VERSION "$Format:%h$"

NS_ :

BS_:

BU_: APB APP APS BCCEN BDY DAS DBG EAS EPAS EPAS2 EPAS3S EPB EPBM ESP GTW GTWU IBST IC MCU OCS PARK PARK3 RADAR RCM RT3000 SCCM SDM SEC TAS TAS2 TAS2DBG TOOL TPMS VCSEATD VCSEATP

BO_ 861 IBST_dtcMatrix: 8 IBST
 SG_ IBST_dtcIndex M : 0|8@1+ (1,0) [0|255] "" GTW
 SG_ IBST_d000_bmsInitTestFail m0 : 8|2@1+ (1,0) [0|0] "" GTW
 SG_ IBST_d001_bmcSingleTransTest m0 : 10|2@1+ (1,0) [0|0] "" GTW
 SG_ IBST_d002_tle5012SsccrcFail m0 : 12|2@1+ (1,0) [0|0] "" GTW
 SG_ IBST_d003_tle5012Config m0 : 14|2@1+ (1,0) [0|0] "" GTW
 SG_ IBST_d004_deadlMonTaskx1Ovr m0 : 16|2@1+ (1,0) [0|0] "" GTW
 SG_ IBST_d005_ecuWdFltCntTstFls m0 : 18|2@1+ (1,0) [0|0] "" GTW
 SG_ IBST_d006_ecuWdScheduleTout m0 : 20|2@1+ (1,0) [0|0] "" GTW
 SG_ IBST_d007_ecuWdStarttestFls m0 : 22|2@1+ (1,0) [0|0] "" GTW
 SG_ IBST_d008_ecuWdStatusContErr m0 : 24|2@1+ (1,0) [0|0] "" GTW
 SG_ IBST_d009_netOvrvolt m0 : 26|2@1+ (1,0) [0|0] "" GTW
 SG_ IBST_d010_micSpiTout m0 : 28|2@1+ (1,0) [0|0] "" GTW
 SG_ IBST_d011_micSpiTransferErr m0 : 30|2@1+ (1,0) [0|0] "" GTW
 SG_ IBST_d012_netUndvolt m0 : 32|2@1+ (1,0) [0|0] "" GTW
 SG_ IBST_d013_xpassToutErr m0 : 34|2@1+ (1,0) [0|0] "" GTW
 SG_ IBST_d014_rpsOffsEeReadEmpty m0 : 36|2@1+ (1,0) [0|0] "" GTW
 SG_ IBST_d015_rtpEnaHigh m0 : 38|2@1+ (1,0) [0|0] "" GTW
 SG_ IBST_d016_xpassEchoCountErr m0 : 40|2@1+ (1,0) [0|0] "" GTW
 SG_ IBST_d017_preDriveChckFail m0 : 42|2@1+ (1,0) [0|0] "" GTW
 SG_ IBST_d018_ucSafetyFlt m0 : 44|2@1+ (1,0) [0|0] "" GTW
 SG_ IBST_d019_unsupportedHw m0 : 46|2@1+ (1,0) [0|0] "" GTW
 SG_ IBST_d020_voltPreRegModeFld m0 : 48|2@1+ (1,0) [0|0] "" GTW
 SG_ IBST_d021_ubbSupplyLine m0 : 50|2@1+ (1,0) [0|0] "" GTW
 SG_ IBST_d022_stmAswSysTout m0 : 52|2@1+ (1,0) [0|0] "" GTW
 SG_ IBST_d023_stackOvrUndFlow m0 : 54|2@1+ (1,0) [0|0] "" GTW
 SG_ IBST_d024_smmOneReqsInit m0 : 56|2@1+ (1,0) [0|0] "" GTW
 SG_ IBST_d025_ptsSupply m0 : 58|2@1+ (1,0) [0|0] "" GTW
 SG_ IBST_d026_ptsSupplyUndvolt m0 : 60|2@1+ (1,0) [0|0] "" GTW
 SG_ IBST_d027_tempB6Plaus m0 : 62|2@1+ (1,0) [0|0] "" GTW
 SG_ IBST_d028_ecuWdErrCntContErr m1 : 8|2@1+ (1,0) [0|0] "" GTW
 SG_ IBST_d029_bmcShortedGateTest m1 : 10|2@1+ (1,0) [0|0] "" GTW
 SG_ IBST_d030_controllerDevTooBig m1 : 12|2@1+ (1,0) [0|0] "" GTW
 SG_ IBST_d031_ibDtrFail m1 : 14|2@1+ (1,0) [0|0] "" GTW
 SG_ IBST_d032_oc6InitTestFail m1 : 16|2@1+ (1,0) [0|0] "" GTW
 SG_ IBST_d033_oc6Monitor m1 : 18|2@1+ (1,0) [0|0] "" GTW
 SG_ IBST_d034_motorOscillationDet m1 : 20|2@1+ (1,0) [0|0] "" GTW
 SG_ IBST_d035_rpsOffsEeReadFail m1 : 22|2@1+ (1,0) [0|0] "" GTW
 SG_ IBST_d036_sysErrHook m1 : 24|2@1+ (1,0) [0|0] "" GTW
 SG_ IBST_d037_calIdlePosNotPlaus m1 : 26|2@1+ (1,0) [0|0] "" GTW
 SG_ IBST_d038_boostSupUndrvolt m1 : 28|2@1+ (1,0) [0|0] "" GTW
 SG_ IBST_d039_calRoutineAbort m1 : 30|2@1+ (1,0) [0|0] "" GTW
 SG_ IBST_d040_bmcGateUndervoltPro m1 : 32|2@1+ (1,0) [0|0] "" GTW
 SG_ IBST_d041_hswInitPhseUndrvolt m1 : 34|2@1+ (1,0) [0|0] "" GTW
 SG_ IBST_d042_ltmWarnLevelReached m1 : 36|2@1+ (1,0) [0|0] "" GTW
 SG_ IBST_d043_rpsVctrLengthRelErr m1 : 38|2@1+ (1,0) [0|0] "" GTW
 SG_ IBST_d044_b6TempDegradeLevel1 m1 : 40|2@1+ (1,0) [0|0] "" GTW
 SG_ IBST_d045_B6TempDegradeLevel2 m1 : 42|2@1+ (1,0) [0|0] "" GTW
 SG_ IBST_d046_spiAnglOrRawNotUp m1 : 44|2@1+ (1,0) [0|0] "" GTW
 SG_ IBST_d047_dcomIboosterNotInit m1 : 46|2@1+ (1,0) [0|0] "" GTW
 SG_ IBST_d048_unintendMotorReturn m1 : 48|2@1+ (1,0) [0|0] "" GTW
 SG_ IBST_d049_cdmOvrvoltLevel1 m1 : 50|2@1+ (1,0) [0|0] "" GTW
 SG_ IBST_d050_cdmUndrvoltLevel2 m1 : 52|2@1+ (1,0) [0|0] "" GTW
 SG_ IBST_d051_cdmUndrvoltLevel1 m1 : 54|2@1+ (1,0) [0|0] "" GTW
 SG_ IBST_d052_motTrvlRelReadFail m1 : 56|2@1+ (1,0) [0|0] "" GTW
 SG_ IBST_d053_tle5012UnexpReset m1 : 58|2@1+ (1,0) [0|0] "" GTW
 SG_ IBST_d054_bmsGateUndrvolt m1 : 60|2@1+ (1,0) [0|0] "" GTW
 SG_ IBST_d055_kl15HwPlausSw m1 : 62|2@1+ (1,0) [0|0] "" GTW
 SG_ IBST_d056_ibNotShutDownRight m2 : 8|2@1+ (1,0) [0|0] "" GTW
 SG_ IBST_d057_cdmHardUndrvolt m2 : 10|2@1+ (1,0) [0|0] "" GTW
 SG_ IBST_d058_cdmHardOvrvolt m2 : 12|2@1+ (1,0) [0|0] "" GTW
 SG_ IBST_d059_maxTrvlAdjstUpdFail m2 : 14|2@1+ (1,0) [0|0] "" GTW
 SG_ IBST_d060_ltmLimitReached m2 : 16|2@1+ (1,0) [0|0] "" GTW
 SG_ IBST_d061_dcomEcuDefect m2 : 18|2@1+ (1,0) [0|0] "" GTW
 SG_ IBST_d062_inputStroke1RngHigh m2 : 20|2@1+ (1,0) [0|0] "" GTW
 SG_ IBST_d063_inputStroke1RngLow m2 : 22|2@1+ (1,0) [0|0] "" GTW
 SG_ IBST_d064_inputStroke2RngHigh m2 : 24|2@1+ (1,0) [0|0] "" GTW
 SG_ IBST_d065_inputStroke2RngLow m2 : 26|2@1+ (1,0) [0|0] "" GTW
 SG_ IBST_d066_ibSupVoltDivDrift m2 : 28|2@1+ (1,0) [0|0] "" GTW
 SG_ IBST_d067_sOutRodToPressVal m2 : 30|2@1+ (1,0) [0|0] "" GTW
 SG_ IBST_d068_tle5012LifeCnt m2 : 32|2@1+ (1,0) [0|0] "" GTW
 SG_ IBST_d069_cdmExtendedUndrvolt m2 : 34|2@1+ (1,0) [0|0] "" GTW
 SG_ IBST_d070_cdmExtendedOvrvolt m2 : 36|2@1+ (1,0) [0|0] "" GTW
 SG_ IBST_d071_tempB6Ch1LineHigh m2 : 38|2@1+ (1,0) [0|0] "" GTW
 SG_ IBST_d072_tempB6Ch1LineLow m2 : 40|2@1+ (1,0) [0|0] "" GTW
 SG_ IBST_d073_tempB6Ch2LineHigh m2 : 42|2@1+ (1,0) [0|0] "" GTW
 SG_ IBST_d074_tempB6Ch2LineLow m2 : 44|2@1+ (1,0) [0|0] "" GTW
 SG_ IBST_d075_hevSwitchOffDcom m2 : 46|2@1+ (1,0) [0|0] "" GTW
 SG_ IBST_d076_tle5012VoltFail m2 : 48|2@1+ (1,0) [0|0] "" GTW
 SG_ IBST_d077_bcsFltCurrentHigh m2 : 50|2@1+ (1,0) [0|0] "" GTW
 SG_ IBST_d078_bcsFltCurrentLow m2 : 52|2@1+ (1,0) [0|0] "" GTW
 SG_ IBST_d079_ecuSupVoltDivDrift m2 : 54|2@1+ (1,0) [0|0] "" GTW
 SG_ IBST_d080_inputstroke1Grad m2 : 56|2@1+ (1,0) [0|0] "" GTW
 SG_ IBST_d081_pts1Err m2 : 58|2@1+ (1,0) [0|0] "" GTW
 SG_ IBST_d082_pts1LineGnd m2 : 60|2@1+ (1,0) [0|0] "" GTW
 SG_ IBST_d083_pts1LineHigh m2 : 62|2@1+ (1,0) [0|0] "" GTW
 SG_ IBST_d084_inputStroke2Grad m3 : 8|2@1+ (1,0) [0|0] "" GTW
 SG_ IBST_d085_pts2Err m3 : 10|2@1+ (1,0) [0|0] "" GTW
 SG_ IBST_d086_pts2LineGnd m3 : 12|2@1+ (1,0) [0|0] "" GTW
 SG_ IBST_d087_pts2LineHigh m3 : 14|2@1+ (1,0) [0|0] "" GTW
 SG_ IBST_d088_faildevInputStroke m3 : 16|2@1+ (1,0) [0|0] "" GTW
 SG_ IBST_d089_ptsOffsTooHigh m3 : 18|2@1+ (1,0) [0|0] "" GTW
 SG_ IBST_d090_pbistErr m3 : 20|2@1+ (1,0) [0|0] "" GTW
 SG_ IBST_d091_ramInitErr m3 : 22|2@1+ (1,0) [0|0] "" GTW
 SG_ IBST_d092_ramsinlgeFlt m3 : 24|2@1+ (1,0) [0|0] "" GTW
 SG_ IBST_d093_bertFlt m3 : 26|2@1+ (1,0) [0|0] "" GTW
 SG_ IBST_d094_CalDataNotPlaus m3 : 28|2@1+ (1,0) [0|0] "" GTW
 SG_ IBST_d095_canEHwError m3 : 30|2@1+ (1,0) [0|0] "" GTW
 SG_ IBST_d096_canETout m3 : 32|2@1+ (1,0) [0|0] "" GTW
 SG_ IBST_d097_cpuException m3 : 34|2@1+ (1,0) [0|0] "" GTW
 SG_ IBST_d098_ecuBandGap m3 : 36|2@1+ (1,0) [0|0] "" GTW
 SG_ IBST_d099_ecuBmsOnWhileWdTout m3 : 38|2@1+ (1,0) [0|0] "" GTW
 SG_ IBST_d100_ecuErrpinCntTstFls m3 : 40|2@1+ (1,0) [0|0] "" GTW
 SG_ IBST_d101_ecuHetException m3 : 42|2@1+ (1,0) [0|0] "" GTW
 SG_ IBST_d102_ecuHetTuAddErr m3 : 44|2@1+ (1,0) [0|0] "" GTW
 SG_ IBST_d103_ecuHetTuBusErr m3 : 46|2@1+ (1,0) [0|0] "" GTW
 SG_ IBST_d104_ecuHetTuBusyErr m3 : 48|2@1+ (1,0) [0|0] "" GTW
 SG_ IBST_d105_ecuHetTuException m3 : 50|2@1+ (1,0) [0|0] "" GTW
 SG_ IBST_d106_ecuTaskMissing m3 : 52|2@1+ (1,0) [0|0] "" GTW
 SG_ IBST_d107_hetRefError m3 : 54|2@1+ (1,0) [0|0] "" GTW
 SG_ IBST_d108_micInitSpiTstFld m3 : 56|2@1+ (1,0) [0|0] "" GTW
 SG_ IBST_d109_micInitSpiTransfErr m3 : 58|2@1+ (1,0) [0|0] "" GTW
 SG_ IBST_d110_micIntMonGenBitMon m3 : 60|2@1+ (1,0) [0|0] "" GTW
 SG_ IBST_d111_micIntVoltMonFld m3 : 62|2@1+ (1,0) [0|0] "" GTW
 SG_ IBST_d112_motPosTrvlReadEmpty m4 : 8|2@1+ (1,0) [0|0] "" GTW
 SG_ IBST_d113_motAngBoundReadEmpt m4 : 10|2@1+ (1,0) [0|0] "" GTW
 SG_ IBST_d114_motShaftShiftDetect m4 : 12|2@1+ (1,0) [0|0] "" GTW
 SG_ IBST_d115_osErrHook m4 : 14|2@1+ (1,0) [0|0] "" GTW
 SG_ IBST_d116_pdurEInitFail m4 : 16|2@1+ (1,0) [0|0] "" GTW
 SG_ IBST_d117_pdurEPduInstLost m4 : 18|2@1+ (1,0) [0|0] "" GTW
 SG_ IBST_d118_pts1OffsEeReadEmpty m4 : 20|2@1+ (1,0) [0|0] "" GTW
 SG_ IBST_d119_pts2OffsEeReadEmpty m4 : 22|2@1+ (1,0) [0|0] "" GTW
 SG_ IBST_d120_rpsOffsXEeReadFail m4 : 24|2@1+ (1,0) [0|0] "" GTW
 SG_ IBST_d121_rpsOffsYEeReadFail m4 : 26|2@1+ (1,0) [0|0] "" GTW
 SG_ IBST_d122_rpsSynchEeReadFail m4 : 28|2@1+ (1,0) [0|0] "" GTW
 SG_ IBST_d123_rpsAnglRecalcErr m4 : 30|2@1+ (1,0) [0|0] "" GTW
 SG_ IBST_d124_motTrvlRelWriteFail m4 : 32|2@1+ (1,0) [0|0] "" GTW
 SG_ IBST_d125_motTrvlRelReadEmpty m4 : 34|2@1+ (1,0) [0|0] "" GTW
 SG_ IBST_d126_ptsEeReadEmpty m4 : 36|2@1+ (1,0) [0|0] "" GTW
 SG_ IBST_d127_ecuAdcConversionErr m4 : 38|2@1+ (1,0) [0|0] "" GTW
 SG_ IBST_d128_ecuAdcSelftestErr m4 : 40|2@1+ (1,0) [0|0] "" GTW
 SG_ IBST_d129_ccmFlt m4 : 42|2@1+ (1,0) [0|0] "" GTW
 SG_ IBST_d130_ecuRomCheck m4 : 44|2@1+ (1,0) [0|0] "" GTW
 SG_ IBST_d131_esmNmiFlt m4 : 46|2@1+ (1,0) [0|0] "" GTW
 SG_ IBST_d132_esmSafetyFlt m4 : 48|2@1+ (1,0) [0|0] "" GTW
 SG_ IBST_d133_motPosTrvlReadFail m4 : 50|2@1+ (1,0) [0|0] "" GTW
 SG_ IBST_d134_motPosTrvlWriteFail m4 : 52|2@1+ (1,0) [0|0] "" GTW
 SG_ IBST_d135_motAnglBndReadErr m4 : 54|2@1+ (1,0) [0|0] "" GTW
 SG_ IBST_d136_motAnglBndWriteErr m4 : 56|2@1+ (1,0) [0|0] "" GTW
 SG_ IBST_d137_motAnglGradTooLarge m4 : 58|2@1+ (1,0) [0|0] "" GTW
 SG_ IBST_d138_pdmCustomerIdMis m4 : 60|2@1+ (1,0) [0|0] "" GTW
 SG_ IBST_d139_pdmDtFormatMis m4 : 62|2@1+ (1,0) [0|0] "" GTW
 SG_ IBST_d140_pdmOutOfMemory m5 : 8|2@1+ (1,0) [0|0] "" GTW
 SG_ IBST_d141_pdmFieldSizeMis m5 : 10|2@1+ (1,0) [0|0] "" GTW
 SG_ IBST_d142_pdmHwAcsErr m5 : 12|2@1+ (1,0) [0|0] "" GTW
 SG_ IBST_d143_pdmInternalHWErr m5 : 14|2@1+ (1,0) [0|0] "" GTW
 SG_ IBST_d144_ptsCalHysWritFail m5 : 16|2@1+ (1,0) [0|0] "" GTW
 SG_ IBST_d145_ptsCalValuesChkFail m5 : 18|2@1+ (1,0) [0|0] "" GTW
 SG_ IBST_d146_pts1CalEeReadFail m5 : 20|2@1+ (1,0) [0|0] "" GTW
 SG_ IBST_d147_pts1CalEeWriteFail m5 : 22|2@1+ (1,0) [0|0] "" GTW
 SG_ IBST_d148_rpsFailCompErr m5 : 24|2@1+ (1,0) [0|0] "" GTW
 SG_ IBST_d149_pts1OffsEeWriteFail m5 : 26|2@1+ (1,0) [0|0] "" GTW
 SG_ IBST_d150_pts2CalEeReadFail m5 : 28|2@1+ (1,0) [0|0] "" GTW
 SG_ IBST_d151_pts2CalEeWriteFail m5 : 30|2@1+ (1,0) [0|0] "" GTW
 SG_ IBST_d152_pts2OffsEeReadFail m5 : 32|2@1+ (1,0) [0|0] "" GTW
 SG_ IBST_d153_pts2OffsEeWriteFail m5 : 34|2@1+ (1,0) [0|0] "" GTW
 SG_ IBST_d154_rpsOffsXEeReadEmpty m5 : 36|2@1+ (1,0) [0|0] "" GTW
 SG_ IBST_d155_rpsOffsXEeWriteFail m5 : 38|2@1+ (1,0) [0|0] "" GTW
 SG_ IBST_d156_rpsOffsYEeReadEmpty m5 : 40|2@1+ (1,0) [0|0] "" GTW
 SG_ IBST_d157_rpsOffsYEeWriteFail m5 : 42|2@1+ (1,0) [0|0] "" GTW
 SG_ IBST_d158_rpsSynchEeReadEmpty m5 : 44|2@1+ (1,0) [0|0] "" GTW
 SG_ IBST_d159_rpsSynchEeWriteFail m5 : 46|2@1+ (1,0) [0|0] "" GTW
 SG_ IBST_d160_assertionFail m5 : 48|2@1+ (1,0) [0|0] "" GTW
 SG_ IBST_d161_comsclBrkPrsPduLen m5 : 50|2@1+ (1,0) [0|0] "" GTW
 SG_ IBST_d162_comsclBrkPrsPduTout m5 : 52|2@1+ (1,0) [0|0] "" GTW
 SG_ IBST_d163_comsclEspIb1CntErr m5 : 54|2@1+ (1,0) [0|0] "" GTW
 SG_ IBST_d164_comsclEspIb1CsErr m5 : 56|2@1+ (1,0) [0|0] "" GTW
 SG_ IBST_d165_comsclEspIb1DlcErr m5 : 58|2@1+ (1,0) [0|0] "" GTW
 SG_ IBST_d166_comsclEspIb1Tout m5 : 60|2@1+ (1,0) [0|0] "" GTW
 SG_ IBST_d167_comsclEspIb2CntErr m5 : 62|2@1+ (1,0) [0|0] "" GTW
 SG_ IBST_d168_comsclEspIb2CsErr m6 : 8|2@1+ (1,0) [0|0] "" GTW
 SG_ IBST_d169_comsclEspIb2DlcErr m6 : 10|2@1+ (1,0) [0|0] "" GTW
 SG_ IBST_d170_comsclEspIb2Tout m6 : 12|2@1+ (1,0) [0|0] "" GTW
 SG_ IBST_d171_comsclEspIb3CntErr m6 : 14|2@1+ (1,0) [0|0] "" GTW
 SG_ IBST_d172_comsclEspIb3CsErr m6 : 16|2@1+ (1,0) [0|0] "" GTW
 SG_ IBST_d173_comsclEspIb3DlcErr m6 : 18|2@1+ (1,0) [0|0] "" GTW
 SG_ IBST_d174_comsclEspIb3Tout m6 : 20|2@1+ (1,0) [0|0] "" GTW
 SG_ IBST_d175_comsclGtwEsp1CntErr m6 : 22|2@1+ (1,0) [0|0] "" GTW
 SG_ IBST_d176_comsclGtwEsp1CsErr m6 : 24|2@1+ (1,0) [0|0] "" GTW
 SG_ IBST_d177_comsclGtwEsp1Corrpt m6 : 26|2@1+ (1,0) [0|0] "" GTW
 SG_ IBST_d178_comsclGtwEsp1Tout m6 : 28|2@1+ (1,0) [0|0] "" GTW
 SG_ IBST_d179_dcomSmrtActuNotInit m6 : 30|2@1+ (1,0) [0|0] "" GTW
 SG_ IBST_d180_rpsLengthAbsolHigh m6 : 32|2@1+ (1,0) [0|0] "" GTW
 SG_ IBST_d181_rpsLengthAbsolLow m6 : 34|2@1+ (1,0) [0|0] "" GTW
 SG_ IBST_d182_shutDownEeReadFail m6 : 36|2@1+ (1,0) [0|0] "" GTW
 SG_ IBST_d183_shutDownEeWriteFail m6 : 38|2@1+ (1,0) [0|0] "" GTW
 SG_ IBST_d184_maxTrvlAdjstReadErr m6 : 40|2@1+ (1,0) [0|0] "" GTW
 SG_ IBST_d185_psOffsMcEeReadFail m6 : 42|2@1+ (1,0) [0|0] "" GTW
 SG_ IBST_d186_psOffsMcEeWriteFail m6 : 44|2@1+ (1,0) [0|0] "" GTW
 SG_ IBST_d187_ltmSelfProtDeact m6 : 46|2@1+ (1,0) [0|0] "" GTW
 SG_ IBST_d188_pts1OffsEeReadFail m6 : 48|2@1+ (1,0) [0|0] "" GTW
 SG_ IBST_d189_diffStrokeRange m6 : 50|2@1+ (1,0) [0|0] "" GTW
 SG_ IBST_d190_notProgVin m6 : 52|2@1+ (1,0) [0|0] "" GTW
 SG_ IBST_d191_plausVin m6 : 54|2@1+ (1,0) [0|0] "" GTW
 SG_ IBST_d192_dlCorCSumVin m6 : 56|2@1+ (1,0) [0|0] "" GTW
 SG_ IBST_d193_ToutVin m6 : 58|2@1+ (1,0) [0|0] "" GTW
 SG_ IBST_d194_ecuEnableB6Fail m6 : 60|2@1+ (1,0) [0|0] "" GTW
 SG_ IBST_d195_ecuIbEnContErr m6 : 62|2@1+ (1,0) [0|0] "" GTW
 SG_ IBST_d196_sclEspIb1pEstMax m7 : 8|2@1+ (1,0) [0|0] "" GTW
 SG_ IBST_d197_sclEspIb1VehSpd m7 : 10|2@1+ (1,0) [0|0] "" GTW
 SG_ IBST_d198_sclEspIb2pLimExt m7 : 12|2@1+ (1,0) [0|0] "" GTW
 SG_ IBST_d199_sclEspIb2qTarExt m7 : 14|2@1+ (1,0) [0|0] "" GTW
 SG_ IBST_d200_sclEspIb3pFBlend m7 : 16|2@1+ (1,0) [0|0] "" GTW
 SG_ IBST_d201_sclEspIb3pMc1 m7 : 18|2@1+ (1,0) [0|0] "" GTW
 SG_ IBST_d202_sclEspIb3pTarDriver m7 : 20|2@1+ (1,0) [0|0] "" GTW
 SG_ IBST_d203_netBusOffNet0 m7 : 22|2@1+ (1,0) [0|0] "" GTW
 SG_ IBST_d204_netErrPassivNet0 m7 : 24|2@1+ (1,0) [0|0] "" GTW
 SG_ IBST_d205_netBusOffNet1 m7 : 26|2@1+ (1,0) [0|0] "" GTW
 SG_ IBST_d206_netErrPassivNet1 m7 : 28|2@1+ (1,0) [0|0] "" GTW
 SG_ IBST_d207_maxStrokeReached m7 : 30|2@1+ (1,0) [0|0] "" GTW
 SG_ IBST_d208_sysSwClockMismatch m7 : 32|2@1+ (1,0) [0|0] "" GTW
 SG_ IBST_d209_comsclGtwOdoCorrpt m7 : 34|2@1+ (1,0) [0|0] "" GTW
 SG_ IBST_d210_comsclGtwStatCorrpt m7 : 36|2@1+ (1,0) [0|0] "" GTW
 SG_ IBST_d211_comsclEpbStatCorrpt m7 : 38|2@1+ (1,0) [0|0] "" GTW
 SG_ IBST_d212_comsclGtwOdoTout m7 : 40|2@1+ (1,0) [0|0] "" GTW
 SG_ IBST_d213_comsclGtwStatTout m7 : 42|2@1+ (1,0) [0|0] "" GTW
 SG_ IBST_d214_comsclEpbStatTout m7 : 44|2@1+ (1,0) [0|0] "" GTW
 SG_ IBST_d215_comSclEpbStatCsErr m7 : 46|2@1+ (1,0) [0|0] "" GTW
 SG_ IBST_d216_comSclEpbStatCntFlt m7 : 48|2@1+ (1,0) [0|0] "" GTW
 SG_ IBST_d217_comSclDiTrq1Tout m7 : 50|2@1+ (1,0) [0|0] "" GTW
 SG_ IBST_d218_comSclDiTrq1Corrpt m7 : 52|2@1+ (1,0) [0|0] "" GTW
 SG_ IBST_d219_comSclDiTrq1CsErr m7 : 54|2@1+ (1,0) [0|0] "" GTW
 SG_ IBST_d220_comSclDiTrq1CntFlt m7 : 56|2@1+ (1,0) [0|0] "" GTW

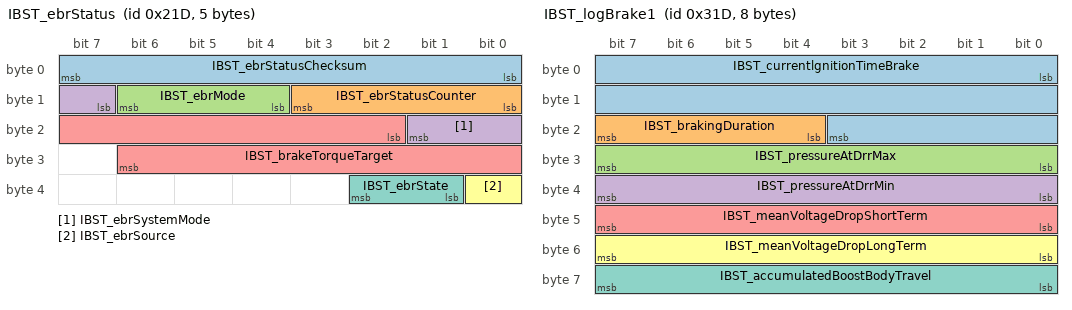
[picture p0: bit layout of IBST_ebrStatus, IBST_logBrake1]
BO_ 541 IBST_ebrStatus: 5 IBST
 SG_ IBST_ebrStatusChecksum : 0|8@1+ (1,0) [0|255] "" GTW
 SG_ IBST_ebrStatusCounter : 8|4@1+ (1,0) [0|15] "" GTW
 SG_ IBST_ebrMode : 12|3@1+ (1,0) [0|7] "" GTW
 SG_ IBST_ebrSystemMode : 15|3@1+ (1,0) [0|7] "" GTW
 SG_ IBST_brakeTorqueTarget : 18|13@1+ (2,0) [0|16382] "Nm" GTW
 SG_ IBST_ebrSource : 32|1@1+ (1,0) [0|2] "" GTW
 SG_ IBST_ebrState : 33|2@1+ (1,0) [0|3] "" GTW

BO_ 813 IBST_info: 8 IBST
 SG_ IBST_infoIndex M : 0|8@1+ (1,0) [0|255] "" GTW,GTWU
 SG_ IBST_buildType m10 : 8|8@1+ (1,0) [0|255] "" GTW
 SG_ IBST_componentId m10 : 48|16@1+ (1,0) [0|65535] "" GTW
 SG_ IBST_pcbaId m11 : 16|8@1+ (1,0) [0|0] "" GTW,GTWU
 SG_ IBST_assemblyId m11 : 24|8@1+ (1,0) [0|0] "" GTW,GTWU
 SG_ IBST_usageId m11 : 32|16@1+ (1,0) [0|0] "" GTW,GTWU
 SG_ IBST_applicationCrc m13 : 32|32@1+ (1,0) [0|0] "" GTW,GTWU
 SG_ IBST_udsProtocolVersion m20 : 8|8@1+ (1,0) [0|0] "" GTW,GTWU
 SG_ IBST_bootloaderCrc m20 : 32|32@1+ (1,0) [0|0] "" GTW
 SG_ IBST_variantCrc m22 : 32|32@1+ (1,0) [0|0] "" GTW,GTWU

BO_ 797 IBST_logBrake1: 8 IBST
 SG_ IBST_currentlgnitionTimeBrake : 0|20@1+ (0.1,0) [0|86400] "sec" Vector__XXX
 SG_ IBST_brakingDuration : 20|4@1+ (1,0) [0|15] "" Vector__XXX
 SG_ IBST_pressureAtDrrMax : 24|8@1+ (1,0) [0|250] "bar" Vector__XXX
 SG_ IBST_pressureAtDrrMin : 32|8@1+ (1,0) [0|250] "bar" Vector__XXX
 SG_ IBST_meanVoltageDropShortTerm : 40|8@1+ (0.01,0) [0|1.5] "V" Vector__XXX
 SG_ IBST_meanVoltageDropLongTerm : 48|8@1+ (0.01,0) [0|1.5] "V" Vector__XXX
 SG_ IBST_accumulatedBoostBodyTravel : 56|8@1+ (10,0) [0|2550] "mm" Vector__XXX

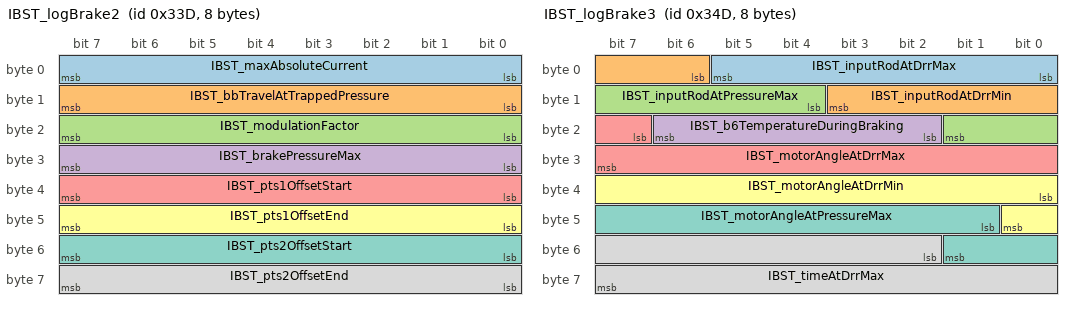
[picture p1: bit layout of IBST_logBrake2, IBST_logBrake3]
BO_ 829 IBST_logBrake2: 8 IBST
 SG_ IBST_maxAbsoluteCurrent : 0|8@1+ (1,0) [0|255] "A" Vector__XXX
 SG_ IBST_bbTravelAtTrappedPressure : 8|8@1+ (0.1,0) [0|20] "mm" Vector__XXX
 SG_ IBST_modulationFactor : 16|8@1+ (0.1,0) [0|25.5] "1" Vector__XXX
 SG_ IBST_brakePressureMax : 24|8@1+ (1,0) [0|250] "bar" Vector__XXX
 SG_ IBST_pts1OffsetStart : 32|8@1+ (0.01,-0.5) [-0.5|1] "mm" Vector__XXX
 SG_ IBST_pts1OffsetEnd : 40|8@1+ (0.01,-0.5) [-0.5|1] "mm" Vector__XXX
 SG_ IBST_pts2OffsetStart : 48|8@1+ (0.01,-0.5) [-0.5|1] "mm" Vector__XXX
 SG_ IBST_pts2OffsetEnd : 56|8@1+ (0.01,-0.5) [-0.5|1] "mm" Vector__XXX

BO_ 845 IBST_logBrake3: 8 IBST
 SG_ IBST_inputRodAtDrrMax : 0|6@1+ (1,0) [0|50] "mm" Vector__XXX
 SG_ IBST_inputRodAtDrrMin : 6|6@1+ (1,0) [0|50] "mm" Vector__XXX
 SG_ IBST_inputRodAtPressureMax : 12|6@1+ (1,0) [0|50] "mm" Vector__XXX
 SG_ IBST_b6TemperatureDuringBraking : 18|5@1+ (10,-40) [-40|150] "C" Vector__XXX
 SG_ IBST_motorAngleAtDrrMax : 23|9@1+ (0.25,0) [0|127] "rad" Vector__XXX
 SG_ IBST_motorAngleAtDrrMin : 32|9@1+ (0.25,0) [0|127] "rad" Vector__XXX
 SG_ IBST_motorAngleAtPressureMax : 41|9@1+ (0.25,0) [0|127] "rad" Vector__XXX
 SG_ IBST_timeAtDrrMax : 50|14@1+ (0.2,0) [0|1800] "sec" Vector__XXX

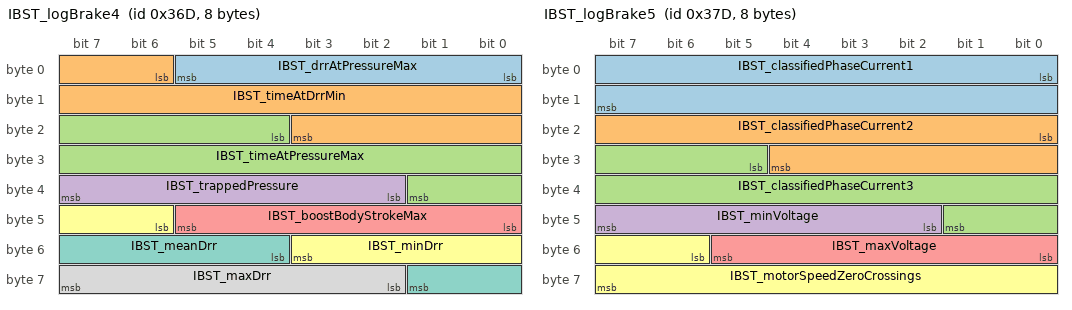
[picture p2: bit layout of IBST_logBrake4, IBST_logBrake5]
BO_ 877 IBST_logBrake4: 8 IBST
 SG_ IBST_drrAtPressureMax : 0|6@1+ (0.1,-3) [-3|3] "mm" Vector__XXX
 SG_ IBST_timeAtDrrMin : 6|14@1+ (0.2,0) [0|1800] "sec" Vector__XXX
 SG_ IBST_timeAtPressureMax : 20|14@1+ (0.2,0) [0|1800] "sec" Vector__XXX
 SG_ IBST_trappedPressure : 34|6@1+ (0.5,0) [0|20] "bar" Vector__XXX
 SG_ IBST_boostBodyStrokeMax : 40|6@1+ (1,0) [0|50] "mm" Vector__XXX
 SG_ IBST_minDrr : 46|6@1+ (0.1,-3) [-3|3] "mm" Vector__XXX
 SG_ IBST_meanDrr : 52|6@1+ (0.1,-3) [-3|3] "mm" Vector__XXX
 SG_ IBST_maxDrr : 58|6@1+ (0.1,-3) [-3|3] "mm" Vector__XXX

BO_ 893 IBST_logBrake5: 8 IBST
 SG_ IBST_classifiedPhaseCurrent1 : 0|16@1+ (1,0) [0|65535] "" Vector__XXX
 SG_ IBST_classifiedPhaseCurrent2 : 16|13@1+ (1,0) [0|8191] "" Vector__XXX
 SG_ IBST_classifiedPhaseCurrent3 : 29|13@1+ (1,0) [0|8191] "" Vector__XXX
 SG_ IBST_minVoltage : 42|6@1+ (0.5,0) [0|20] "V" Vector__XXX
 SG_ IBST_maxVoltage : 48|6@1+ (0.5,0) [0|20] "V" Vector__XXX
 SG_ IBST_motorSpeedZeroCrossings : 54|10@1+ (1,0) [0|1000] "" Vector__XXX

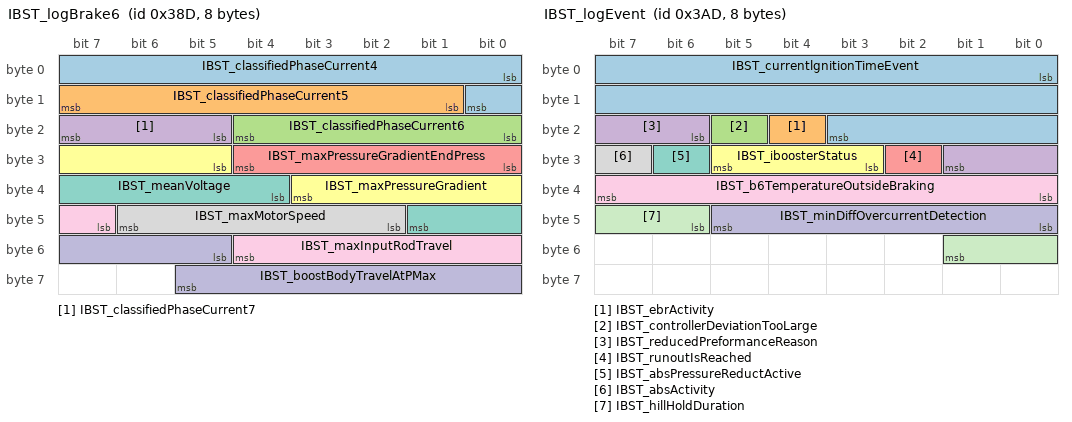
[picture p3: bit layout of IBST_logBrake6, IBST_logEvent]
BO_ 909 IBST_logBrake6: 8 IBST
 SG_ IBST_classifiedPhaseCurrent4 : 0|9@1+ (1,0) [0|511] "" Vector__XXX
 SG_ IBST_classifiedPhaseCurrent5 : 9|7@1+ (1,0) [0|127] "" Vector__XXX
 SG_ IBST_classifiedPhaseCurrent6 : 16|5@1+ (1,0) [0|31] "" Vector__XXX
 SG_ IBST_classifiedPhaseCurrent7 : 21|3@1+ (1,0) [0|7] "" Vector__XXX
 SG_ IBST_maxPressureGradientEndPress : 24|5@1+ (10,0) [0|200] "bar" Vector__XXX
 SG_ IBST_maxPressureGradient : 29|7@1+ (20,0) [0|2000] "bar/s" Vector__XXX
 SG_ IBST_meanVoltage : 36|6@1+ (0.5,0) [0|20] "V" Vector__XXX
 SG_ IBST_maxMotorSpeed : 42|5@1+ (20,0) [0|600] "rad/s" Vector__XXX
 SG_ IBST_maxInputRodTravel : 47|6@1+ (1,0) [0|50] "mm" Vector__XXX
 SG_ IBST_boostBodyTravelAtPMax : 53|9@1+ (0.1,0) [0|50] "mm" Vector__XXX

BO_ 941 IBST_logEvent: 8 IBST
 SG_ IBST_currentlgnitionTimeEvent : 0|20@1+ (0.1,0) [0|86400] "sec" Vector__XXX
 SG_ IBST_ebrActivity : 20|1@1+ (1,0) [0|1] "" Vector__XXX
 SG_ IBST_controllerDeviationTooLarge : 21|1@1+ (1,0) [0|1] "" Vector__XXX
 SG_ IBST_reducedPreformanceReason : 22|4@1+ (1,0) [0|15] "" Vector__XXX
 SG_ IBST_runoutIsReached : 26|1@1+ (1,0) [0|1] "" Vector__XXX
 SG_ IBST_iboosterStatus : 27|3@1+ (1,0) [0|7] "" Vector__XXX
 SG_ IBST_absPressureReductActive : 30|1@1+ (1,0) [0|1] "" Vector__XXX
 SG_ IBST_absActivity : 31|1@1+ (1,0) [0|1] "" Vector__XXX
 SG_ IBST_b6TemperatureOutsideBraking : 32|8@1+ (10,-40) [-40|150] "C" Vector__XXX
 SG_ IBST_minDiffOvercurrentDetection : 40|6@1+ (0.00390625,0) [0|0.203125] "V" Vector__XXX
 SG_ IBST_hillHoldDuration : 46|4@1+ (0.2,0) [0|2] "sec" Vector__XXX

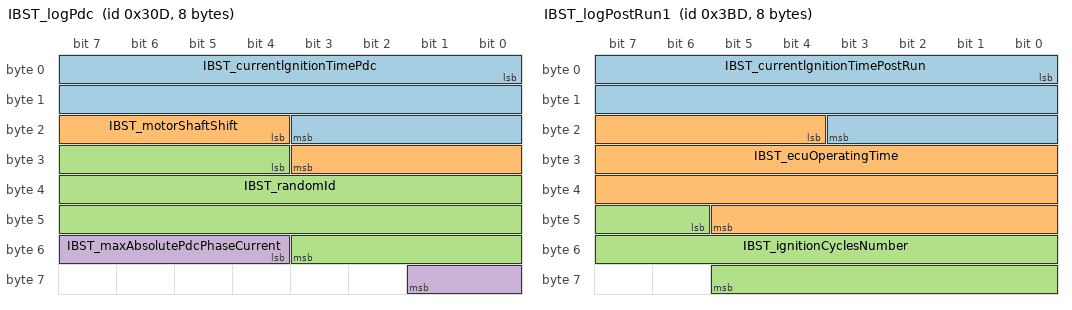
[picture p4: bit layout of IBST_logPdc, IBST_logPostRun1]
BO_ 781 IBST_logPdc: 8 IBST
 SG_ IBST_currentlgnitionTimePdc : 0|20@1+ (0.1,0) [0|86400] "sec" Vector__XXX
 SG_ IBST_motorShaftShift : 20|8@1+ (10,-60) [-60|2490] "deg" Vector__XXX
 SG_ IBST_randomId : 28|24@1+ (1,0) [0|16777215] "" Vector__XXX
 SG_ IBST_maxAbsolutePdcPhaseCurrent : 52|6@1+ (1,0) [0|50] "A" Vector__XXX

BO_ 957 IBST_logPostRun1: 8 IBST
 SG_ IBST_currentlgnitionTimePostRun : 0|20@1+ (0.1,0) [0|86400] "sec" Vector__XXX
 SG_ IBST_ecuOperatingTime : 20|26@1+ (1,0) [0|67108863] "sec" Vector__XXX
 SG_ IBST_ignitionCyclesNumber : 46|16@1+ (1,0) [0|65535] "" Vector__XXX

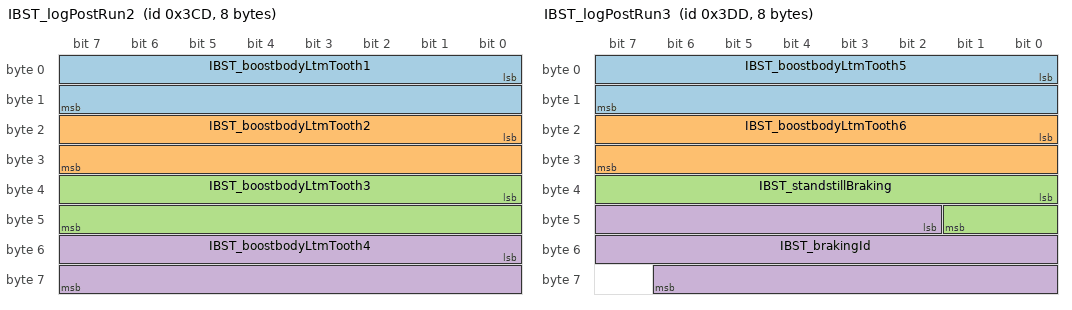
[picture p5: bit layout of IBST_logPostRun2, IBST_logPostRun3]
BO_ 973 IBST_logPostRun2: 8 IBST
 SG_ IBST_boostbodyLtmTooth1 : 0|16@1+ (0.0039,0) [0|255] "1" Vector__XXX
 SG_ IBST_boostbodyLtmTooth2 : 16|16@1+ (0.0039,0) [0|255] "1" Vector__XXX
 SG_ IBST_boostbodyLtmTooth3 : 32|16@1+ (0.0039,0) [0|255] "1" Vector__XXX
 SG_ IBST_boostbodyLtmTooth4 : 48|16@1+ (0.0039,0) [0|255] "1" Vector__XXX

BO_ 989 IBST_logPostRun3: 8 IBST
 SG_ IBST_boostbodyLtmTooth5 : 0|16@1+ (0.0039,0) [0|255] "1" Vector__XXX
 SG_ IBST_boostbodyLtmTooth6 : 16|16@1+ (0.0039,0) [0|255] "1" Vector__XXX
 SG_ IBST_standstillBraking : 32|10@1+ (1,0) [0|1000] "" Vector__XXX
 SG_ IBST_brakingId : 42|21@1+ (1,0) [0|2000000] "" Vector__XXX

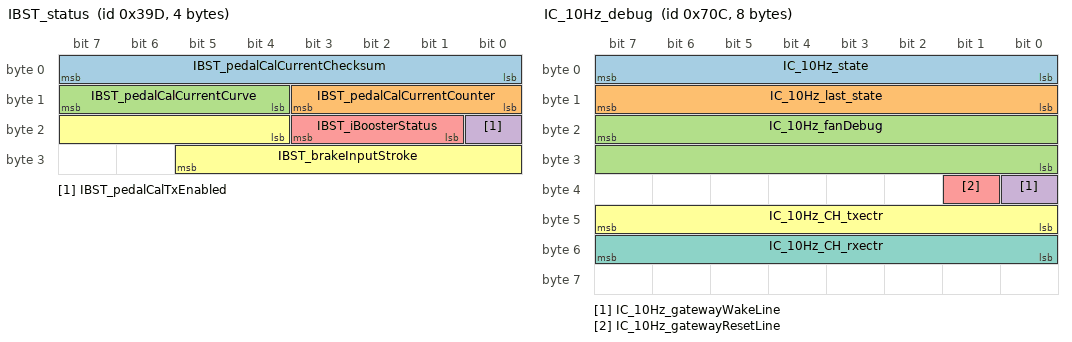
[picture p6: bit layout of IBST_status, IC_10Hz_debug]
BO_ 925 IBST_status: 4 IBST
 SG_ IBST_pedalCalCurrentChecksum : 0|8@1+ (1,0) [0|255] "" GTW
 SG_ IBST_pedalCalCurrentCounter : 8|4@1+ (1,0) [0|15] "" GTW
 SG_ IBST_pedalCalCurrentCurve : 12|4@1+ (1,0) [0|15] "1" GTW
 SG_ IBST_pedalCalTxEnabled : 16|1@1+ (1,0) [0|1] "1" GTW
 SG_ IBST_iBoosterStatus : 17|3@1+ (1,0) [0|0] "" GTW
 SG_ IBST_brakeInputStroke : 20|10@1+ (0.05,-0.5) [-0.5|50.55] "mm" GTW

BO_ 1629 IBST_udsResponse: 8 IBST
 SG_ IBST_udsResponseData : 7|64@0+ (1,0) [0|0] "" GTW,GTWU

BO_ 1804 IC_10Hz_debug: 8 IC
 SG_ IC_10Hz_state : 7|8@0+ (1,0) [0|0] "" DBG
 SG_ IC_10Hz_last_state : 15|8@0+ (1,0) [0|0] "" DBG
 SG_ IC_10Hz_fanDebug : 23|16@0+ (1,0) [0|0] "" DBG
 SG_ IC_10Hz_gatewayWakeLine : 32|1@1+ (1,0) [0|0] "" DBG
 SG_ IC_10Hz_gatewayResetLine : 33|1@1+ (1,0) [0|0] "" DBG
 SG_ IC_10Hz_CH_txectr : 40|8@1+ (1,0) [0|0] "" DBG
 SG_ IC_10Hz_CH_rxectr : 48|8@1+ (1,0) [0|0] "" DBG

BO_ 1420 IC_alertLog: 8 IC
 SG_ IC_alertID M : 0|14@1+ (1,0) [0|0] "" GTW
 SG_ IC_alertType : 14|2@1+ (1,0) [0|0] "" GTW
 SG_ IC_canAddress m3 : 16|12@1+ (1,0) [0|0] "" GTW
 SG_ IC_canErrorType m3 : 28|4@1+ (1,0) [0|0] "" GTW
 SG_ IC_canErrorWord1 m3 : 32|16@1+ (1,0) [0|0] "" GTW
 SG_ IC_canErrorWord2 m3 : 48|16@1+ (1,0) [0|0] "" GTW
 SG_ IC_canRxErrorCount m11 : 16|8@1+ (1,0) [0|0] "" GTW
 SG_ IC_canTxErrorCount m12 : 16|8@1+ (1,0) [0|0] "" GTW

BO_ 1532 IC_bootID: 8 IC
 SG_ IC_bootIdData : 0|64@1+ (1,0) [0|0] "" GTWU

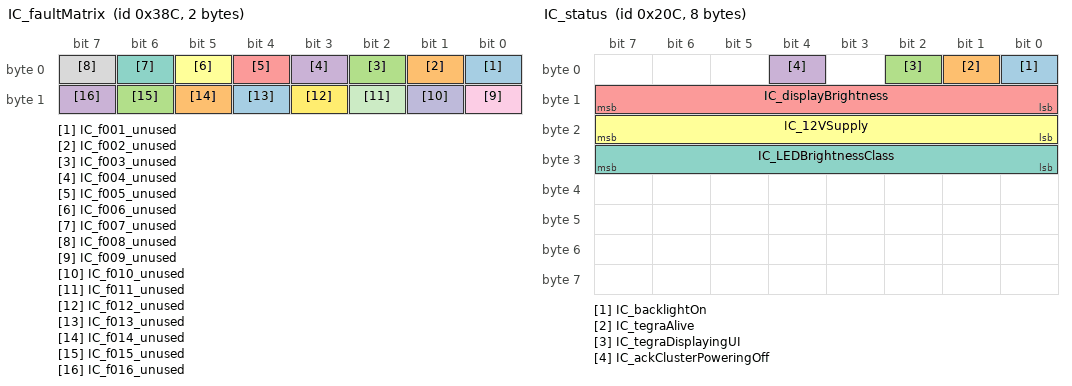
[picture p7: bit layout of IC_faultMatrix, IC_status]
BO_ 908 IC_faultMatrix: 2 IC
 SG_ IC_f001_unused : 0|1@1+ (1,0) [0|0] "" GTW
 SG_ IC_f002_unused : 1|1@1+ (1,0) [0|0] "" GTW
 SG_ IC_f003_unused : 2|1@1+ (1,0) [0|0] "" GTW
 SG_ IC_f004_unused : 3|1@1+ (1,0) [0|0] "" GTW
 SG_ IC_f005_unused : 4|1@1+ (1,0) [0|0] "" GTW
 SG_ IC_f006_unused : 5|1@1+ (1,0) [0|0] "" GTW
 SG_ IC_f007_unused : 6|1@1+ (1,0) [0|0] "" GTW
 SG_ IC_f008_unused : 7|1@1+ (1,0) [0|0] "" GTW
 SG_ IC_f009_unused : 8|1@1+ (1,0) [0|0] "" GTW
 SG_ IC_f010_unused : 9|1@1+ (1,0) [0|0] "" GTW
 SG_ IC_f011_unused : 10|1@1+ (1,0) [0|0] "" GTW
 SG_ IC_f012_unused : 11|1@1+ (1,0) [0|0] "" GTW
 SG_ IC_f013_unused : 12|1@1+ (1,0) [0|0] "" GTW
 SG_ IC_f014_unused : 13|1@1+ (1,0) [0|0] "" GTW
 SG_ IC_f015_unused : 14|1@1+ (1,0) [0|0] "" GTW
 SG_ IC_f016_unused : 15|1@1+ (1,0) [0|0] "" GTW

BO_ 812 IC_info: 8 IC
 SG_ IC_infoIndex M : 0|8@1+ (1,0) [0|255] "" GTW,GTWU
 SG_ IC_buildType m10 : 8|8@1+ (1,0) [0|0] "" GTW
 SG_ IC_buildConfigurationId m10 : 16|16@1+ (1,0) [0|0] "" GTW
 SG_ IC_hardwareId m10 : 32|16@1+ (1,0) [0|0] "" GTW
 SG_ IC_componentId m10 : 48|16@1+ (1,0) [0|0] "" GTW
 SG_ IC_pcbaId m11 : 16|8@1+ (1,0) [0|0] "" GTW,GTWU
 SG_ IC_assemblyId m11 : 24|8@1+ (1,0) [0|0] "" GTW,GTWU
 SG_ IC_usageId m11 : 32|16@1+ (1,0) [0|0] "" GTW,GTWU
 SG_ IC_subUsageId m11 : 48|16@1+ (1,0) [0|0] "" GTW
 SG_ IC_applicationCrc m13 : 32|32@1+ (1,0) [0|0] "" GTW,GTWU
 SG_ IC_FPGA_version m16 : 16|8@1+ (1,0) [0|0] "" GTW,GTWU
 SG_ IC_platformTyp m19 : 8|8@1+ (1,0) [0|0] "" GTW
 SG_ IC_infoBootLdUdsProtocolVersion m20 : 8|8@1+ (1,0) [0|0] "" GTW,GTWU
 SG_ IC_bootloaderCrc m20 : 32|32@1+ (1,0) [0|0] "" GTW

BO_ 524 IC_status: 8 IC
 SG_ IC_backlightOn : 0|1@1+ (1,0) [0|0] "" GTW
 SG_ IC_tegraAlive : 1|1@1+ (1,0) [0|0] "" GTW
 SG_ IC_tegraDisplayingUI : 2|1@1+ (1,0) [0|0] "" GTW
 SG_ IC_ackClusterPoweringOff : 4|1@1+ (1,0) [0|0] "" GTW
 SG_ IC_displayBrightness : 8|8@1+ (0.5,0) [0|127.5] "%" GTW
 SG_ IC_12VSupply : 16|8@1+ (0.1,0) [0|25.5] "V" GTW
 SG_ IC_LEDBrightnessClass : 24|8@1+ (1,0) [0|0] "" GTW

BO_ 1628 IC_udsResponse: 8 IC
 SG_ IC_udsResponse : 7|64@0+ (1,0) [0|0] "" GTW,GTWU

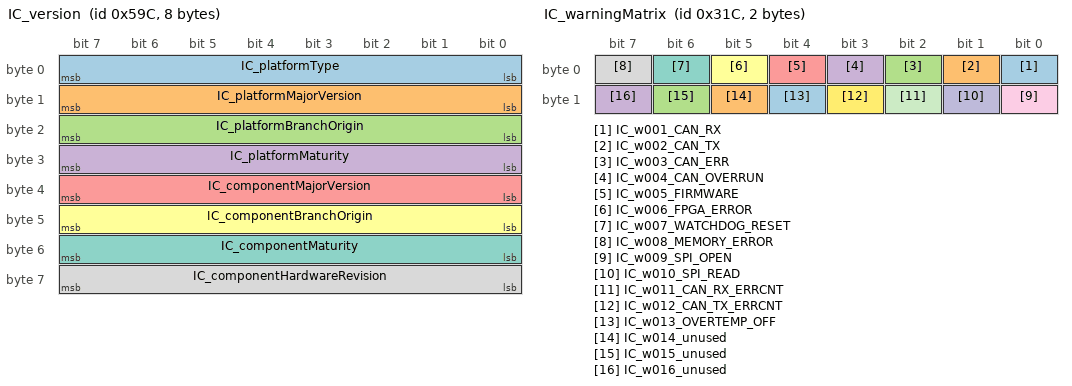
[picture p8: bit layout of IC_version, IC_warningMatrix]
BO_ 1436 IC_version: 8 IC
 SG_ IC_platformType : 0|8@1+ (1,0) [0|0] "" GTW
 SG_ IC_platformMajorVersion : 8|8@1+ (1,0) [0|0] "" GTW
 SG_ IC_platformBranchOrigin : 16|8@1+ (1,0) [0|0] "" GTW
 SG_ IC_platformMaturity : 24|8@1+ (1,0) [0|0] "" GTW
 SG_ IC_componentMajorVersion : 32|8@1+ (1,0) [0|0] "" GTW
 SG_ IC_componentBranchOrigin : 40|8@1+ (1,0) [0|0] "" GTW
 SG_ IC_componentMaturity : 48|8@1+ (1,0) [0|0] "" GTW
 SG_ IC_componentHardwareRevision : 56|8@1+ (1,0) [0|0] "" GTW,GTWU

BO_ 796 IC_warningMatrix: 2 IC
 SG_ IC_w001_CAN_RX : 0|1@1+ (1,0) [0|0] "" GTW
 SG_ IC_w002_CAN_TX : 1|1@1+ (1,0) [0|0] "" GTW
 SG_ IC_w003_CAN_ERR : 2|1@1+ (1,0) [0|0] "" GTW
 SG_ IC_w004_CAN_OVERRUN : 3|1@1+ (1,0) [0|0] "" GTW
 SG_ IC_w005_FIRMWARE : 4|1@1+ (1,0) [0|0] "" GTW
 SG_ IC_w006_FPGA_ERROR : 5|1@1+ (1,0) [0|0] "" GTW
 SG_ IC_w007_WATCHDOG_RESET : 6|1@1+ (1,0) [0|0] "" GTW
 SG_ IC_w008_MEMORY_ERROR : 7|1@1+ (1,0) [0|0] "" GTW
 SG_ IC_w009_SPI_OPEN : 8|1@1+ (1,0) [0|0] "" GTW
 SG_ IC_w010_SPI_READ : 9|1@1+ (1,0) [0|0] "" GTW
 SG_ IC_w011_CAN_RX_ERRCNT : 10|1@1+ (1,0) [0|0] "" GTW
 SG_ IC_w012_CAN_TX_ERRCNT : 11|1@1+ (1,0) [0|0] "" GTW
 SG_ IC_w013_OVERTEMP_OFF : 12|1@1+ (1,0) [0|0] "" GTW
 SG_ IC_w014_unused : 13|1@1+ (1,0) [0|0] "" GTW
 SG_ IC_w015_unused : 14|1@1+ (1,0) [0|0] "" GTW
 SG_ IC_w016_unused : 15|1@1+ (1,0) [0|0] "" GTW

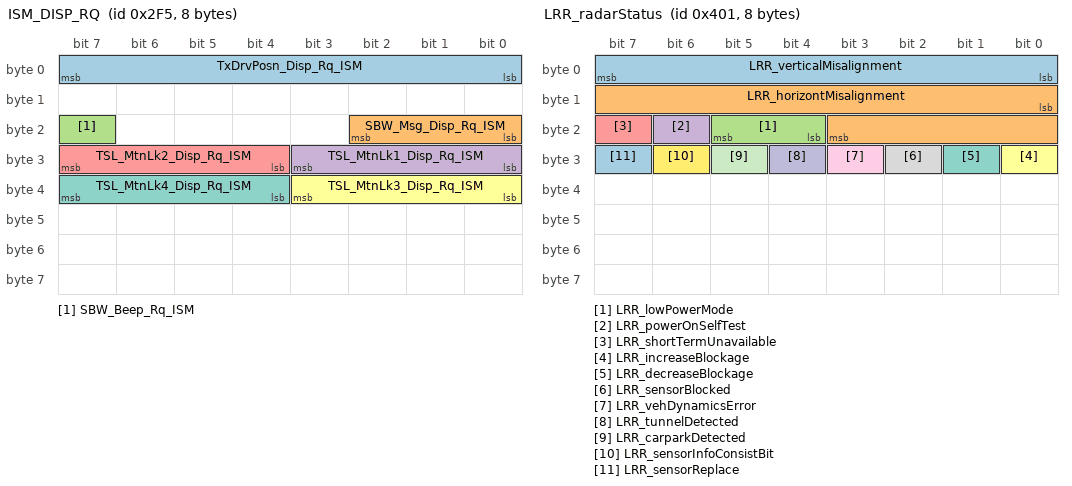
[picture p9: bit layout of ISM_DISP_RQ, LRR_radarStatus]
BO_ 757 ISM_DISP_RQ: 8 GTW
 SG_ TxDrvPosn_Disp_Rq_ISM : 0|8@1+ (1,0) [0|0] "" SCCM
 SG_ SBW_Msg_Disp_Rq_ISM : 16|3@1+ (1,0) [0|0] "" Vector__XXX
 SG_ SBW_Beep_Rq_ISM : 23|1@1+ (1,0) [0|0] "" Vector__XXX
 SG_ TSL_MtnLk1_Disp_Rq_ISM : 24|4@1+ (1,0) [0|0] "" Vector__XXX
 SG_ TSL_MtnLk2_Disp_Rq_ISM : 28|4@1+ (1,0) [0|0] "" Vector__XXX
 SG_ TSL_MtnLk3_Disp_Rq_ISM : 32|4@1+ (1,0) [0|0] "" Vector__XXX
 SG_ TSL_MtnLk4_Disp_Rq_ISM : 36|4@1+ (1,0) [0|0] "" Vector__XXX

BO_ 1025 LRR_radarStatus: 8 APS
 SG_ LRR_verticalMisalignment : 0|8@1+ (0.001953125,-0.25) [-0.25|0.248046875] "rad" GTW
 SG_ LRR_horizontMisalignment : 8|12@1+ (0.0001220703125,-0.25) [-0.25|0.2498779296875] "rad" GTW
 SG_ LRR_lowPowerMode : 20|2@1+ (1,0) [0|3] "" Vector__XXX
 SG_ LRR_powerOnSelfTest : 22|1@1+ (1,0) [0|1] "" Vector__XXX
 SG_ LRR_shortTermUnavailable : 23|1@1+ (1,0) [0|1] "" Vector__XXX
 SG_ LRR_increaseBlockage : 24|1@1+ (1,0) [0|1] "" Vector__XXX
 SG_ LRR_decreaseBlockage : 25|1@1+ (1,0) [0|1] "" Vector__XXX
 SG_ LRR_sensorBlocked : 26|1@1+ (1,0) [0|1] "" Vector__XXX
 SG_ LRR_vehDynamicsError : 27|1@1+ (1,0) [0|1] "" Vector__XXX
 SG_ LRR_tunnelDetected : 28|1@1+ (1,0) [0|1] "" Vector__XXX
 SG_ LRR_carparkDetected : 29|1@1+ (1,0) [0|1] "" Vector__XXX
 SG_ LRR_sensorInfoConsistBit : 30|1@1+ (1,0) [0|1] "" Vector__XXX
 SG_ LRR_sensorReplace : 31|1@1+ (1,0) [0|1] "" Vector__XXX

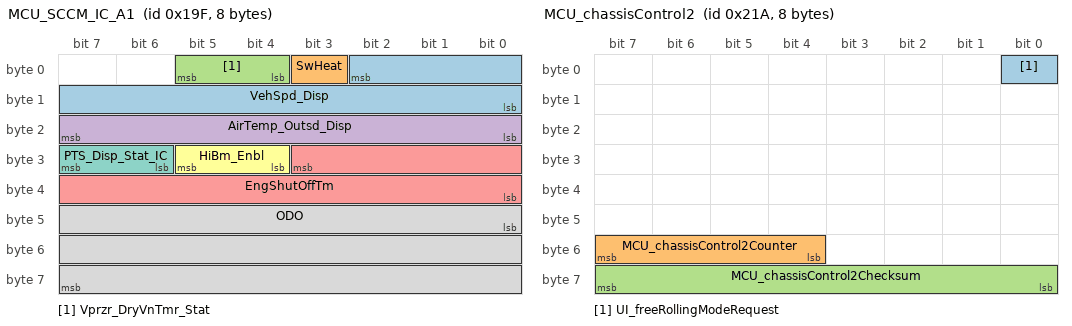
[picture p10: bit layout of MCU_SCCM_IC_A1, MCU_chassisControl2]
BO_ 415 MCU_SCCM_IC_A1: 8 GTW
 SG_ VehSpd_Disp : 2|11@0+ (0.1,0) [0|204.6] "km/h" Vector__XXX
 SG_ SwHeat : 3|1@1+ (1,0) [0|1] "" SCCM
 SG_ Vprzr_DryVnTmr_Stat : 4|2@1+ (1,0) [0|0] "" Vector__XXX
 SG_ AirTemp_Outsd_Disp : 16|8@1+ (0.5,-40) [-40|85] "C" Vector__XXX
 SG_ EngShutOffTm : 27|12@0+ (1,0) [0|4094] "min" Vector__XXX
 SG_ HiBm_Enbl : 28|2@1+ (1,0) [0|0] "" Vector__XXX
 SG_ PTS_Disp_Stat_IC : 30|2@1+ (1,0) [0|0] "" Vector__XXX
 SG_ ODO : 40|24@1+ (0.1,0) [0|167721] "km" SCCM

BO_ 536 MCU_chassisControl: 8 GTW
 SG_ MCU_dasDebugEnable : 0|1@1+ (1,0) [0|0] "" DAS
 SG_ MCU_parkBrakeRequest : 1|1@1+ (1,0) [0|0] "" EPB,EPBM
 SG_ MCU_trailerModeCH : 4|1@1+ (1,0) [0|0] "" ESP,PARK,DAS,TAS
 SG_ MCU_fcwSensitivity : 5|2@1+ (1,0) [0|0] "" DAS
 SG_ MCU_fcwEnable : 7|1@1+ (1,0) [0|0] "" DAS
 SG_ MCU_latControlEnable : 8|2@1+ (1,0) [0|0] "" DAS
 SG_ MCU_accOvertakeEnable : 10|2@1+ (1,0) [0|0] "" DAS
 SG_ MCU_ldwEnable : 12|2@1+ (1,0) [0|0] "" DAS
 SG_ MCU_aebEnable : 14|2@1+ (1,0) [0|0] "" DAS
 SG_ MCU_bsdEnable : 16|2@1+ (1,0) [0|0] "" DAS
 SG_ MCU_ahlbEnable : 18|2@1+ (1,0) [0|0] "" BDY,DAS
 SG_ MCU_parkSetting : 20|2@1+ (1,0) [0|0] "" PARK
 SG_ MCU_pedalSafetyEnable : 22|2@1+ (1,0) [0|0] "" DAS
 SG_ MCU_frontDefrostReq_das : 24|2@1+ (1,0) [0|0] "" DAS
 SG_ MCU_autoParkRequest : 26|4@1+ (1,0) [0|0] "" DAS,PARK
 SG_ MCU_redLightStopSignEnable : 30|2@1+ (1,0) [0|0] "" DAS
 SG_ MCU_enableCreepTorqueCH : 32|1@1+ (1,0) [0|0] "" ESP
 SG_ MCU_narrowGarages : 33|1@1+ (1,0) [0|0] "" DAS
 SG_ MCU_rebootAutopilot : 34|1@1+ (1,0) [0|0] "" APS
 SG_ MCU_enableAutowipers : 35|1@1+ (1,0) [0|0] "" DAS
 SG_ MCU_overPaintedUSS : 38|2@1+ (1,0) [0|0] "" DAS
 SG_ MCU_selfParkTune : 40|4@1+ (1,0) [0|15] "" DAS,PARK
 SG_ MCU_towModeEnable : 44|2@1+ (1,0) [0|0] "" EPB,EPBM
 SG_ MCU_zeroSpeedConfirmed : 46|2@1+ (1,0) [0|0] "" EPB,EPBM
 SG_ MCU_aesEnable : 48|2@1+ (1,0) [0|0] "" DAS
 SG_ MCU_autoLaneChangeEnable : 50|2@1+ (1,0) [0|0] "" DAS
 SG_ MCU_chassisControlCounter : 52|4@1+ (1,0) [0|0] "" PARK,EPB,EPBM
 SG_ MCU_chassisControlChecksum : 56|8@1+ (1,0) [0|0] "" PARK,EPB,EPBM

BO_ 538 MCU_chassisControl2: 8 GTW
 SG_ UI_freeRollingModeRequest : 0|1@1+ (1,0) [0|0] "" EPB,EPBM
 SG_ MCU_chassisControl2Counter : 52|4@1+ (1,0) [0|0] "" EPB,EPBM
 SG_ MCU_chassisControl2Checksum : 56|8@1+ (1,0) [0|0] "" EPB,EPBM

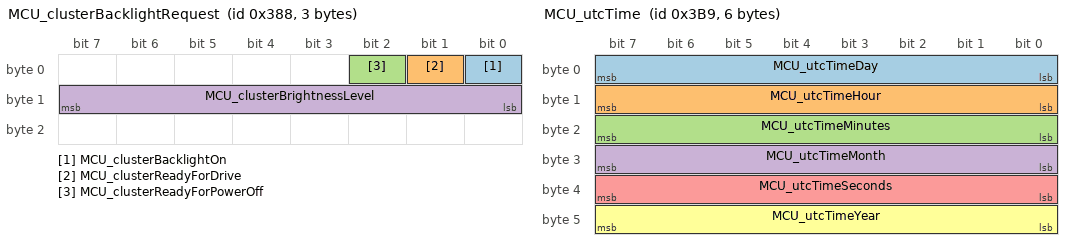
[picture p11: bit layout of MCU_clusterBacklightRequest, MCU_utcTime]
BO_ 904 MCU_clusterBacklightRequest: 3 GTW
 SG_ MCU_clusterBacklightOn : 0|1@1+ (1,0) [0|0] "" IC
 SG_ MCU_clusterReadyForDrive : 1|1@1+ (1,0) [0|0] "" IC
 SG_ MCU_clusterReadyForPowerOff : 2|1@1+ (1,0) [0|0] "" Vector__XXX
 SG_ MCU_clusterBrightnessLevel : 8|8@1+ (0.5,0) [0|127.5] "%" IC

BO_ 2043 MCU_debugTas: 5 GTW
 SG_ MCU_debugTasTarget M : 0|8@1+ (1,0) [0|0] "" TAS2
 SG_ MCU_TAS_damperControlOverride m0 : 8|1@1+ (1,0) [0|0] "" TAS2
 SG_ MCU_TAS_damperModeOverride m0 : 9|1@1+ (1,0) [0|0] "" TAS2
 SG_ MCU_TAS_damperCurrentOverride m0 : 10|1@1+ (1,0) [0|0] "" TAS2
 SG_ MCU_TAS_FLCompCurrentCommand m1 : 8|8@1+ (0.01,0) [0|1.8] "A" TAS2
 SG_ MCU_TAS_FLRebCurrentCommand m1 : 16|8@1+ (0.01,0) [0|1.8] "A" TAS2
 SG_ MCU_TAS_FRCompCurrentCommand m1 : 24|8@1+ (0.01,0) [0|1.8] "A" TAS2
 SG_ MCU_TAS_FRRebCurrentCommand m1 : 32|8@1+ (0.01,0) [0|1.8] "A" TAS2
 SG_ MCU_TAS_RLCompCurrentCommand m2 : 8|8@1+ (0.01,0) [0|1.8] "A" TAS2
 SG_ MCU_TAS_RLRebCurrentCommand m2 : 16|8@1+ (0.01,0) [0|1.8] "A" TAS2
 SG_ MCU_TAS_RRCompCurrentCommand m2 : 24|8@1+ (0.01,0) [0|1.8] "A" TAS2
 SG_ MCU_TAS_RRRebCurrentCommand m2 : 32|8@1+ (0.01,0) [0|1.8] "A" TAS2

BO_ 952 MCU_tpmsC: 8 GTW
 SG_ MCU_setRcpFront : 16|8@1+ (0.025,0) [0|6.375] "bar" TPMS
 SG_ MCU_setRcpRear : 24|8@1+ (0.025,0) [0|6.375] "bar" TPMS

BO_ 953 MCU_utcTime: 6 GTW
 SG_ MCU_utcTimeDay : 0|8@1+ (0.25,0) [0|63.75] "days" TAS,APP
 SG_ MCU_utcTimeHour : 8|8@1+ (1,0) [0|255] "hours" TAS
 SG_ MCU_utcTimeMinutes : 16|8@1+ (1,0) [0|255] "minutes" TAS
 SG_ MCU_utcTimeMonth : 24|8@1+ (1,0) [0|255] "Months" TAS
 SG_ MCU_utcTimeSeconds : 32|8@1+ (0.25,0) [0|63.75] "seconds" TAS
 SG_ MCU_utcTimeYear : 40|8@1+ (1,1985) [1985|2235] "Years" TAS

BO_ 1028 NM_SCCM: 8 SCCM
 SG_ NM_Mode : 0|8@1+ (1,0) [0|0] "" SCCM
 SG_ NM_Successor : 8|8@1+ (1,0) [0|63] "" SCCM
 SG_ NM_Ud_Launch : 16|6@1+ (1,0) [0|0] "" SCCM
 SG_ NM_Sleep_Ack : 22|1@1+ (1,0) [0|0] "" SCCM
 SG_ NM_Sleep_Ind : 23|1@1+ (1,0) [0|0] "" SCCM
 SG_ NM_Ud_Srv M : 24|8@1+ (1,0) [0|0] "" SCCM
 SG_ Nw_Id : 56|8@1+ (1,0) [0|0] "" SCCM
 SG_ WakeupRsn_SCCM m2 : 32|8@1+ (1,0) [0|0] "" SCCM
 SG_ Awake_NwSt m15 : 32|1@1+ (1,0) [0|0] "" SCCM
 SG_ Awake_Diag_Actv m15 : 33|1@1+ (1,0) [0|0] "" SCCM
 SG_ Awake_Ignition_On m15 : 36|1@1+ (1,0) [0|0] "" SCCM
 SG_ Awake_Stw_Lvr_Psd m15 : 37|1@1+ (1,0) [0|0] "" SCCM
 SG_ Awake_TSL_P_Psd m15 : 38|1@1+ (1,0) [0|0] "" SCCM
 SG_ Awake_StwSw_Actv m15 : 39|1@1+ (1,0) [0|0] "" SCCM
 SG_ Awake_EEPROM m15 : 40|1@1+ (1,0) [0|0] "" SCCM

BO_ 1026 NM_SCCM_Predecessor: 8 GTW
 SG_ P_NM_Mode : 0|8@1+ (1,0) [0|0] "" SCCM
 SG_ P_NM_Successor : 8|8@1+ (1,0) [0|63] "" SCCM
 SG_ P_NM_Ud_Launch : 16|6@1+ (1,0) [0|0] "" SCCM
 SG_ P_NM_Sleep_Ack : 22|1@1+ (1,0) [0|0] "" SCCM
 SG_ P_NM_Sleep_Ind : 23|1@1+ (1,0) [0|0] "" SCCM
 SG_ P_NM_Ud_Srv M : 24|8@1+ (1,0) [0|0] "" SCCM
 SG_ P_Nw_Id : 56|8@1+ (1,0) [0|0] "" SCCM
 SG_ P_WakeupRsn_SCCM m2 : 32|8@1+ (1,0) [0|0] "" Vector__XXX
 SG_ P_Awake_NwSt m15 : 32|1@1+ (1,0) [0|0] "" Vector__XXX
 SG_ P_Awake_Diag_Actv m15 : 33|1@1+ (1,0) [0|0] "" Vector__XXX
 SG_ P_Awake_Ignition_On m15 : 36|1@1+ (1,0) [0|0] "" Vector__XXX
 SG_ P_Awake_Stw_Lvr_Psd m15 : 37|1@1+ (1,0) [0|0] "" Vector__XXX
 SG_ P_Awake_TSL_P_Psd m15 : 38|1@1+ (1,0) [0|0] "" Vector__XXX
 SG_ P_Awake_StwSw_Actv m15 : 39|1@1+ (1,0) [0|0] "" Vector__XXX
 SG_ P_Awake_EEPROM m15 : 40|1@1+ (1,0) [0|0] "" Vector__XXX

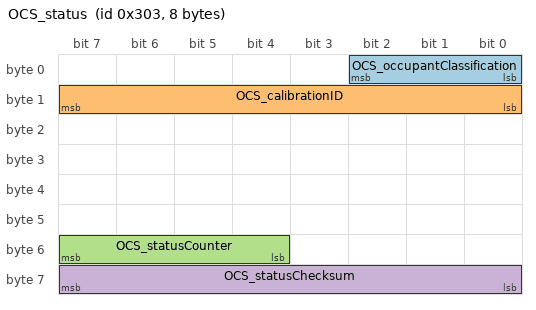
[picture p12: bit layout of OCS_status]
BO_ 771 OCS_status: 8 OCS
 SG_ OCS_occupantClassification : 2|3@0+ (1,0) [0|7] "" GTW,RCM
 SG_ OCS_calibrationID : 15|8@0+ (1,0) [0|255] "" GTW,RCM
 SG_ OCS_statusCounter : 55|4@0+ (1,0) [0|15] "" GTW,RCM
 SG_ OCS_statusChecksum : 63|8@0+ (1,0) [0|255] "" GTW,RCM

BO_ 1619 OCS_udsResponse: 8 OCS
 SG_ OCS_udsResponseData : 7|64@0+ (1,0) [0|0] "" GTW,GTWU

BO_ 1485 PARK3_alertLog: 8 PARK3
 SG_ PARK3_alertID M : 0|15@1+ (1,0) [0|0] "" GTW
 SG_ PARK3_alertType : 15|1@1+ (1,0) [0|0] "" GTW
 SG_ PARK3_sw000_s1Temperature m0 : 16|16@1+ (0.1,-40) [-40|200] "deg" GTW
 SG_ PARK3_sw001_membraneDisconct m1 : 16|1@1+ (1,0) [0|1] "" GTW
 SG_ PARK3_sw001_dampResistorFail m1 : 17|1@1+ (1,0) [0|1] "" GTW
 SG_ PARK3_sw001_resonanceDrift m1 : 18|1@1+ (1,0) [0|1] "" GTW
 SG_ PARK3_sw001_sensorCRC m1 : 19|1@1+ (1,0) [0|1] "" GTW
 SG_ PARK3_sw001_recieveFailure m1 : 20|1@1+ (1,0) [0|1] "" GTW
 SG_ PARK3_sw002_placeHolder m2 : 16|16@1+ (1,0) [0|65535] "" GTW
 SG_ PARK3_sw003_s2Temperature m3 : 16|16@1+ (0.1,-40) [-40|200] "deg" GTW
 SG_ PARK3_sw004_membraneDisconct m4 : 16|1@1+ (1,0) [0|1] "" GTW
 SG_ PARK3_sw004_dampResistorFail m4 : 17|1@1+ (1,0) [0|1] "" GTW
 SG_ PARK3_sw004_resonanceDrift m4 : 18|1@1+ (1,0) [0|1] "" GTW
 SG_ PARK3_sw004_sensorCRC m4 : 19|1@1+ (1,0) [0|1] "" GTW
 SG_ PARK3_sw004_recieveFailure m4 : 20|1@1+ (1,0) [0|1] "" GTW
 SG_ PARK3_sw005_placeHolder m5 : 16|16@1+ (1,0) [0|65535] "" GTW
 SG_ PARK3_sw006_s3Temperature m6 : 16|16@1+ (0.1,-40) [-40|200] "deg" GTW
 SG_ PARK3_sw007_membraneDisconct m7 : 16|1@1+ (1,0) [0|1] "" GTW
 SG_ PARK3_sw007_dampResistorFail m7 : 17|1@1+ (1,0) [0|1] "" GTW
 SG_ PARK3_sw007_resonanceDrift m7 : 18|1@1+ (1,0) [0|1] "" GTW
 SG_ PARK3_sw007_sensorCRC m7 : 19|1@1+ (1,0) [0|1] "" GTW
 SG_ PARK3_sw007_recieveFailure m7 : 20|1@1+ (1,0) [0|1] "" GTW
 SG_ PARK3_sw008_placeHolder m8 : 16|16@1+ (1,0) [0|65535] "" GTW
 SG_ PARK3_sw009_s4Temperature m9 : 16|16@1+ (0.1,-40) [-40|200] "deg" GTW
 SG_ PARK3_sw010_membraneDisconct m10 : 16|1@1+ (1,0) [0|1] "" GTW
 SG_ PARK3_sw010_dampResistorFail m10 : 17|1@1+ (1,0) [0|1] "" GTW
 SG_ PARK3_sw010_resonanceDrift m10 : 18|1@1+ (1,0) [0|1] "" GTW
 SG_ PARK3_sw010_sensorCRC m10 : 19|1@1+ (1,0) [0|1] "" GTW
 SG_ PARK3_sw010_recieveFailure m10 : 20|1@1+ (1,0) [0|1] "" GTW
 SG_ PARK3_sw011_placeHolder m11 : 16|16@1+ (1,0) [0|65535] "" GTW
 SG_ PARK3_sw012_s5Temperature m12 : 16|16@1+ (0.1,-40) [-40|200] "deg" GTW
 SG_ PARK3_sw013_membraneDisconct m13 : 16|1@1+ (1,0) [0|1] "" GTW
 SG_ PARK3_sw013_dampResistorFail m13 : 17|1@1+ (1,0) [0|1] "" GTW
 SG_ PARK3_sw013_resonanceDrift m13 : 18|1@1+ (1,0) [0|1] "" GTW
 SG_ PARK3_sw013_sensorCRC m13 : 19|1@1+ (1,0) [0|1] "" GTW
 SG_ PARK3_sw013_recieveFailure m13 : 20|1@1+ (1,0) [0|1] "" GTW
 SG_ PARK3_sw014_placeHolder m14 : 16|16@1+ (1,0) [0|65535] "" GTW
 SG_ PARK3_sw015_s6Temperature m15 : 16|16@1+ (0.1,-40) [-40|200] "deg" GTW
 SG_ PARK3_sw016_membraneDisconct m16 : 16|1@1+ (1,0) [0|1] "" GTW
 SG_ PARK3_sw016_dampResistorFail m16 : 17|1@1+ (1,0) [0|1] "" GTW
 SG_ PARK3_sw016_resonanceDrift m16 : 18|1@1+ (1,0) [0|1] "" GTW
 SG_ PARK3_sw016_sensorCRC m16 : 19|1@1+ (1,0) [0|1] "" GTW
 SG_ PARK3_sw016_recieveFailure m16 : 20|1@1+ (1,0) [0|1] "" GTW
 SG_ PARK3_sw017_placeHolder m17 : 16|16@1+ (1,0) [0|65535] "" GTW
 SG_ PARK3_sw018_s7Temperature m18 : 16|16@1+ (0.1,-40) [-40|200] "deg" GTW
 SG_ PARK3_sw019_membraneDisconct m19 : 16|1@1+ (1,0) [0|1] "" GTW
 SG_ PARK3_sw019_dampResistorFail m19 : 17|1@1+ (1,0) [0|1] "" GTW
 SG_ PARK3_sw019_resonanceDrift m19 : 18|1@1+ (1,0) [0|1] "" GTW
 SG_ PARK3_sw019_sensorCRC m19 : 19|1@1+ (1,0) [0|1] "" GTW
 SG_ PARK3_sw019_recieveFailure m19 : 20|1@1+ (1,0) [0|1] "" GTW
 SG_ PARK3_sw020_placeHolder m20 : 16|16@1+ (1,0) [0|65535] "" GTW
 SG_ PARK3_sw021_s8Temperature m21 : 16|16@1+ (0.1,-40) [-40|200] "deg" GTW
 SG_ PARK3_sw022_membraneDisconct m22 : 16|1@1+ (1,0) [0|1] "" GTW
 SG_ PARK3_sw022_dampResistorFail m22 : 17|1@1+ (1,0) [0|1] "" GTW
 SG_ PARK3_sw022_resonanceDrift m22 : 18|1@1+ (1,0) [0|1] "" GTW
 SG_ PARK3_sw022_sensorCRC m22 : 19|1@1+ (1,0) [0|1] "" GTW
 SG_ PARK3_sw022_recieveFailure m22 : 20|1@1+ (1,0) [0|1] "" GTW
 SG_ PARK3_sw023_placeHolder m23 : 16|16@1+ (1,0) [0|65535] "" GTW
 SG_ PARK3_sw024_s9Temperature m24 : 16|16@1+ (0.1,-40) [-40|200] "deg" GTW
 SG_ PARK3_sw025_membraneDisconct m25 : 16|1@1+ (1,0) [0|1] "" GTW
 SG_ PARK3_sw025_dampResistorFail m25 : 17|1@1+ (1,0) [0|1] "" GTW
 SG_ PARK3_sw025_resonanceDrift m25 : 18|1@1+ (1,0) [0|1] "" GTW
 SG_ PARK3_sw025_sensorCRC m25 : 19|1@1+ (1,0) [0|1] "" GTW
 SG_ PARK3_sw025_recieveFailure m25 : 20|1@1+ (1,0) [0|1] "" GTW
 SG_ PARK3_sw026_placeHolder m26 : 16|16@1+ (1,0) [0|65535] "" GTW
 SG_ PARK3_sw027_s10Temperature m27 : 16|16@1+ (0.1,-40) [-40|200] "deg" GTW
 SG_ PARK3_sw028_membraneDisconct m28 : 16|1@1+ (1,0) [0|1] "" GTW
 SG_ PARK3_sw028_dampResistorFail m28 : 17|1@1+ (1,0) [0|1] "" GTW
 SG_ PARK3_sw028_resonanceDrift m28 : 18|1@1+ (1,0) [0|1] "" GTW
 SG_ PARK3_sw028_sensorCRC m28 : 19|1@1+ (1,0) [0|1] "" GTW
 SG_ PARK3_sw028_recieveFailure m28 : 20|1@1+ (1,0) [0|1] "" GTW
 SG_ PARK3_sw029_placeHolder m29 : 16|16@1+ (1,0) [0|65535] "" GTW
 SG_ PARK3_sw030_s11Temperature m30 : 16|16@1+ (0.1,-40) [-40|200] "deg" GTW
 SG_ PARK3_sw031_membraneDisconct m31 : 16|1@1+ (1,0) [0|1] "" GTW
 SG_ PARK3_sw031_dampResistorFail m31 : 17|1@1+ (1,0) [0|1] "" GTW
 SG_ PARK3_sw031_resonanceDrift m31 : 18|1@1+ (1,0) [0|1] "" GTW
 SG_ PARK3_sw031_sensorCRC m31 : 19|1@1+ (1,0) [0|1] "" GTW
 SG_ PARK3_sw031_recieveFailure m31 : 20|1@1+ (1,0) [0|1] "" GTW
 SG_ PARK3_sw032_placeHolder m32 : 16|16@1+ (1,0) [0|65535] "" GTW
 SG_ PARK3_sw033_s12Temperature m33 : 16|16@1+ (0.1,-40) [-40|200] "deg" GTW
 SG_ PARK3_sw034_membraneDisconct m34 : 16|1@1+ (1,0) [0|1] "" GTW
 SG_ PARK3_sw034_dampResistorFail m34 : 17|1@1+ (1,0) [0|1] "" GTW
 SG_ PARK3_sw034_resonanceDrift m34 : 18|1@1+ (1,0) [0|1] "" GTW
 SG_ PARK3_sw034_sensorCRC m34 : 19|1@1+ (1,0) [0|1] "" GTW
 SG_ PARK3_sw034_recieveFailure m34 : 20|1@1+ (1,0) [0|1] "" GTW
 SG_ PARK3_sw035_placeHolder m35 : 16|16@1+ (1,0) [0|65535] "" GTW
 SG_ PARK3_sw036_ecuVoltage m36 : 16|8@1+ (0.1,0) [0|25.5] "v" GTW
 SG_ PARK3_sw037_ecuVoltage m37 : 16|8@1+ (0.1,0) [0|25.5] "v" GTW
 SG_ PARK3_sw038_sensorVoltage m38 : 16|8@1+ (0.1,0) [0|25.5] "v" GTW
 SG_ PARK3_sw039_faultCode m39 : 16|8@1+ (1,0) [0|255] "" GTW
 SG_ PARK3_sw040_expectedCRC m40 : 16|16@1+ (1,0) [0|65535] "" GTW
 SG_ PARK3_sw040_calculatedCRC m40 : 32|16@1+ (1,0) [0|65535] "" GTW
 SG_ PARK3_sw041_placeHolder m41 : 33|16@1+ (1,0) [0|65535] "" GTW
 SG_ PARK3_sw042_placeHolder m42 : 33|16@1+ (1,0) [0|65535] "" GTW
 SG_ PARK3_sw043_placeHolder m43 : 33|16@1+ (1,0) [0|65535] "" GTW
 SG_ PARK3_sw044_msgID m44 : 16|12@1+ (1,0) [0|1023] "" GTW
 SG_ PARK3_sw045_msgID m45 : 16|12@1+ (1,0) [0|1023] "" GTW
 SG_ PARK3_sw046_msgID m46 : 16|12@1+ (1,0) [0|1023] "" GTW
 SG_ PARK3_sw047_msgID m47 : 16|12@1+ (1,0) [0|1023] "" GTW
 SG_ PARK3_sw048_msgID m48 : 16|12@1+ (1,0) [0|1023] "" GTW
 SG_ PARK3_sw049_msgID m49 : 16|12@1+ (1,0) [0|1023] "" GTW
 SG_ PARK3_sw050_msgID m50 : 16|12@1+ (1,0) [0|1023] "" GTW
 SG_ PARK3_sw051_msgID m51 : 16|12@1+ (1,0) [0|1023] "" GTW
 SG_ PARK3_sw052_dasErrorExp m52 : 16|16@1+ (1,0) [0|65535] "" GTW
 SG_ PARK3_sw052_dasErrorRx m52 : 32|16@1+ (1,0) [0|65535] "" GTW
 SG_ PARK3_sw052_msgID m52 : 48|12@1+ (1,0) [0|1023] "" GTW
 SG_ PARK3_sw052_dasErrorType m52 : 60|4@1+ (1,0) [0|15] "" GTW
 SG_ PARK3_sw053_diErrorExp m53 : 16|16@1+ (1,0) [0|65535] "" GTW
 SG_ PARK3_sw053_diErrorRx m53 : 32|16@1+ (1,0) [0|65535] "" GTW
 SG_ PARK3_sw053_msgID m53 : 48|12@1+ (1,0) [0|1023] "" GTW
 SG_ PARK3_sw053_diErrorType m53 : 60|4@1+ (1,0) [0|15] "" GTW
 SG_ PARK3_sw054_epasErrorExp m54 : 16|16@1+ (1,0) [0|65535] "" GTW
 SG_ PARK3_sw054_epasErrorRx m54 : 32|16@1+ (1,0) [0|65535] "" GTW
 SG_ PARK3_sw054_msgID m54 : 48|12@1+ (1,0) [0|1023] "" GTW
 SG_ PARK3_sw054_epasErrorType m54 : 60|4@1+ (1,0) [0|15] "" GTW
 SG_ PARK3_sw055_epbErrorExp m55 : 16|16@1+ (1,0) [0|65535] "" GTW
 SG_ PARK3_sw055_epbErrorRx m55 : 32|16@1+ (1,0) [0|65535] "" GTW
 SG_ PARK3_sw055_msgID m55 : 48|12@1+ (1,0) [0|1023] "" GTW
 SG_ PARK3_sw055_epbErrorType m55 : 60|4@1+ (1,0) [0|15] "" GTW
 SG_ PARK3_sw056_espErrorExp m56 : 16|16@1+ (1,0) [0|65535] "" GTW
 SG_ PARK3_sw056_espErrorRx m56 : 32|16@1+ (1,0) [0|65535] "" GTW
 SG_ PARK3_sw056_msgID m56 : 48|12@1+ (1,0) [0|1023] "" GTW
 SG_ PARK3_sw056_espErrorType m56 : 60|4@1+ (1,0) [0|15] "" GTW
 SG_ PARK3_sw057_gtwErrorExp m57 : 16|16@1+ (1,0) [0|65535] "" GTW
 SG_ PARK3_sw057_gtwErrorRx m57 : 32|16@1+ (1,0) [0|65535] "" GTW
 SG_ PARK3_sw057_msgID m57 : 48|12@1+ (1,0) [0|1023] "" GTW
 SG_ PARK3_sw057_gtwErrorType m57 : 60|4@1+ (1,0) [0|15] "" GTW
 SG_ PARK3_sw058_mcuErrorExp m58 : 16|16@1+ (1,0) [0|65535] "" GTW
 SG_ PARK3_sw058_mcuErrorRx m58 : 32|16@1+ (1,0) [0|65535] "" GTW
 SG_ PARK3_sw058_msgID m58 : 48|12@1+ (1,0) [0|1023] "" GTW
 SG_ PARK3_sw058_mcuErrorType m58 : 60|4@1+ (1,0) [0|15] "" GTW
 SG_ PARK3_sw059_sccmErrorExp m59 : 16|16@1+ (1,0) [0|65535] "" GTW
 SG_ PARK3_sw059_sccmErrorRx m59 : 32|16@1+ (1,0) [0|65535] "" GTW
 SG_ PARK3_sw059_msgID m59 : 48|12@1+ (1,0) [0|1023] "" GTW
 SG_ PARK3_sw059_sccmErrorType m59 : 60|4@1+ (1,0) [0|15] "" GTW
 SG_ PARK3_sw060_writeRetryCounter m60 : 16|8@1+ (1,0) [0|255] "" GTW
 SG_ PARK3_sw060_readRetryCounter m60 : 24|8@1+ (1,0) [0|255] "" GTW
 SG_ PARK3_sw060_currentErrorCode m60 : 32|8@1+ (1,0) [0|255] "" GTW
 SG_ PARK3_su000_s1ReverbPeriod m8192 : 16|16@1+ (1,0) [0|0] "" GTW
 SG_ PARK3_su000_s1ReverbTime m8192 : 32|16@1+ (1,0) [0|0] "" GTW
 SG_ PARK3_su000_highAttenTime m8192 : 48|1@1+ (1,0) [0|1] "" GTW
 SG_ PARK3_su000_closeConstEcho m8192 : 49|1@1+ (1,0) [0|1] "" GTW
 SG_ PARK3_su000_lowAttenTime m8192 : 50|1@1+ (1,0) [0|1] "" GTW
 SG_ PARK3_su000_attenTimeJitter m8192 : 51|1@1+ (1,0) [0|1] "" GTW
 SG_ PARK3_su000_reverbFreqJitter m8192 : 52|1@1+ (1,0) [0|1] "" GTW
 SG_ PARK3_su001_s2ReverbPeriod m8193 : 16|16@1+ (1,0) [0|0] "" GTW
 SG_ PARK3_su001_s2ReverbTime m8193 : 32|16@1+ (1,0) [0|0] "" GTW
 SG_ PARK3_su001_highAttenTime m8193 : 48|1@1+ (1,0) [0|1] "" GTW
 SG_ PARK3_su001_closeConstEcho m8193 : 49|1@1+ (1,0) [0|1] "" GTW
 SG_ PARK3_su001_lowAttenTime m8193 : 50|1@1+ (1,0) [0|1] "" GTW
 SG_ PARK3_su001_attenTimeJitter m8193 : 51|1@1+ (1,0) [0|1] "" GTW
 SG_ PARK3_su001_reverbFreqJitter m8193 : 52|1@1+ (1,0) [0|1] "" GTW
 SG_ PARK3_su002_s3ReverbPeriod m8194 : 16|16@1+ (1,0) [0|0] "" GTW
 SG_ PARK3_su002_s3ReverbTime m8194 : 32|16@1+ (1,0) [0|0] "" GTW
 SG_ PARK3_su002_highAttenTime m8194 : 48|1@1+ (1,0) [0|1] "" GTW
 SG_ PARK3_su002_closeConstEcho m8194 : 49|1@1+ (1,0) [0|1] "" GTW
 SG_ PARK3_su002_lowAttenTime m8194 : 50|1@1+ (1,0) [0|1] "" GTW
 SG_ PARK3_su002_attenTimeJitter m8194 : 51|1@1+ (1,0) [0|1] "" GTW
 SG_ PARK3_su002_reverbFreqJitter m8194 : 52|1@1+ (1,0) [0|1] "" GTW
 SG_ PARK3_su003_s4ReverbPeriod m8195 : 16|16@1+ (1,0) [0|0] "" GTW
 SG_ PARK3_su003_s4ReverbTime m8195 : 32|16@1+ (1,0) [0|0] "" GTW
 SG_ PARK3_su003_highAttenTime m8195 : 48|1@1+ (1,0) [0|1] "" GTW
 SG_ PARK3_su003_closeConstEcho m8195 : 49|1@1+ (1,0) [0|1] "" GTW
 SG_ PARK3_su003_lowAttenTime m8195 : 50|1@1+ (1,0) [0|1] "" GTW
 SG_ PARK3_su003_attenTimeJitter m8195 : 51|1@1+ (1,0) [0|1] "" GTW
 SG_ PARK3_su003_reverbFreqJitter m8195 : 52|1@1+ (1,0) [0|1] "" GTW
 SG_ PARK3_su004_s5ReverbPeriod m8196 : 16|16@1+ (1,0) [0|0] "" GTW
 SG_ PARK3_su004_s5ReverbTime m8196 : 32|16@1+ (1,0) [0|0] "" GTW
 SG_ PARK3_su004_highAttenTime m8196 : 48|1@1+ (1,0) [0|1] "" GTW
 SG_ PARK3_su004_closeConstEcho m8196 : 49|1@1+ (1,0) [0|1] "" GTW
 SG_ PARK3_su004_lowAttenTime m8196 : 50|1@1+ (1,0) [0|1] "" GTW
 SG_ PARK3_su004_attenTimeJitter m8196 : 51|1@1+ (1,0) [0|1] "" GTW
 SG_ PARK3_su004_reverbFreqJitter m8196 : 52|1@1+ (1,0) [0|1] "" GTW
 SG_ PARK3_su005_s6ReverbPeriod m8197 : 16|16@1+ (1,0) [0|0] "" GTW
 SG_ PARK3_su005_s6ReverbTime m8197 : 32|16@1+ (1,0) [0|0] "" GTW
 SG_ PARK3_su005_highAttenTime m8197 : 48|1@1+ (1,0) [0|1] "" GTW
 SG_ PARK3_su005_closeConstEcho m8197 : 49|1@1+ (1,0) [0|1] "" GTW
 SG_ PARK3_su005_lowAttenTime m8197 : 50|1@1+ (1,0) [0|1] "" GTW
 SG_ PARK3_su005_attenTimeJitter m8197 : 51|1@1+ (1,0) [0|1] "" GTW
 SG_ PARK3_su005_reverbFreqJitter m8197 : 52|1@1+ (1,0) [0|1] "" GTW
 SG_ PARK3_su006_s7ReverbPeriod m8198 : 16|16@1+ (1,0) [0|0] "" GTW
 SG_ PARK3_su006_s7ReverbTime m8198 : 32|16@1+ (1,0) [0|0] "" GTW
 SG_ PARK3_su006_highAttenTime m8198 : 48|1@1+ (1,0) [0|1] "" GTW
 SG_ PARK3_su006_closeConstEcho m8198 : 49|1@1+ (1,0) [0|1] "" GTW
 SG_ PARK3_su006_lowAttenTime m8198 : 50|1@1+ (1,0) [0|1] "" GTW
 SG_ PARK3_su006_attenTimeJitter m8198 : 51|1@1+ (1,0) [0|1] "" GTW
 SG_ PARK3_su006_reverbFreqJitter m8198 : 52|1@1+ (1,0) [0|1] "" GTW
 SG_ PARK3_su007_s8ReverbPeriod m8199 : 16|16@1+ (1,0) [0|0] "" GTW
 SG_ PARK3_su007_s8ReverbTime m8199 : 32|16@1+ (1,0) [0|0] "" GTW
 SG_ PARK3_su007_highAttenTime m8199 : 48|1@1+ (1,0) [0|1] "" GTW
 SG_ PARK3_su007_closeConstEcho m8199 : 49|1@1+ (1,0) [0|1] "" GTW
 SG_ PARK3_su007_lowAttenTime m8199 : 50|1@1+ (1,0) [0|1] "" GTW
 SG_ PARK3_su007_attenTimeJitter m8199 : 51|1@1+ (1,0) [0|1] "" GTW
 SG_ PARK3_su007_reverbFreqJitter m8199 : 52|1@1+ (1,0) [0|1] "" GTW
 SG_ PARK3_su008_s9ReverbPeriod m8200 : 16|16@1+ (1,0) [0|0] "" GTW
 SG_ PARK3_su008_s9ReverbTime m8200 : 32|16@1+ (1,0) [0|0] "" GTW
 SG_ PARK3_su008_highAttenTime m8200 : 48|1@1+ (1,0) [0|1] "" GTW
 SG_ PARK3_su008_closeConstEcho m8200 : 49|1@1+ (1,0) [0|1] "" GTW
 SG_ PARK3_su008_lowAttenTime m8200 : 50|1@1+ (1,0) [0|1] "" GTW
 SG_ PARK3_su008_attenTimeJitter m8200 : 51|1@1+ (1,0) [0|1] "" GTW
 SG_ PARK3_su008_reverbFreqJitter m8200 : 52|1@1+ (1,0) [0|1] "" GTW
 SG_ PARK3_su009_s10ReverbPeriod m8201 : 16|16@1+ (1,0) [0|0] "" GTW
 SG_ PARK3_su009_s10ReverbTime m8201 : 32|16@1+ (1,0) [0|0] "" GTW
 SG_ PARK3_su009_highAttenTime m8201 : 48|1@1+ (1,0) [0|1] "" GTW
 SG_ PARK3_su009_closeConstEcho m8201 : 49|1@1+ (1,0) [0|1] "" GTW
 SG_ PARK3_su009_lowAttenTime m8201 : 50|1@1+ (1,0) [0|1] "" GTW
 SG_ PARK3_su009_attenTimeJitter m8201 : 51|1@1+ (1,0) [0|1] "" GTW
 SG_ PARK3_su009_reverbFreqJitter m8201 : 52|1@1+ (1,0) [0|1] "" GTW
 SG_ PARK3_su010_s11ReverbPeriod m8202 : 16|16@1+ (1,0) [0|0] "" GTW
 SG_ PARK3_su010_s11ReverbTime m8202 : 32|16@1+ (1,0) [0|0] "" GTW
 SG_ PARK3_su010_highAttenTime m8202 : 48|1@1+ (1,0) [0|1] "" GTW
 SG_ PARK3_su010_closeConstEcho m8202 : 49|1@1+ (1,0) [0|1] "" GTW
 SG_ PARK3_su010_lowAttenTime m8202 : 50|1@1+ (1,0) [0|1] "" GTW
 SG_ PARK3_su010_attenTimeJitter m8202 : 51|1@1+ (1,0) [0|1] "" GTW
 SG_ PARK3_su010_reverbFreqJitter m8202 : 52|1@1+ (1,0) [0|1] "" GTW
 SG_ PARK3_su011_s12ReverbPeriod m8203 : 16|16@1+ (1,0) [0|0] "" GTW
 SG_ PARK3_su011_s12ReverbTime m8203 : 32|16@1+ (1,0) [0|0] "" GTW
 SG_ PARK3_su011_highAttenTime m8203 : 48|1@1+ (1,0) [0|1] "" GTW
 SG_ PARK3_su011_closeConstEcho m8203 : 49|1@1+ (1,0) [0|1] "" GTW
 SG_ PARK3_su011_lowAttenTime m8203 : 50|1@1+ (1,0) [0|1] "" GTW
 SG_ PARK3_su011_attenTimeJitter m8203 : 51|1@1+ (1,0) [0|1] "" GTW
 SG_ PARK3_su011_reverbFreqJitter m8203 : 52|1@1+ (1,0) [0|1] "" GTW
 SG_ PARK3_su012_s1_unused m8204 : 16|8@1+ (1,0) [0|1] "" GTW
 SG_ PARK3_su013_s2_unused m8205 : 16|8@1+ (1,0) [0|1] "" GTW
 SG_ PARK3_su014_s3_unused m8206 : 16|8@1+ (1,0) [0|1] "" GTW
 SG_ PARK3_su015_s4_unused m8207 : 16|8@1+ (1,0) [0|1] "" GTW
 SG_ PARK3_su016_s5_unused m8208 : 16|8@1+ (1,0) [0|1] "" GTW
 SG_ PARK3_su017_s6_unused m8209 : 16|8@1+ (1,0) [0|1] "" GTW
 SG_ PARK3_su018_s7_unused m8210 : 16|8@1+ (1,0) [0|1] "" GTW
 SG_ PARK3_su019_s8_unused m8211 : 16|8@1+ (1,0) [0|1] "" GTW
 SG_ PARK3_su020_s9_unused m8212 : 16|8@1+ (1,0) [0|1] "" GTW
 SG_ PARK3_su021_s10_unused m8213 : 16|8@1+ (1,0) [0|1] "" GTW
 SG_ PARK3_su022_s11_unused m8214 : 16|8@1+ (1,0) [0|1] "" GTW
 SG_ PARK3_su023_s12_unused m8215 : 16|8@1+ (1,0) [0|1] "" GTW

BO_ 910 PARK3_userMatrix: 8 PARK3
 SG_ PARK3_u000_s1_blocked : 0|1@1+ (1,0) [0|1] "" GTW
 SG_ PARK3_u001_s2_blocked : 1|1@1+ (1,0) [0|1] "" GTW
 SG_ PARK3_u002_s3_blocked : 2|1@1+ (1,0) [0|1] "" GTW
 SG_ PARK3_u003_s4_blocked : 3|1@1+ (1,0) [0|1] "" GTW
 SG_ PARK3_u004_s5_blocked : 4|1@1+ (1,0) [0|1] "" GTW
 SG_ PARK3_u005_s6_blocked : 5|1@1+ (1,0) [0|1] "" GTW
 SG_ PARK3_u006_s7_blocked : 6|1@1+ (1,0) [0|1] "" GTW
 SG_ PARK3_u007_s8_blocked : 7|1@1+ (1,0) [0|1] "" GTW
 SG_ PARK3_u008_s9_blocked : 8|1@1+ (1,0) [0|1] "" GTW
 SG_ PARK3_u009_s10_blocked : 9|1@1+ (1,0) [0|1] "" GTW
 SG_ PARK3_u010_s11_blocked : 10|1@1+ (1,0) [0|1] "" GTW
 SG_ PARK3_u011_s12_blocked : 11|1@1+ (1,0) [0|1] "" GTW
 SG_ PARK3_u012_s1_crossTalk : 12|1@1+ (1,0) [0|1] "" GTW
 SG_ PARK3_u013_s2_crossTalk : 13|1@1+ (1,0) [0|1] "" GTW
 SG_ PARK3_u014_s3_crossTalk : 14|1@1+ (1,0) [0|1] "" GTW
 SG_ PARK3_u015_s4_crossTalk : 15|1@1+ (1,0) [0|1] "" GTW
 SG_ PARK3_u016_s5_crossTalk : 16|1@1+ (1,0) [0|1] "" GTW
 SG_ PARK3_u017_s6_crossTalk : 17|1@1+ (1,0) [0|1] "" GTW
 SG_ PARK3_u018_s7_crossTalk : 18|1@1+ (1,0) [0|1] "" GTW
 SG_ PARK3_u019_s8_crossTalk : 19|1@1+ (1,0) [0|1] "" GTW
 SG_ PARK3_u020_s9_crossTalk : 20|1@1+ (1,0) [0|1] "" GTW
 SG_ PARK3_u021_s10_crossTalk : 21|1@1+ (1,0) [0|1] "" GTW
 SG_ PARK3_u022_s11_crossTalk : 22|1@1+ (1,0) [0|1] "" GTW
 SG_ PARK3_u023_s12_crossTalk : 23|1@1+ (1,0) [0|1] "" GTW

BO_ 894 PARK3_warningMatrix: 8 PARK3
 SG_ PARK3_w000_s1_overTemp : 0|1@1+ (1,0) [0|1] "" GTW
 SG_ PARK3_w001_s1_internalFail : 1|1@1+ (1,0) [0|1] "" GTW
 SG_ PARK3_w002_s1_linCommError : 2|1@1+ (1,0) [0|1] "" GTW
 SG_ PARK3_w003_s2_overTemp : 3|1@1+ (1,0) [0|1] "" GTW
 SG_ PARK3_w004_s2_internalFail : 4|1@1+ (1,0) [0|1] "" GTW
 SG_ PARK3_w005_s2_linCommError : 5|1@1+ (1,0) [0|1] "" GTW
 SG_ PARK3_w006_s3_overTemp : 6|1@1+ (1,0) [0|1] "" GTW
 SG_ PARK3_w007_s3_internalFail : 7|1@1+ (1,0) [0|1] "" GTW
 SG_ PARK3_w008_s3_linCommError : 8|1@1+ (1,0) [0|1] "" GTW
 SG_ PARK3_w009_s4_overTemp : 9|1@1+ (1,0) [0|1] "" GTW
 SG_ PARK3_w010_s4_internalFail : 10|1@1+ (1,0) [0|1] "" GTW
 SG_ PARK3_w011_s4_linCommError : 11|1@1+ (1,0) [0|1] "" GTW
 SG_ PARK3_w012_s5_overTemp : 12|1@1+ (1,0) [0|1] "" GTW
 SG_ PARK3_w013_s5_internalFail : 13|1@1+ (1,0) [0|1] "" GTW
 SG_ PARK3_w014_s5_linCommError : 14|1@1+ (1,0) [0|1] "" GTW
 SG_ PARK3_w015_s6_overTemp : 15|1@1+ (1,0) [0|1] "" GTW
 SG_ PARK3_w016_s6_internalFail : 16|1@1+ (1,0) [0|1] "" GTW
 SG_ PARK3_w017_s6_linCommError : 17|1@1+ (1,0) [0|1] "" GTW
 SG_ PARK3_w018_s7_overTemp : 18|1@1+ (1,0) [0|1] "" GTW
 SG_ PARK3_w019_s7_internalFail : 19|1@1+ (1,0) [0|1] "" GTW
 SG_ PARK3_w020_s7_linCommError : 20|1@1+ (1,0) [0|1] "" GTW
 SG_ PARK3_w021_s8_overTemp : 21|1@1+ (1,0) [0|1] "" GTW
 SG_ PARK3_w022_s8_internalFail : 22|1@1+ (1,0) [0|1] "" GTW
 SG_ PARK3_w023_s8_linCommError : 23|1@1+ (1,0) [0|1] "" GTW
 SG_ PARK3_w024_s9_overTemp : 24|1@1+ (1,0) [0|1] "" GTW
 SG_ PARK3_w025_s9_internalFail : 25|1@1+ (1,0) [0|1] "" GTW
 SG_ PARK3_w026_s9_linCommError : 26|1@1+ (1,0) [0|1] "" GTW
 SG_ PARK3_w027_s10_overTemp : 27|1@1+ (1,0) [0|1] "" GTW
 SG_ PARK3_w028_s10_internalFail : 28|1@1+ (1,0) [0|1] "" GTW
 SG_ PARK3_w029_s10_linCommError : 29|1@1+ (1,0) [0|1] "" GTW
 SG_ PARK3_w030_s11_overTemp : 30|1@1+ (1,0) [0|1] "" GTW
 SG_ PARK3_w031_s11_internalFail : 31|1@1+ (1,0) [0|1] "" GTW
 SG_ PARK3_w032_s11_linCommError : 32|1@1+ (1,0) [0|1] "" GTW
 SG_ PARK3_w033_s12_overTemp : 33|1@1+ (1,0) [0|1] "" GTW
 SG_ PARK3_w034_s12_internalFail : 34|1@1+ (1,0) [0|1] "" GTW
 SG_ PARK3_w035_s12_linCommError : 35|1@1+ (1,0) [0|1] "" GTW
 SG_ PARK3_w036_ecuUnderVoltage : 36|1@1+ (1,0) [0|1] "" GTW
 SG_ PARK3_w037_ecuOverVoltage : 37|1@1+ (1,0) [0|1] "" GTW
 SG_ PARK3_w038_sensorVoltage : 38|1@1+ (1,0) [0|1] "" GTW
 SG_ PARK3_w039_ecuFault : 39|1@1+ (1,0) [0|1] "" GTW
 SG_ PARK3_w040_crcFailure : 40|1@1+ (1,0) [0|1] "" GTW
 SG_ PARK3_w041_calibrationMissing : 41|1@1+ (1,0) [0|1] "" GTW
 SG_ PARK3_w042_CAN2busOff : 42|1@1+ (1,0) [0|1] "" GTW
 SG_ PARK3_w043_hwWatchDog : 43|1@1+ (1,0) [0|1] "" GTW
 SG_ PARK3_w044_dasMia : 44|1@1+ (1,0) [0|1] "" GTW
 SG_ PARK3_w045_diMia : 45|1@1+ (1,0) [0|1] "" GTW
 SG_ PARK3_w046_epasMia : 46|1@1+ (1,0) [0|1] "" GTW
 SG_ PARK3_w047_epbMia : 47|1@1+ (1,0) [0|1] "" GTW
 SG_ PARK3_w048_espMia : 48|1@1+ (1,0) [0|1] "" GTW
 SG_ PARK3_w049_gtwMia : 49|1@1+ (1,0) [0|1] "" GTW
 SG_ PARK3_w050_mcuMia : 50|1@1+ (1,0) [0|1] "" GTW
 SG_ PARK3_w051_sccmMia : 51|1@1+ (1,0) [0|1] "" GTW
 SG_ PARK3_w052_dasErr : 52|1@1+ (1,0) [0|1] "" GTW
 SG_ PARK3_w053_diErr : 53|1@1+ (1,0) [0|1] "" GTW
 SG_ PARK3_w054_epasErr : 54|1@1+ (1,0) [0|1] "" GTW
 SG_ PARK3_w055_epbErr : 55|1@1+ (1,0) [0|1] "" GTW
 SG_ PARK3_w056_espErr : 56|1@1+ (1,0) [0|1] "" GTW
 SG_ PARK3_w057_gtwErr : 57|1@1+ (1,0) [0|1] "" GTW
 SG_ PARK3_w058_mcuErr : 58|1@1+ (1,0) [0|1] "" GTW
 SG_ PARK3_w059_sccmErr : 59|1@1+ (1,0) [0|1] "" GTW
 SG_ PARK3_w060_nvmFault : 60|1@1+ (1,0) [0|1] "" GTW

BO_ 1486 PARK_alertLog: 8 PARK
 SG_ PARK_alertID M : 0|15@1+ (1,0) [0|0] "" GTW
 SG_ PARK_alertType : 15|1@1+ (1,0) [0|0] "" GTW
 SG_ PARK_sw000_S1_ussDisturbance m0 : 16|1@1+ (1,0) [0|1] "" GTW
 SG_ PARK_sw000_S2_ussDisturbance m0 : 17|1@1+ (1,0) [0|1] "" GTW
 SG_ PARK_sw000_S3_ussDisturbance m0 : 18|1@1+ (1,0) [0|1] "" GTW
 SG_ PARK_sw000_S4_ussDisturbance m0 : 19|1@1+ (1,0) [0|1] "" GTW
 SG_ PARK_sw000_S5_ussDisturbance m0 : 20|1@1+ (1,0) [0|1] "" GTW
 SG_ PARK_sw000_S6_ussDisturbance m0 : 21|1@1+ (1,0) [0|1] "" GTW
 SG_ PARK_sw000_S7_ussDisturbance m0 : 22|1@1+ (1,0) [0|1] "" GTW
 SG_ PARK_sw000_S8_ussDisturbance m0 : 23|1@1+ (1,0) [0|1] "" GTW
 SG_ PARK_sw000_S9_ussDisturbance m0 : 24|1@1+ (1,0) [0|1] "" GTW
 SG_ PARK_sw000_S10_ussDisturbance m0 : 25|1@1+ (1,0) [0|1] "" GTW
 SG_ PARK_sw000_S11_ussDisturbance m0 : 26|1@1+ (1,0) [0|1] "" GTW
 SG_ PARK_sw000_S12_ussDisturbance m0 : 27|1@1+ (1,0) [0|1] "" GTW
 SG_ PARK_sw000_ussDisturbPasDegMode m0 : 28|3@1+ (1,0) [0|5] "" GTW
 SG_ PARK_sw000_ussDisturbPsxDegMode m0 : 31|3@1+ (1,0) [0|5] "" GTW
 SG_ PARK_sw000_ussDisturbSvaDegMode m0 : 34|2@1+ (1,0) [0|3] "" GTW
 SG_ PARK_sw000_ussDisturbVehSpd m0 : 36|16@1+ (0.1,0) [0|6553.5] "" GTW
 SG_ PARK_sw001_ambTemp m1 : 16|8@1+ (0.5,-40) [-40|87.5] "C" GTW
 SG_ PARK_sw001_voltage m1 : 24|8@1+ (0.1,0) [0|25.4] "V" GTW
 SG_ PARK_sw001_timeHours m1 : 32|5@1+ (1,0) [0|30] "hours" GTW
 SG_ PARK_sw001_timeMinutes m1 : 40|6@1+ (1,0) [0|60] "minutes" GTW
 SG_ PARK_sw001_timeSeconds m1 : 48|7@1+ (0.5,0) [0|60] "seconds" GTW
 SG_ PARK_sw001_subCode m1 : 55|9@1+ (1,0) [0|0] "" GTW
 SG_ PARK_sw002_ambTemp m2 : 16|8@1+ (0.5,-40) [-40|87.5] "C" GTW
 SG_ PARK_sw002_voltage m2 : 24|8@1+ (0.1,0) [0|25.4] "V" GTW
 SG_ PARK_sw002_timeHours m2 : 32|5@1+ (1,0) [0|30] "hours" GTW
 SG_ PARK_sw002_timeMinutes m2 : 40|6@1+ (1,0) [0|60] "minutes" GTW
 SG_ PARK_sw002_timeSeconds m2 : 48|7@1+ (0.5,0) [0|60] "seconds" GTW
 SG_ PARK_sw002_subCode m2 : 55|9@1+ (1,0) [0|0] "" GTW
 SG_ PARK_sw003_ambTemp m3 : 16|8@1+ (0.5,-40) [-40|87.5] "C" GTW
 SG_ PARK_sw003_voltage m3 : 24|8@1+ (0.1,0) [0|25.4] "V" GTW
 SG_ PARK_sw003_timeHours m3 : 32|5@1+ (1,0) [0|30] "hours" GTW
 SG_ PARK_sw003_timeMinutes m3 : 40|6@1+ (1,0) [0|60] "minutes" GTW
 SG_ PARK_sw003_timeSeconds m3 : 48|7@1+ (0.5,0) [0|60] "seconds" GTW

CM_ BO_ 415 "Gateway to SCCM car information message";
CM_ BO_ 536 "traction control signals are not used by ESP, they use GTW_ESP1 message";
CM_ SG_ 861 IBST_d000_bmsInitTestFail "Bosch DTC value: 0x00001C00";
CM_ SG_ 861 IBST_d001_bmcSingleTransTest "Bosch DTC value: 0x00002100";
CM_ SG_ 861 IBST_d002_tle5012SsccrcFail "Bosch DTC value: 0x00002500";
CM_ SG_ 861 IBST_d003_tle5012Config "Bosch DTC value: 0x00003500";
CM_ SG_ 861 IBST_d004_deadlMonTaskx1Ovr "Bosch DTC value: 0x00004F00";
CM_ SG_ 861 IBST_d005_ecuWdFltCntTstFls "Bosch DTC value: 0x00006200";
CM_ SG_ 861 IBST_d006_ecuWdScheduleTout "Bosch DTC value: 0x00006700";
CM_ SG_ 861 IBST_d007_ecuWdStarttestFls "Bosch DTC value: 0x00006800";
CM_ SG_ 861 IBST_d008_ecuWdStatusContErr "Bosch DTC value: 0x00006A00";
CM_ SG_ 861 IBST_d009_netOvrvolt "Bosch DTC value: 0x00006C00";
CM_ SG_ 861 IBST_d010_micSpiTout "Bosch DTC value: 0x00007200";
CM_ SG_ 861 IBST_d011_micSpiTransferErr "Bosch DTC value: 0x00007D00";
CM_ SG_ 861 IBST_d012_netUndvolt "Bosch DTC value: 0x00008500";
CM_ SG_ 861 IBST_d013_xpassToutErr "Bosch DTC value: 0x00009000";
CM_ SG_ 861 IBST_d014_rpsOffsEeReadEmpty "Bosch DTC value: 0x00009400";
CM_ SG_ 861 IBST_d015_rtpEnaHigh "Bosch DTC value: 0x00009500";
CM_ SG_ 861 IBST_d016_xpassEchoCountErr "Bosch DTC value: 0x00009900";
CM_ SG_ 861 IBST_d017_preDriveChckFail "Bosch DTC value: 0x00009E00";
CM_ SG_ 861 IBST_d018_ucSafetyFlt "Bosch DTC value: 0x0000A500";
CM_ SG_ 861 IBST_d019_unsupportedHw "Bosch DTC value: 0x0000A700";
CM_ SG_ 861 IBST_d020_voltPreRegModeFld "Bosch DTC value: 0x0000AA00";
CM_ SG_ 861 IBST_d021_ubbSupplyLine "Bosch DTC value: 0x0000AB00";
CM_ SG_ 861 IBST_d022_stmAswSysTout "Bosch DTC value: 0x0000B900";
CM_ SG_ 861 IBST_d023_stackOvrUndFlow "Bosch DTC value: 0x0000BB00";
CM_ SG_ 861 IBST_d024_smmOneReqsInit "Bosch DTC value: 0x0000C100";
CM_ SG_ 861 IBST_d025_ptsSupply "Bosch DTC value: 0x0000CC00";
CM_ SG_ 861 IBST_d026_ptsSupplyUndvolt "Bosch DTC value: 0x0000CD00";
CM_ SG_ 861 IBST_d027_tempB6Plaus "Bosch DTC value: 0x0000D600";
CM_ SG_ 861 IBST_d028_ecuWdErrCntContErr "Bosch DTC value: 0x0000DD00";
CM_ SG_ 861 IBST_d029_bmcShortedGateTest "Bosch DTC value: 0x0000E100";
CM_ SG_ 861 IBST_d030_controllerDevTooBig "Bosch DTC value: 0x0000E200";
CM_ SG_ 861 IBST_d031_ibDtrFail "Bosch DTC value: 0x0000E300";
CM_ SG_ 861 IBST_d032_oc6InitTestFail "Bosch DTC value: 0x0000E800";
CM_ SG_ 861 IBST_d033_oc6Monitor "Bosch DTC value: 0x0000E900";
CM_ SG_ 861 IBST_d034_motorOscillationDet "Bosch DTC value: 0x0000EA00";
CM_ SG_ 861 IBST_d035_rpsOffsEeReadFail "Bosch DTC value: 0x00010000";
CM_ SG_ 861 IBST_d036_sysErrHook "Bosch DTC value: 0x00025F00";
CM_ SG_ 861 IBST_d037_calIdlePosNotPlaus "Bosch DTC value: 0x00026100";
CM_ SG_ 861 IBST_d038_boostSupUndrvolt "Bosch DTC value: 0x00026300";
CM_ SG_ 861 IBST_d039_calRoutineAbort "Bosch DTC value: 0x00026800";
CM_ SG_ 861 IBST_d040_bmcGateUndervoltPro "Bosch DTC value: 0x00026900";
CM_ SG_ 861 IBST_d041_hswInitPhseUndrvolt "Bosch DTC value: 0x00026C00";
CM_ SG_ 861 IBST_d042_ltmWarnLevelReached "Bosch DTC value: 0x00026D00";
CM_ SG_ 861 IBST_d043_rpsVctrLengthRelErr "Bosch DTC value: 0x00027200";
CM_ SG_ 861 IBST_d044_b6TempDegradeLevel1 "Bosch DTC value: 0x00028100";
CM_ SG_ 861 IBST_d045_B6TempDegradeLevel2 "Bosch DTC value: 0x00028200";
CM_ SG_ 861 IBST_d046_spiAnglOrRawNotUp "Bosch DTC value: 0x00028400";
CM_ SG_ 861 IBST_d047_dcomIboosterNotInit "Bosch DTC value: 0x00029F00";
CM_ SG_ 861 IBST_d048_unintendMotorReturn "Bosch DTC value: 0x0002A000";
CM_ SG_ 861 IBST_d049_cdmOvrvoltLevel1 "Bosch DTC value: 0x0002A400";
CM_ SG_ 861 IBST_d050_cdmUndrvoltLevel2 "Bosch DTC value: 0x0002A500";
CM_ SG_ 861 IBST_d051_cdmUndrvoltLevel1 "Bosch DTC value: 0x0002A600";
CM_ SG_ 861 IBST_d052_motTrvlRelReadFail "Bosch DTC value: 0x0002B200";
CM_ SG_ 861 IBST_d053_tle5012UnexpReset "Bosch DTC value: 0x0002F600";
CM_ SG_ 861 IBST_d054_bmsGateUndrvolt "Bosch DTC value: 0x0002F700";
CM_ SG_ 861 IBST_d055_kl15HwPlausSw "Bosch DTC value: 0x0002FE00";
CM_ SG_ 861 IBST_d056_ibNotShutDownRight "Bosch DTC value: 0x0002FF00";
CM_ SG_ 861 IBST_d057_cdmHardUndrvolt "Bosch DTC value: 0x00030A00";
CM_ SG_ 861 IBST_d058_cdmHardOvrvolt "Bosch DTC value: 0x00030B00";
CM_ SG_ 861 IBST_d059_maxTrvlAdjstUpdFail "Bosch DTC value: 0x00032C00";
CM_ SG_ 861 IBST_d060_ltmLimitReached "Bosch DTC value: 0x00032D00";
CM_ SG_ 861 IBST_d061_dcomEcuDefect "Bosch DTC value: 0x00032F00";
CM_ SG_ 861 IBST_d062_inputStroke1RngHigh "Bosch DTC value: 0x00034800";
CM_ SG_ 861 IBST_d063_inputStroke1RngLow "Bosch DTC value: 0x00034900";
CM_ SG_ 861 IBST_d064_inputStroke2RngHigh "Bosch DTC value: 0x00034A00";
CM_ SG_ 861 IBST_d065_inputStroke2RngLow "Bosch DTC value: 0x00034B00";
CM_ SG_ 861 IBST_d066_ibSupVoltDivDrift "Bosch DTC value: 0x00036600";
CM_ SG_ 861 IBST_d067_sOutRodToPressVal "Bosch DTC value: 0x00036700";
CM_ SG_ 861 IBST_d068_tle5012LifeCnt "Bosch DTC value: 0x00036800";
CM_ SG_ 861 IBST_d069_cdmExtendedUndrvolt "Bosch DTC value: 0x00037200";
CM_ SG_ 861 IBST_d070_cdmExtendedOvrvolt "Bosch DTC value: 0x00037300";
CM_ SG_ 861 IBST_d071_tempB6Ch1LineHigh "Bosch DTC value: 0x00037700";
CM_ SG_ 861 IBST_d072_tempB6Ch1LineLow "Bosch DTC value: 0x00037800";
CM_ SG_ 861 IBST_d073_tempB6Ch2LineHigh "Bosch DTC value: 0x00037900";
CM_ SG_ 861 IBST_d074_tempB6Ch2LineLow "Bosch DTC value: 0x00037A00";
CM_ SG_ 861 IBST_d075_hevSwitchOffDcom "Bosch DTC value: 0x00037B00";
CM_ SG_ 861 IBST_d076_tle5012VoltFail "Bosch DTC value: 0x00039A00";
CM_ SG_ 861 IBST_d077_bcsFltCurrentHigh "Bosch DTC value: 0x00039B00";
CM_ SG_ 861 IBST_d078_bcsFltCurrentLow "Bosch DTC value: 0x00039C00";
CM_ SG_ 861 IBST_d079_ecuSupVoltDivDrift "Bosch DTC value: 0x00056000";
CM_ SG_ 861 IBST_d080_inputstroke1Grad "Bosch DTC value: 0x00057B00";
CM_ SG_ 861 IBST_d081_pts1Err "Bosch DTC value: 0x00057B01";
CM_ SG_ 861 IBST_d082_pts1LineGnd "Bosch DTC value: 0x00057C00";
CM_ SG_ 861 IBST_d083_pts1LineHigh "Bosch DTC value: 0x00057D00";
CM_ SG_ 861 IBST_d084_inputStroke2Grad "Bosch DTC value: 0x0005DC00";
CM_ SG_ 861 IBST_d085_pts2Err "Bosch DTC value: 0x0005DC01";
CM_ SG_ 861 IBST_d086_pts2LineGnd "Bosch DTC value: 0x0005DD00";
CM_ SG_ 861 IBST_d087_pts2LineHigh "Bosch DTC value: 0x0005DE00";
CM_ SG_ 861 IBST_d088_faildevInputStroke "Bosch DTC value: 0x0005E000";
CM_ SG_ 861 IBST_d089_ptsOffsTooHigh "Bosch DTC value: 0x0005E001";
CM_ SG_ 861 IBST_d090_pbistErr "Bosch DTC value: 0x00060400";
CM_ SG_ 861 IBST_d091_ramInitErr "Bosch DTC value: 0x00060401";
CM_ SG_ 861 IBST_d092_ramsinlgeFlt "Bosch DTC value: 0x00060402";
CM_ SG_ 861 IBST_d093_bertFlt "Bosch DTC value: 0x00060700";
CM_ SG_ 861 IBST_d094_CalDataNotPlaus "Bosch DTC value: 0x00060701";
CM_ SG_ 861 IBST_d095_canEHwError "Bosch DTC value: 0x00060702";
CM_ SG_ 861 IBST_d096_canETout "Bosch DTC value: 0x00060703";
CM_ SG_ 861 IBST_d097_cpuException "Bosch DTC value: 0x00060704";
CM_ SG_ 861 IBST_d098_ecuBandGap "Bosch DTC value: 0x00060706";
CM_ SG_ 861 IBST_d099_ecuBmsOnWhileWdTout "Bosch DTC value: 0x00060707";
CM_ SG_ 861 IBST_d100_ecuErrpinCntTstFls "Bosch DTC value: 0x00060708";
CM_ SG_ 861 IBST_d101_ecuHetException "Bosch DTC value: 0x00060709";
CM_ SG_ 861 IBST_d102_ecuHetTuAddErr "Bosch DTC value: 0x0006070A";
CM_ SG_ 861 IBST_d103_ecuHetTuBusErr "Bosch DTC value: 0x0006070B";
CM_ SG_ 861 IBST_d104_ecuHetTuBusyErr "Bosch DTC value: 0x0006070C";
CM_ SG_ 861 IBST_d105_ecuHetTuException "Bosch DTC value: 0x0006070D";
CM_ SG_ 861 IBST_d106_ecuTaskMissing "Bosch DTC value: 0x0006070E";
CM_ SG_ 861 IBST_d107_hetRefError "Bosch DTC value: 0x0006070F";
CM_ SG_ 861 IBST_d108_micInitSpiTstFld "Bosch DTC value: 0x00060710";
CM_ SG_ 861 IBST_d109_micInitSpiTransfErr "Bosch DTC value: 0x00060711";
CM_ SG_ 861 IBST_d110_micIntMonGenBitMon "Bosch DTC value: 0x00060712";
CM_ SG_ 861 IBST_d111_micIntVoltMonFld "Bosch DTC value: 0x00060713";
CM_ SG_ 861 IBST_d112_motPosTrvlReadEmpty "Bosch DTC value: 0x00060714";
CM_ SG_ 861 IBST_d113_motAngBoundReadEmpt "Bosch DTC value: 0x00060715";
CM_ SG_ 861 IBST_d114_motShaftShiftDetect "Bosch DTC value: 0x00060716";
CM_ SG_ 861 IBST_d115_osErrHook "Bosch DTC value: 0x00060717";
CM_ SG_ 861 IBST_d116_pdurEInitFail "Bosch DTC value: 0x00060718";
CM_ SG_ 861 IBST_d117_pdurEPduInstLost "Bosch DTC value: 0x00060719";
CM_ SG_ 861 IBST_d118_pts1OffsEeReadEmpty "Bosch DTC value: 0x0006071A";
CM_ SG_ 861 IBST_d119_pts2OffsEeReadEmpty "Bosch DTC value: 0x0006071B";
CM_ SG_ 861 IBST_d120_rpsOffsXEeReadFail "Bosch DTC value: 0x0006071C";
CM_ SG_ 861 IBST_d121_rpsOffsYEeReadFail "Bosch DTC value: 0x0006071D";
CM_ SG_ 861 IBST_d122_rpsSynchEeReadFail "Bosch DTC value: 0x0006071E";
CM_ SG_ 861 IBST_d123_rpsAnglRecalcErr "Bosch DTC value: 0x0006071F";
CM_ SG_ 861 IBST_d124_motTrvlRelWriteFail "Bosch DTC value: 0x00060720";
CM_ SG_ 861 IBST_d125_motTrvlRelReadEmpty "Bosch DTC value: 0x00060721";
CM_ SG_ 861 IBST_d126_ptsEeReadEmpty "Bosch DTC value: 0x00060723";
CM_ SG_ 861 IBST_d127_ecuAdcConversionErr "Bosch DTC value: 0x00060B00";
CM_ SG_ 861 IBST_d128_ecuAdcSelftestErr "Bosch DTC value: 0x00060B01";
CM_ SG_ 861 IBST_d129_ccmFlt "Bosch DTC value: 0x00060C00";
CM_ SG_ 861 IBST_d130_ecuRomCheck "Bosch DTC value: 0x00060C01";
CM_ SG_ 861 IBST_d131_esmNmiFlt "Bosch DTC value: 0x00060C02";
CM_ SG_ 861 IBST_d132_esmSafetyFlt "Bosch DTC value: 0x00060C03";
CM_ SG_ 861 IBST_d133_motPosTrvlReadFail "Bosch DTC value: 0x00062F00";
CM_ SG_ 861 IBST_d134_motPosTrvlWriteFail "Bosch DTC value: 0x00062F01";
CM_ SG_ 861 IBST_d135_motAnglBndReadErr "Bosch DTC value: 0x00062F02";
CM_ SG_ 861 IBST_d136_motAnglBndWriteErr "Bosch DTC value: 0x00062F03";
CM_ SG_ 861 IBST_d137_motAnglGradTooLarge "Bosch DTC value: 0x00062F04";
CM_ SG_ 861 IBST_d138_pdmCustomerIdMis "Bosch DTC value: 0x00062F05";
CM_ SG_ 861 IBST_d139_pdmDtFormatMis "Bosch DTC value: 0x00062F06";
CM_ SG_ 861 IBST_d140_pdmOutOfMemory "Bosch DTC value: 0x00062F07";
CM_ SG_ 861 IBST_d141_pdmFieldSizeMis "Bosch DTC value: 0x00062F08";
CM_ SG_ 861 IBST_d142_pdmHwAcsErr "Bosch DTC value: 0x00062F09";
CM_ SG_ 861 IBST_d143_pdmInternalHWErr "Bosch DTC value: 0x00062F0A";
CM_ SG_ 861 IBST_d144_ptsCalHysWritFail "Bosch DTC value: 0x00062F0D";
CM_ SG_ 861 IBST_d145_ptsCalValuesChkFail "Bosch DTC value: 0x00062F0E";
CM_ SG_ 861 IBST_d146_pts1CalEeReadFail "Bosch DTC value: 0x00062F0F";
CM_ SG_ 861 IBST_d147_pts1CalEeWriteFail "Bosch DTC value: 0x00062F10";
CM_ SG_ 861 IBST_d148_rpsFailCompErr "Bosch DTC value: 0x00062F11";
CM_ SG_ 861 IBST_d149_pts1OffsEeWriteFail "Bosch DTC value: 0x00062F12";
CM_ SG_ 861 IBST_d150_pts2CalEeReadFail "Bosch DTC value: 0x00062F13";
CM_ SG_ 861 IBST_d151_pts2CalEeWriteFail "Bosch DTC value: 0x00062F14";
CM_ SG_ 861 IBST_d152_pts2OffsEeReadFail "Bosch DTC value: 0x00062F15";
CM_ SG_ 861 IBST_d153_pts2OffsEeWriteFail "Bosch DTC value: 0x00062F16";
CM_ SG_ 861 IBST_d154_rpsOffsXEeReadEmpty "Bosch DTC value: 0x00062F1D";
CM_ SG_ 861 IBST_d155_rpsOffsXEeWriteFail "Bosch DTC value: 0x00062F1E";
CM_ SG_ 861 IBST_d156_rpsOffsYEeReadEmpty "Bosch DTC value: 0x00062F1F";
CM_ SG_ 861 IBST_d157_rpsOffsYEeWriteFail "Bosch DTC value: 0x00062F20";
CM_ SG_ 861 IBST_d158_rpsSynchEeReadEmpty "Bosch DTC value: 0x00062F21";
CM_ SG_ 861 IBST_d159_rpsSynchEeWriteFail "Bosch DTC value: 0x00062F22";
CM_ SG_ 861 IBST_d160_assertionFail "Bosch DTC value: 0x00390000";
CM_ SG_ 861 IBST_d161_comsclBrkPrsPduLen "Bosch DTC value: 0x00390200";
CM_ SG_ 861 IBST_d162_comsclBrkPrsPduTout "Bosch DTC value: 0x00390300";
CM_ SG_ 861 IBST_d163_comsclEspIb1CntErr "Bosch DTC value: 0x00390400";
CM_ SG_ 861 IBST_d164_comsclEspIb1CsErr "Bosch DTC value: 0x00390500";
CM_ SG_ 861 IBST_d165_comsclEspIb1DlcErr "Bosch DTC value: 0x00390600";
CM_ SG_ 861 IBST_d166_comsclEspIb1Tout "Bosch DTC value: 0x00390700";
CM_ SG_ 861 IBST_d167_comsclEspIb2CntErr "Bosch DTC value: 0x00390800";
CM_ SG_ 861 IBST_d168_comsclEspIb2CsErr "Bosch DTC value: 0x00390900";
CM_ SG_ 861 IBST_d169_comsclEspIb2DlcErr "Bosch DTC value: 0x00390A00";
CM_ SG_ 861 IBST_d170_comsclEspIb2Tout "Bosch DTC value: 0x00390B00";
CM_ SG_ 861 IBST_d171_comsclEspIb3CntErr "Bosch DTC value: 0x00390C00";
CM_ SG_ 861 IBST_d172_comsclEspIb3CsErr "Bosch DTC value: 0x00390D00";
CM_ SG_ 861 IBST_d173_comsclEspIb3DlcErr "Bosch DTC value: 0x00390E00";
CM_ SG_ 861 IBST_d174_comsclEspIb3Tout "Bosch DTC value: 0x00390F00";
CM_ SG_ 861 IBST_d175_comsclGtwEsp1CntErr "Bosch DTC value: 0x00391000";
CM_ SG_ 861 IBST_d176_comsclGtwEsp1CsErr "Bosch DTC value: 0x00391100";
CM_ SG_ 861 IBST_d177_comsclGtwEsp1Corrpt "Bosch DTC value: 0x00391200";
CM_ SG_ 861 IBST_d178_comsclGtwEsp1Tout "Bosch DTC value: 0x00391300";
CM_ SG_ 861 IBST_d179_dcomSmrtActuNotInit "Bosch DTC value: 0x00391400";
CM_ SG_ 861 IBST_d180_rpsLengthAbsolHigh "Bosch DTC value: 0x00391500";
CM_ SG_ 861 IBST_d181_rpsLengthAbsolLow "Bosch DTC value: 0x00391600";
CM_ SG_ 861 IBST_d182_shutDownEeReadFail "Bosch DTC value: 0x00392600";
CM_ SG_ 861 IBST_d183_shutDownEeWriteFail "Bosch DTC value: 0x00392700";
CM_ SG_ 861 IBST_d184_maxTrvlAdjstReadErr "Bosch DTC value: 0x00392C00";
CM_ SG_ 861 IBST_d185_psOffsMcEeReadFail "Bosch DTC value: 0x00392F00";
CM_ SG_ 861 IBST_d186_psOffsMcEeWriteFail "Bosch DTC value: 0x00393000";
CM_ SG_ 861 IBST_d187_ltmSelfProtDeact "Bosch DTC value: 0x00399400";
CM_ SG_ 861 IBST_d188_pts1OffsEeReadFail "Bosch DTC value: 0x00399500";
CM_ SG_ 861 IBST_d189_diffStrokeRange "Bosch DTC value: 0x00520000";
CM_ SG_ 861 IBST_d190_notProgVin "Bosch DTC value: 0x00522051";
CM_ SG_ 861 IBST_d191_plausVin "Bosch DTC value: 0x00522062";
CM_ SG_ 861 IBST_d192_dlCorCSumVin "Bosch DTC value: 0x00522081";
CM_ SG_ 861 IBST_d193_ToutVin "Bosch DTC value: 0x00522087";
CM_ SG_ 861 IBST_d194_ecuEnableB6Fail "Bosch DTC value: 0x00A02D00";
CM_ SG_ 861 IBST_d195_ecuIbEnContErr "Bosch DTC value: 0x00A02D01";
CM_ SG_ 861 IBST_d196_sclEspIb1pEstMax "Bosch DTC value: 0x00C41600";
CM_ SG_ 861 IBST_d197_sclEspIb1VehSpd "Bosch DTC value: 0x00C41601";
CM_ SG_ 861 IBST_d198_sclEspIb2pLimExt "Bosch DTC value: 0x00C41602";
CM_ SG_ 861 IBST_d199_sclEspIb2qTarExt "Bosch DTC value: 0x00C41603";
CM_ SG_ 861 IBST_d200_sclEspIb3pFBlend "Bosch DTC value: 0x00C41604";
CM_ SG_ 861 IBST_d201_sclEspIb3pMc1 "Bosch DTC value: 0x00C41605";
CM_ SG_ 861 IBST_d202_sclEspIb3pTarDriver "Bosch DTC value: 0x00C41606";
CM_ SG_ 861 IBST_d203_netBusOffNet0 "Bosch DTC value: 0x00D0B800";
CM_ SG_ 861 IBST_d204_netErrPassivNet0 "Bosch DTC value: 0x00D0B801";
CM_ SG_ 861 IBST_d205_netBusOffNet1 "Bosch DTC value: 0x00D0B802";
CM_ SG_ 861 IBST_d206_netErrPassivNet1 "Bosch DTC value: 0x00D0B803";
CM_ SG_ 861 IBST_d207_maxStrokeReached "Bosch DTC value: 0x00522069";
CM_ SG_ 861 IBST_d208_sysSwClockMismatch "Bosch DTC value: 0x00060C04";
CM_ SG_ 861 IBST_d209_comsclGtwOdoCorrpt "Bosch DTC value: 0x00391201";
CM_ SG_ 861 IBST_d210_comsclGtwStatCorrpt "Bosch DTC value: 0x00391202";
CM_ SG_ 861 IBST_d211_comsclEpbStatCorrpt "Bosch DTC value: 0x00391203";
CM_ SG_ 861 IBST_d212_comsclGtwOdoTout "Bosch DTC value: 0x00391301";
CM_ SG_ 861 IBST_d213_comsclGtwStatTout "Bosch DTC value: 0x00391302";
CM_ SG_ 861 IBST_d214_comsclEpbStatTout "Bosch DTC value: 0x00391303";
CM_ SG_ 861 IBST_d215_comSclEpbStatCsErr "Bosch DTC value: 0x00391103";
CM_ SG_ 861 IBST_d216_comSclEpbStatCntFlt "Bosch DTC value: 0x00391003";
CM_ SG_ 861 IBST_d217_comSclDiTrq1Tout "Bosch DTC value: 0x00391304";
CM_ SG_ 861 IBST_d218_comSclDiTrq1Corrpt "Bosch DTC value: 0x00391204";
CM_ SG_ 861 IBST_d219_comSclDiTrq1CsErr "Bosch DTC value: 0x00391104";
CM_ SG_ 861 IBST_d220_comSclDiTrq1CntFlt "Bosch DTC value: 0x00391004";
CM_ SG_ 541 IBST_ebrStatusChecksum "Message checksum for IBST_extBrkReq message: sum of all bytes in message (Unused fields are set to 0) + originating CAN ID (0x2 + 0x1D = 0x1F).";
CM_ SG_ 541 IBST_ebrStatusCounter "Message counter: increments in each message.";
CM_ SG_ 541 IBST_ebrMode "State of IBST only to perform autonomous braking.";
CM_ SG_ 541 IBST_ebrSystemMode "State of system (ESP and IBST) to perform autonomous braking.";
CM_ SG_ 541 IBST_brakeTorqueTarget "Brake torque that the ESP targets in response to an external request.";
CM_ SG_ 541 IBST_ebrSource "Current source of external brake torque";
CM_ SG_ 541 IBST_ebrState "Current EBR activity";
CM_ SG_ 925 IBST_pedalCalCurrentCurve "Current Curve Number of Pedal Force Adjust (Curve 0 - 5)";
CM_ SG_ 925 IBST_iBoosterStatus "Indication of the iBooster functional status.";
CM_ SG_ 925 IBST_brakeInputStroke "iBooster brake input rod travel.";
CM_ SG_ 1436 IC_platformType "IC platform type";
CM_ SG_ 1436 IC_platformMajorVersion "IC platform major version";
CM_ SG_ 1436 IC_platformBranchOrigin "IC platform branch origin";
CM_ SG_ 1436 IC_platformMaturity "IC platform maturity";
CM_ SG_ 1436 IC_componentMajorVersion "IC component major version";
CM_ SG_ 1436 IC_componentBranchOrigin "IC component branch origin";
CM_ SG_ 1436 IC_componentMaturity "IC component maturity";
CM_ SG_ 1436 IC_componentHardwareRevision "IC component hardware version";
CM_ SG_ 757 TxDrvPosn_Disp_Rq_ISM "Transmission driving position display request";
CM_ SG_ 757 SBW_Msg_Disp_Rq_ISM "Shift by wire message display request";
CM_ SG_ 757 SBW_Beep_Rq_ISM "Shift by wire beep request";
CM_ SG_ 757 TSL_MtnLk1_Disp_Rq_ISM "Transmission selector lever motion lock 1 display request";
CM_ SG_ 757 TSL_MtnLk2_Disp_Rq_ISM "Transmission selector lever motion lock 2 display request";
CM_ SG_ 757 TSL_MtnLk3_Disp_Rq_ISM "Transmission selector lever motion lock 3 display request";
CM_ SG_ 757 TSL_MtnLk4_Disp_Rq_ISM "Transmission selector lever motion lock 4 display request";
CM_ SG_ 415 VehSpd_Disp "Displayed vehicle speed (without attenuation)";
CM_ SG_ 415 Vprzr_DryVnTmr_Stat "Vaporizer dry ventilation timer state";
CM_ SG_ 415 AirTemp_Outsd_Disp "Displayed outside air temperature";
CM_ SG_ 415 EngShutOffTm "Engine shut-off time";
CM_ SG_ 415 HiBm_Enbl "High beam enable";
CM_ SG_ 415 PTS_Disp_Stat_IC "PTS display state from IC";
CM_ SG_ 415 ODO "Odometer";
CM_ SG_ 536 MCU_trailerModeCH "Indicates whether trailer mode is selected. To be used when towing a trailer. Signal on CH bus.";
CM_ SG_ 536 MCU_fcwEnable "Enable Forward Collision Warning";
CM_ SG_ 536 MCU_latControlEnable "Enable Lateral Control (lane centering, lane keeping, lane changing)";
CM_ SG_ 536 MCU_accOvertakeEnable "Enable ACC Overtake assistance (reduce follow distance when the turn signal is on)";
CM_ SG_ 536 MCU_ldwEnable "Enable Lane Departure Warning";
CM_ SG_ 536 MCU_aebEnable "Enable Autonomous Emergency Brakes";
CM_ SG_ 536 MCU_bsdEnable "Enable Blind Spot Detection";
CM_ SG_ 536 MCU_ahlbEnable "Enable Automatic High/Low Beams";
CM_ SG_ 536 MCU_pedalSafetyEnable "Enable Pedal Safety (accel limitation when obstacle in the way)";
CM_ SG_ 536 MCU_redLightStopSignEnable "Enable Red Light and Stop Sign Warnings";
CM_ SG_ 536 MCU_enableCreepTorqueCH "Indicates whether creep mode is enabled.";
CM_ SG_ 536 MCU_aesEnable "Enable Automatic Emergency Steering";
CM_ SG_ 536 MCU_chassisControlChecksum "Checksum method for MCU_chassisControl: sum of all bytes in message + originating CAN ID (0x0 + 0x50 = 0x50).";
CM_ SG_ 538 UI_freeRollingModeRequest "Indicates whether free rolling mode is requested.";
CM_ SG_ 538 MCU_chassisControl2Checksum "Checksum method for MCU_chassisControl2: sum of all bytes in message + originating CAN ID (0x0 + 0x51 = 0x51).";
CM_ SG_ 1028 NM_Mode "Network management mode";
CM_ SG_ 1028 NM_Successor "Network management logical successor";
CM_ SG_ 1028 NM_Ud_Launch "Network management userdata launch type";
CM_ SG_ 1028 NM_Sleep_Ack "Network management sleep acknowledge";
CM_ SG_ 1028 NM_Sleep_Ind "Network management sleep indication";
CM_ SG_ 1028 NM_Ud_Srv "Network management userdata service no.";
CM_ SG_ 1028 Nw_Id "Network identification no.";
CM_ SG_ 1028 WakeupRsn_SCCM "Wakeup reason";
CM_ SG_ 1028 Awake_NwSt "Stay awake for network startup";
CM_ SG_ 1028 Awake_Diag_Actv "Stay awake for diagnostics active";
CM_ SG_ 1028 Awake_Ignition_On "Stay awake for ignition on";
CM_ SG_ 1028 Awake_Stw_Lvr_Psd "Stay awake for steering wheel lever actuated";
CM_ SG_ 1028 Awake_TSL_P_Psd "Stay awake for transmission selector lever 'P' actuated";
CM_ SG_ 1028 Awake_StwSw_Actv "Stay awake for steering wheel switches active";
CM_ SG_ 1028 Awake_EEPROM "Stay awake for EEPROM write access";
CM_ SG_ 1026 P_NM_Mode "Network management mode";
CM_ SG_ 1026 P_NM_Successor "Network management logical successor";
CM_ SG_ 1026 P_NM_Ud_Launch "Network management userdata launch type";
CM_ SG_ 1026 P_NM_Sleep_Ack "Network management sleep acknowledge";
CM_ SG_ 1026 P_NM_Sleep_Ind "Network management sleep indication";
CM_ SG_ 1026 P_NM_Ud_Srv "Network management userdata service no.";
CM_ SG_ 1026 P_Nw_Id "Network identification no.";
CM_ SG_ 1026 P_WakeupRsn_SCCM "Wakeup reason";
CM_ SG_ 1026 P_Awake_NwSt "Stay awake for network startup";
CM_ SG_ 1026 P_Awake_Diag_Actv "Stay awake for diagnostics active";
CM_ SG_ 1026 P_Awake_Ignition_On "Stay awake for ignition on";
CM_ SG_ 1026 P_Awake_Stw_Lvr_Psd "Stay awake for steering wheel lever actuated";
CM_ SG_ 1026 P_Awake_TSL_P_Psd "Stay awake for transmission selector lever 'P' actuated";
CM_ SG_ 1026 P_Awake_StwSw_Actv "Stay awake for steering wheel switches active";
CM_ SG_ 1026 P_Awake_EEPROM "Stay awake for EEPROM write access";
BA_DEF_ BO_ "AlertLogSubSystemId" INT 0 0;
BA_DEF_ BO_ "AlertType" INT 0 4;
BA_DEF_ BO_ "AppBotschaft" ENUM "nein","ja";
BA_DEF_ BO_ "DiagRequest" ENUM "No","Yes";
BA_DEF_ BO_ "DiagResponse" ENUM "No","Yes";
BA_DEF_ BO_ "ETHGatewayMessageSendType" ENUM "UseGenMsgSendType","onWrite","noAutoCode";
BA_DEF_ BO_ "ETHId" STRING ;
BA_DEF_ BO_ "GatewayHandlerEnum" ENUM "noHandler","uds","alertLog","messageLogOnReception","udsClient";
BA_DEF_ BO_ "GatewayMessageAtomic" ENUM "No","Yes";
BA_DEF_ BO_ "GatewayMessageSendType" ENUM "UseGenMsgSendType","onWrite","noAutoCode";
BA_DEF_ BO_ "GenMsgCycleTime" INT 0 0;
BA_DEF_ BO_ "GenMsgCycleTimeFast" INT 0 0;
BA_DEF_ BO_ "GenMsgDelayTime" INT 0 0;
BA_DEF_ BO_ "GenMsgForceMiaCheck" ENUM "No","Yes";
BA_DEF_ BO_ "GenMsgGatewayNotification" STRING ;
BA_DEF_ BO_ "GenMsgILSupport" ENUM "No","Yes";
BA_DEF_ BO_ "GenMsgSaltingFunction" ENUM "No","Yes";
BA_DEF_ BO_ "GenMsgSendType" ENUM "Cyclic","NotUsed","NotUsed","NotUsed","NotUsed","NotUsed","NotUsed","IfActive","NoMsgSendType","Sporadic";
BA_DEF_ BO_ "GenMsgStartValue" STRING ;
BA_DEF_ BO_ "GenMsgTimeOut" INT 0 0;
BA_DEF_ BO_ "MessageIdType" ENUM "normal","udsRequest","udsResponse","udsReserved","udsFunctionalRequest","networkManagement","bootloader","xcp","dtc","diagnostic","vendorExempt";
BA_DEF_ BO_ "NWMBotschaft" ENUM "nein","ja";
BA_DEF_ BO_ "NmMessage" ENUM "No","Yes";
BA_DEF_ BO_ "SubSystemId" INT 0 256;
BA_DEF_ BO_ "UsesChecksum" ENUM "No","Yes";
BA_DEF_ SG_ "FieldType" STRING ;
BA_DEF_ SG_ "FlexKomComment" STRING ;
BA_DEF_ SG_ "FlexKomIsMotorola" ENUM "nein","ja";
BA_DEF_ SG_ "FlexKomSID" INT 0 2147483647;
BA_DEF_ SG_ "FlexKomSigLaenge" INT 0 64;
BA_DEF_ SG_ "FlexKomSigName" STRING ;
BA_DEF_ SG_ "FlexKomSigStartPos" INT 0 63;
BA_DEF_ SG_ "FlexKomSigStartValue" STRING ;
BA_DEF_ SG_ "Gatewaysignal" INT 0 1;
BA_DEF_ SG_ "GenSigCycleTime" INT 0 0;
BA_DEF_ SG_ "GenSigCycleTimeActive" INT 0 0;
BA_DEF_ SG_ "GenSigPersistent" ENUM "No","Yes";
BA_DEF_ SG_ "GenSigSNA" STRING ;
BA_DEF_ SG_ "GenSigSendType" ENUM "Cyclic","OnWrite","OnWriteWithRepetition","OnChange","OnChangeWithRepetition","IfActive","IfActiveWithRepetition","NoSigSendType","NotUsed","NotUsed","NotUsed","NotUsed","NotUsed";
BA_DEF_ SG_ "GenSigStartValue" INT 0 0;
BA_DEF_ SG_ "GenSigTimeout_CGW" INT 0 65535;
BA_DEF_ SG_ "GenSigTimeout_DRVU" INT 0 65535;
BA_DEF_ SG_ "GenSigTimeout_ECM" INT 0 65535;
BA_DEF_ SG_ "GenSigTimeout_EIS" INT 0 65535;
BA_DEF_ SG_ "GenSigTimeout_EPS" INT 0 65535;
BA_DEF_ SG_ "GenSigTimeout_ESP_ABR" INT 0 65535;
BA_DEF_ SG_ "GenSigTimeout_IC" INT 0 65535;
BA_DEF_ SG_ "GenSigTimeout_MPC" INT 0 65535;
BA_DEF_ SG_ "GenSigTimeout_NV" INT 0 65535;
BA_DEF_ SG_ "GenSigTimeout_ORC" INT 0 65535;
BA_DEF_ SG_ "GenSigTimeout_PTS" INT 0 65535;
BA_DEF_ SG_ "GenSigTimeout_RBTM_FL" INT 0 65535;
BA_DEF_ SG_ "GenSigTimeout_RBTM_FR" INT 0 65535;
BA_DEF_ SG_ "GenSigTimeout_RDU" INT 0 65535;
BA_DEF_ SG_ "GenSigTimeout_SCCM" INT 0 65535;
BA_DEF_ SG_ "GenSigTimeout_SPC" INT 0 65535;
BA_DEF_ SG_ "GenSigTimeout_TPM" INT 0 65535;
BA_DEF_ SG_ "LogSignal" STRING ;
BA_DEF_ SG_ "PektronUpdateBitType" ENUM "Not used","Has update bit","Is update bit";
BA_DEF_REL_ BU_SG_REL_ "GenSigTimeoutTime" INT 0 0;

BA_DEF_DEF_ "AlertLogSubSystemId" 0;
BA_DEF_DEF_ "AlertType" 4;
BA_DEF_DEF_ "AppBotschaft" "nein";
BA_DEF_DEF_ "DiagRequest" "No";
BA_DEF_DEF_ "DiagResponse" "No";
BA_DEF_DEF_ "ETHGatewayMessageSendType" "UseGenMsgSendType";
BA_DEF_DEF_ "ETHId" "";
BA_DEF_DEF_ "FieldType" "";
BA_DEF_DEF_ "FlexKomComment" "";
BA_DEF_DEF_ "FlexKomIsMotorola" "";
BA_DEF_DEF_ "FlexKomSID" 0;
BA_DEF_DEF_ "FlexKomSigLaenge" 0;
BA_DEF_DEF_ "FlexKomSigName" "";
BA_DEF_DEF_ "FlexKomSigStartPos" 0;
BA_DEF_DEF_ "FlexKomSigStartValue" "";
BA_DEF_DEF_ "GatewayHandlerEnum" "noHandler";
BA_DEF_DEF_ "GatewayMessageAtomic" "No";
BA_DEF_DEF_ "GatewayMessageSendType" "UseGenMsgSendType";
BA_DEF_DEF_ "Gatewaysignal" 0;
BA_DEF_DEF_ "GenMsgCycleTime" 0;
BA_DEF_DEF_ "GenMsgCycleTimeFast" 0;
BA_DEF_DEF_ "GenMsgDelayTime" 0;
BA_DEF_DEF_ "GenMsgForceMiaCheck" "No";
BA_DEF_DEF_ "GenMsgGatewayNotification" "";
BA_DEF_DEF_ "GenMsgILSupport" "Yes";
BA_DEF_DEF_ "GenMsgSaltingFunction" "No";
BA_DEF_DEF_ "GenMsgSendType" "Cyclic";
BA_DEF_DEF_ "GenMsgStartValue" "";
BA_DEF_DEF_ "GenMsgTimeOut" 0;
BA_DEF_DEF_ "GenSigCycleTime" 0;
BA_DEF_DEF_ "GenSigCycleTimeActive" 0;
BA_DEF_DEF_ "GenSigPersistent" "No";
BA_DEF_DEF_ "GenSigSNA" "";
BA_DEF_DEF_ "GenSigSendType" "Cyclic";
BA_DEF_DEF_ "GenSigStartValue" 0;
BA_DEF_DEF_ "GenSigTimeout_CGW" 0;
BA_DEF_DEF_ "GenSigTimeout_DRVU" 0;
BA_DEF_DEF_ "GenSigTimeout_ECM" 0;
BA_DEF_DEF_ "GenSigTimeout_EIS" 0;
BA_DEF_DEF_ "GenSigTimeout_EPS" 0;
BA_DEF_DEF_ "GenSigTimeout_ESP_ABR" 0;
BA_DEF_DEF_ "GenSigTimeout_IC" 0;
BA_DEF_DEF_ "GenSigTimeout_MPC" 0;
BA_DEF_DEF_ "GenSigTimeout_NV" 0;
BA_DEF_DEF_ "GenSigTimeout_ORC" 0;
BA_DEF_DEF_ "GenSigTimeout_PTS" 0;
BA_DEF_DEF_ "GenSigTimeout_RBTM_FL" 0;
BA_DEF_DEF_ "GenSigTimeout_RBTM_FR" 0;
BA_DEF_DEF_ "GenSigTimeout_RDU" 0;
BA_DEF_DEF_ "GenSigTimeout_SCCM" 0;
BA_DEF_DEF_ "GenSigTimeout_SPC" 0;
BA_DEF_DEF_ "GenSigTimeout_TPM" 0;
BA_DEF_DEF_ "LogSignal" "";
BA_DEF_DEF_ "MessageIdType" "normal";
BA_DEF_DEF_ "NWMBotschaft" "nein";
BA_DEF_DEF_ "NmMessage" "No";
BA_DEF_DEF_ "PektronUpdateBitType" "Not used";
BA_DEF_DEF_ "SubSystemId" 0;
BA_DEF_DEF_ "UsesChecksum" "No";
BA_DEF_DEF_REL_ "GenSigTimeoutTime" 0;
BA_ "GenMsgCycleTime" BO_ 861 1000;
BA_ "GenMsgCycleTime" BO_ 541 20;
BA_ "GenMsgCycleTime" BO_ 813 10000;
BA_ "GatewayHandlerEnum" BO_ 797 3;
BA_ "GenMsgSendType" BO_ 797 7;
BA_ "GatewayHandlerEnum" BO_ 845 3;
BA_ "GenMsgSendType" BO_ 845 7;
BA_ "GatewayHandlerEnum" BO_ 877 3;
BA_ "GenMsgSendType" BO_ 877 7;
BA_ "GatewayHandlerEnum" BO_ 893 3;
BA_ "GenMsgSendType" BO_ 893 7;
BA_ "GatewayHandlerEnum" BO_ 909 3;
BA_ "GenMsgSendType" BO_ 909 7;
BA_ "GatewayHandlerEnum" BO_ 941 3;
BA_ "GenMsgSendType" BO_ 941 7;
BA_ "GatewayHandlerEnum" BO_ 781 3;
BA_ "GenMsgSendType" BO_ 781 7;
BA_ "GatewayHandlerEnum" BO_ 957 3;
BA_ "GenMsgSendType" BO_ 957 7;
BA_ "GatewayHandlerEnum" BO_ 973 3;
BA_ "GenMsgSendType" BO_ 973 7;
BA_ "GatewayHandlerEnum" BO_ 989 3;
BA_ "GenMsgSendType" BO_ 989 7;
BA_ "GenMsgCycleTime" BO_ 925 100;
BA_ "GatewayHandlerEnum" BO_ 1629 4;
BA_ "GenMsgSendType" BO_ 1629 8;
BA_ "MessageIdType" BO_ 1629 2;
BA_ "GenMsgCycleTime" BO_ 1804 100;
BA_ "AlertLogSubSystemId" BO_ 1420 78;
BA_ "GatewayHandlerEnum" BO_ 1420 2;
BA_ "GenMsgSendType" BO_ 1420 8;
BA_ "GenMsgSendType" BO_ 1532 8;
BA_ "MessageIdType" BO_ 1532 6;
BA_ "GenMsgCycleTime" BO_ 908 1000;
BA_ "GenMsgCycleTime" BO_ 524 100;
BA_ "GenMsgForceMiaCheck" BO_ 524 1;
BA_ "DiagResponse" BO_ 1628 1;
BA_ "GatewayHandlerEnum" BO_ 1628 4;
BA_ "GenMsgSendType" BO_ 1628 8;
BA_ "MessageIdType" BO_ 1628 2;
BA_ "GenMsgCycleTime" BO_ 1436 1000;
BA_ "GenMsgCycleTime" BO_ 796 1000;
BA_ "GenMsgSendType" BO_ 757 8;
BA_ "GenMsgStartValue" BO_ 757 "FFFF0000000000FFh";
BA_ "MessageIdType" BO_ 757 10;
BA_ "GatewayMessageSendType" BO_ 415 1;
BA_ "GenMsgCycleTime" BO_ 415 1000;
BA_ "GenMsgStartValue" BO_ 415 "0FFFFFFFFFFFFFFFh";
BA_ "MessageIdType" BO_ 415 10;
BA_ "GatewayMessageSendType" BO_ 536 1;
BA_ "GenMsgCycleTime" BO_ 536 500;
BA_ "GatewayMessageSendType" BO_ 538 1;
BA_ "GenMsgCycleTime" BO_ 538 1000;
BA_ "GatewayMessageSendType" BO_ 904 1;
BA_ "GenMsgCycleTime" BO_ 904 100;
BA_ "GenMsgCycleTime" BO_ 2043 1000;
BA_ "GatewayMessageSendType" BO_ 952 1;
BA_ "GenMsgCycleTime" BO_ 952 1000;
BA_ "GatewayMessageSendType" BO_ 953 1;
BA_ "GenMsgCycleTime" BO_ 953 1000;
BA_ "GenMsgCycleTime" BO_ 1028 100;
BA_ "GenMsgStartValue" BO_ 1028 "FFFFFFFFFFFFFFFFh";
BA_ "MessageIdType" BO_ 1028 10;
BA_ "NWMBotschaft" BO_ 1028 1;
BA_ "GenMsgCycleTime" BO_ 1026 100;
BA_ "GenMsgSaltingFunction" BO_ 1026 1;
BA_ "GenMsgStartValue" BO_ 1026 "FFFFFFFFFFFFFFFFh";
BA_ "MessageIdType" BO_ 1026 10;
BA_ "NWMBotschaft" BO_ 1026 1;
BA_ "GenMsgCycleTime" BO_ 771 1000;
BA_ "DiagResponse" BO_ 1619 1;
BA_ "GatewayHandlerEnum" BO_ 1619 4;
BA_ "GenMsgSendType" BO_ 1619 8;
BA_ "MessageIdType" BO_ 1619 2;
BA_ "AlertLogSubSystemId" BO_ 1485 238;
BA_ "GatewayHandlerEnum" BO_ 1485 2;
BA_ "GenMsgSendType" BO_ 1485 8;
BA_ "GenMsgCycleTime" BO_ 910 1000;
BA_ "GenMsgCycleTime" BO_ 894 1000;
BA_ "AlertLogSubSystemId" BO_ 1486 93;
BA_ "GatewayHandlerEnum" BO_ 1486 2;
BA_ "GenMsgSendType" BO_ 1486 8;
BA_ "FieldType" SG_ 861 IBST_d000_bmsInitTestFail "DTC_VALUES";
BA_ "FieldType" SG_ 861 IBST_d001_bmcSingleTransTest "DTC_VALUES";
BA_ "FieldType" SG_ 861 IBST_d002_tle5012SsccrcFail "DTC_VALUES";
BA_ "FieldType" SG_ 861 IBST_d003_tle5012Config "DTC_VALUES";
BA_ "FieldType" SG_ 861 IBST_d004_deadlMonTaskx1Ovr "DTC_VALUES";
BA_ "FieldType" SG_ 861 IBST_d005_ecuWdFltCntTstFls "DTC_VALUES";
BA_ "FieldType" SG_ 861 IBST_d006_ecuWdScheduleTout "DTC_VALUES";
BA_ "FieldType" SG_ 861 IBST_d007_ecuWdStarttestFls "DTC_VALUES";
BA_ "FieldType" SG_ 861 IBST_d008_ecuWdStatusContErr "DTC_VALUES";
BA_ "FieldType" SG_ 861 IBST_d009_netOvrvolt "DTC_VALUES";
BA_ "FieldType" SG_ 861 IBST_d010_micSpiTout "DTC_VALUES";
BA_ "FieldType" SG_ 861 IBST_d011_micSpiTransferErr "DTC_VALUES";
BA_ "FieldType" SG_ 861 IBST_d012_netUndvolt "DTC_VALUES";
BA_ "FieldType" SG_ 861 IBST_d013_xpassToutErr "DTC_VALUES";
BA_ "FieldType" SG_ 861 IBST_d014_rpsOffsEeReadEmpty "DTC_VALUES";
BA_ "FieldType" SG_ 861 IBST_d015_rtpEnaHigh "DTC_VALUES";
BA_ "FieldType" SG_ 861 IBST_d016_xpassEchoCountErr "DTC_VALUES";
BA_ "FieldType" SG_ 861 IBST_d017_preDriveChckFail "DTC_VALUES";
BA_ "FieldType" SG_ 861 IBST_d018_ucSafetyFlt "DTC_VALUES";
BA_ "FieldType" SG_ 861 IBST_d019_unsupportedHw "DTC_VALUES";
BA_ "FieldType" SG_ 861 IBST_d020_voltPreRegModeFld "DTC_VALUES";
BA_ "FieldType" SG_ 861 IBST_d021_ubbSupplyLine "DTC_VALUES";
BA_ "FieldType" SG_ 861 IBST_d022_stmAswSysTout "DTC_VALUES";
BA_ "FieldType" SG_ 861 IBST_d023_stackOvrUndFlow "DTC_VALUES";
BA_ "FieldType" SG_ 861 IBST_d024_smmOneReqsInit "DTC_VALUES";
BA_ "FieldType" SG_ 861 IBST_d025_ptsSupply "DTC_VALUES";
BA_ "FieldType" SG_ 861 IBST_d026_ptsSupplyUndvolt "DTC_VALUES";
BA_ "FieldType" SG_ 861 IBST_d027_tempB6Plaus "DTC_VALUES";
BA_ "FieldType" SG_ 861 IBST_d028_ecuWdErrCntContErr "DTC_VALUES";
BA_ "FieldType" SG_ 861 IBST_d029_bmcShortedGateTest "DTC_VALUES";
BA_ "FieldType" SG_ 861 IBST_d030_controllerDevTooBig "DTC_VALUES";
BA_ "FieldType" SG_ 861 IBST_d031_ibDtrFail "DTC_VALUES";
BA_ "FieldType" SG_ 861 IBST_d032_oc6InitTestFail "DTC_VALUES";
BA_ "FieldType" SG_ 861 IBST_d033_oc6Monitor "DTC_VALUES";
BA_ "FieldType" SG_ 861 IBST_d034_motorOscillationDet "DTC_VALUES";
BA_ "FieldType" SG_ 861 IBST_d035_rpsOffsEeReadFail "DTC_VALUES";
BA_ "FieldType" SG_ 861 IBST_d036_sysErrHook "DTC_VALUES";
BA_ "FieldType" SG_ 861 IBST_d037_calIdlePosNotPlaus "DTC_VALUES";
BA_ "FieldType" SG_ 861 IBST_d038_boostSupUndrvolt "DTC_VALUES";
BA_ "FieldType" SG_ 861 IBST_d039_calRoutineAbort "DTC_VALUES";
BA_ "FieldType" SG_ 861 IBST_d040_bmcGateUndervoltPro "DTC_VALUES";
BA_ "FieldType" SG_ 861 IBST_d041_hswInitPhseUndrvolt "DTC_VALUES";
BA_ "FieldType" SG_ 861 IBST_d042_ltmWarnLevelReached "DTC_VALUES";
BA_ "FieldType" SG_ 861 IBST_d043_rpsVctrLengthRelErr "DTC_VALUES";
BA_ "FieldType" SG_ 861 IBST_d044_b6TempDegradeLevel1 "DTC_VALUES";
BA_ "FieldType" SG_ 861 IBST_d045_B6TempDegradeLevel2 "DTC_VALUES";
BA_ "FieldType" SG_ 861 IBST_d046_spiAnglOrRawNotUp "DTC_VALUES";
BA_ "FieldType" SG_ 861 IBST_d047_dcomIboosterNotInit "DTC_VALUES";
BA_ "FieldType" SG_ 861 IBST_d048_unintendMotorReturn "DTC_VALUES";
BA_ "FieldType" SG_ 861 IBST_d049_cdmOvrvoltLevel1 "DTC_VALUES";
BA_ "FieldType" SG_ 861 IBST_d050_cdmUndrvoltLevel2 "DTC_VALUES";
BA_ "FieldType" SG_ 861 IBST_d051_cdmUndrvoltLevel1 "DTC_VALUES";
BA_ "FieldType" SG_ 861 IBST_d052_motTrvlRelReadFail "DTC_VALUES";
BA_ "FieldType" SG_ 861 IBST_d053_tle5012UnexpReset "DTC_VALUES";
BA_ "FieldType" SG_ 861 IBST_d054_bmsGateUndrvolt "DTC_VALUES";
BA_ "FieldType" SG_ 861 IBST_d055_kl15HwPlausSw "DTC_VALUES";
BA_ "FieldType" SG_ 861 IBST_d056_ibNotShutDownRight "DTC_VALUES";
BA_ "FieldType" SG_ 861 IBST_d057_cdmHardUndrvolt "DTC_VALUES";
BA_ "FieldType" SG_ 861 IBST_d058_cdmHardOvrvolt "DTC_VALUES";
BA_ "FieldType" SG_ 861 IBST_d059_maxTrvlAdjstUpdFail "DTC_VALUES";
BA_ "FieldType" SG_ 861 IBST_d060_ltmLimitReached "DTC_VALUES";
BA_ "FieldType" SG_ 861 IBST_d061_dcomEcuDefect "DTC_VALUES";
BA_ "FieldType" SG_ 861 IBST_d062_inputStroke1RngHigh "DTC_VALUES";
BA_ "FieldType" SG_ 861 IBST_d063_inputStroke1RngLow "DTC_VALUES";
BA_ "FieldType" SG_ 861 IBST_d064_inputStroke2RngHigh "DTC_VALUES";
BA_ "FieldType" SG_ 861 IBST_d065_inputStroke2RngLow "DTC_VALUES";
BA_ "FieldType" SG_ 861 IBST_d066_ibSupVoltDivDrift "DTC_VALUES";
BA_ "FieldType" SG_ 861 IBST_d067_sOutRodToPressVal "DTC_VALUES";
BA_ "FieldType" SG_ 861 IBST_d068_tle5012LifeCnt "DTC_VALUES";
BA_ "FieldType" SG_ 861 IBST_d069_cdmExtendedUndrvolt "DTC_VALUES";
BA_ "FieldType" SG_ 861 IBST_d070_cdmExtendedOvrvolt "DTC_VALUES";
BA_ "FieldType" SG_ 861 IBST_d071_tempB6Ch1LineHigh "DTC_VALUES";
BA_ "FieldType" SG_ 861 IBST_d072_tempB6Ch1LineLow "DTC_VALUES";
BA_ "FieldType" SG_ 861 IBST_d073_tempB6Ch2LineHigh "DTC_VALUES";
BA_ "FieldType" SG_ 861 IBST_d074_tempB6Ch2LineLow "DTC_VALUES";
BA_ "FieldType" SG_ 861 IBST_d075_hevSwitchOffDcom "DTC_VALUES";
BA_ "FieldType" SG_ 861 IBST_d076_tle5012VoltFail "DTC_VALUES";
BA_ "FieldType" SG_ 861 IBST_d077_bcsFltCurrentHigh "DTC_VALUES";
BA_ "FieldType" SG_ 861 IBST_d078_bcsFltCurrentLow "DTC_VALUES";
BA_ "FieldType" SG_ 861 IBST_d079_ecuSupVoltDivDrift "DTC_VALUES";
BA_ "FieldType" SG_ 861 IBST_d080_inputstroke1Grad "DTC_VALUES";
BA_ "FieldType" SG_ 861 IBST_d081_pts1Err "DTC_VALUES";
BA_ "FieldType" SG_ 861 IBST_d082_pts1LineGnd "DTC_VALUES";
BA_ "FieldType" SG_ 861 IBST_d083_pts1LineHigh "DTC_VALUES";
BA_ "FieldType" SG_ 861 IBST_d084_inputStroke2Grad "DTC_VALUES";
BA_ "FieldType" SG_ 861 IBST_d085_pts2Err "DTC_VALUES";
BA_ "FieldType" SG_ 861 IBST_d086_pts2LineGnd "DTC_VALUES";
BA_ "FieldType" SG_ 861 IBST_d087_pts2LineHigh "DTC_VALUES";
BA_ "FieldType" SG_ 861 IBST_d088_faildevInputStroke "DTC_VALUES";
BA_ "FieldType" SG_ 861 IBST_d089_ptsOffsTooHigh "DTC_VALUES";
BA_ "FieldType" SG_ 861 IBST_d090_pbistErr "DTC_VALUES";
BA_ "FieldType" SG_ 861 IBST_d091_ramInitErr "DTC_VALUES";
BA_ "FieldType" SG_ 861 IBST_d092_ramsinlgeFlt "DTC_VALUES";
BA_ "FieldType" SG_ 861 IBST_d093_bertFlt "DTC_VALUES";
BA_ "FieldType" SG_ 861 IBST_d094_CalDataNotPlaus "DTC_VALUES";
BA_ "FieldType" SG_ 861 IBST_d095_canEHwError "DTC_VALUES";
BA_ "FieldType" SG_ 861 IBST_d096_canETout "DTC_VALUES";
BA_ "FieldType" SG_ 861 IBST_d097_cpuException "DTC_VALUES";
BA_ "FieldType" SG_ 861 IBST_d098_ecuBandGap "DTC_VALUES";
BA_ "FieldType" SG_ 861 IBST_d099_ecuBmsOnWhileWdTout "DTC_VALUES";
BA_ "FieldType" SG_ 861 IBST_d100_ecuErrpinCntTstFls "DTC_VALUES";
BA_ "FieldType" SG_ 861 IBST_d101_ecuHetException "DTC_VALUES";
BA_ "FieldType" SG_ 861 IBST_d102_ecuHetTuAddErr "DTC_VALUES";
BA_ "FieldType" SG_ 861 IBST_d103_ecuHetTuBusErr "DTC_VALUES";
BA_ "FieldType" SG_ 861 IBST_d104_ecuHetTuBusyErr "DTC_VALUES";
BA_ "FieldType" SG_ 861 IBST_d105_ecuHetTuException "DTC_VALUES";
BA_ "FieldType" SG_ 861 IBST_d106_ecuTaskMissing "DTC_VALUES";
BA_ "FieldType" SG_ 861 IBST_d107_hetRefError "DTC_VALUES";
BA_ "FieldType" SG_ 861 IBST_d108_micInitSpiTstFld "DTC_VALUES";
BA_ "FieldType" SG_ 861 IBST_d109_micInitSpiTransfErr "DTC_VALUES";
BA_ "FieldType" SG_ 861 IBST_d110_micIntMonGenBitMon "DTC_VALUES";
BA_ "FieldType" SG_ 861 IBST_d111_micIntVoltMonFld "DTC_VALUES";
BA_ "FieldType" SG_ 861 IBST_d112_motPosTrvlReadEmpty "DTC_VALUES";
BA_ "FieldType" SG_ 861 IBST_d113_motAngBoundReadEmpt "DTC_VALUES";
BA_ "FieldType" SG_ 861 IBST_d114_motShaftShiftDetect "DTC_VALUES";
BA_ "FieldType" SG_ 861 IBST_d115_osErrHook "DTC_VALUES";
BA_ "FieldType" SG_ 861 IBST_d116_pdurEInitFail "DTC_VALUES";
BA_ "FieldType" SG_ 861 IBST_d117_pdurEPduInstLost "DTC_VALUES";
BA_ "FieldType" SG_ 861 IBST_d118_pts1OffsEeReadEmpty "DTC_VALUES";
BA_ "FieldType" SG_ 861 IBST_d119_pts2OffsEeReadEmpty "DTC_VALUES";
BA_ "FieldType" SG_ 861 IBST_d120_rpsOffsXEeReadFail "DTC_VALUES";
BA_ "FieldType" SG_ 861 IBST_d121_rpsOffsYEeReadFail "DTC_VALUES";
BA_ "FieldType" SG_ 861 IBST_d122_rpsSynchEeReadFail "DTC_VALUES";
BA_ "FieldType" SG_ 861 IBST_d123_rpsAnglRecalcErr "DTC_VALUES";
BA_ "FieldType" SG_ 861 IBST_d124_motTrvlRelWriteFail "DTC_VALUES";
BA_ "FieldType" SG_ 861 IBST_d125_motTrvlRelReadEmpty "DTC_VALUES";
BA_ "FieldType" SG_ 861 IBST_d126_ptsEeReadEmpty "DTC_VALUES";
BA_ "FieldType" SG_ 861 IBST_d127_ecuAdcConversionErr "DTC_VALUES";
BA_ "FieldType" SG_ 861 IBST_d128_ecuAdcSelftestErr "DTC_VALUES";
BA_ "FieldType" SG_ 861 IBST_d129_ccmFlt "DTC_VALUES";
BA_ "FieldType" SG_ 861 IBST_d130_ecuRomCheck "DTC_VALUES";
BA_ "FieldType" SG_ 861 IBST_d131_esmNmiFlt "DTC_VALUES";
BA_ "FieldType" SG_ 861 IBST_d132_esmSafetyFlt "DTC_VALUES";
BA_ "FieldType" SG_ 861 IBST_d133_motPosTrvlReadFail "DTC_VALUES";
BA_ "FieldType" SG_ 861 IBST_d134_motPosTrvlWriteFail "DTC_VALUES";
BA_ "FieldType" SG_ 861 IBST_d135_motAnglBndReadErr "DTC_VALUES";
BA_ "FieldType" SG_ 861 IBST_d136_motAnglBndWriteErr "DTC_VALUES";
BA_ "FieldType" SG_ 861 IBST_d137_motAnglGradTooLarge "DTC_VALUES";
BA_ "FieldType" SG_ 861 IBST_d138_pdmCustomerIdMis "DTC_VALUES";
BA_ "FieldType" SG_ 861 IBST_d139_pdmDtFormatMis "DTC_VALUES";
BA_ "FieldType" SG_ 861 IBST_d140_pdmOutOfMemory "DTC_VALUES";
BA_ "FieldType" SG_ 861 IBST_d141_pdmFieldSizeMis "DTC_VALUES";
BA_ "FieldType" SG_ 861 IBST_d142_pdmHwAcsErr "DTC_VALUES";
BA_ "FieldType" SG_ 861 IBST_d143_pdmInternalHWErr "DTC_VALUES";
BA_ "FieldType" SG_ 861 IBST_d144_ptsCalHysWritFail "DTC_VALUES";
BA_ "FieldType" SG_ 861 IBST_d145_ptsCalValuesChkFail "DTC_VALUES";
BA_ "FieldType" SG_ 861 IBST_d146_pts1CalEeReadFail "DTC_VALUES";
BA_ "FieldType" SG_ 861 IBST_d147_pts1CalEeWriteFail "DTC_VALUES";
BA_ "FieldType" SG_ 861 IBST_d148_rpsFailCompErr "DTC_VALUES";
BA_ "FieldType" SG_ 861 IBST_d149_pts1OffsEeWriteFail "DTC_VALUES";
BA_ "FieldType" SG_ 861 IBST_d150_pts2CalEeReadFail "DTC_VALUES";
BA_ "FieldType" SG_ 861 IBST_d151_pts2CalEeWriteFail "DTC_VALUES";
BA_ "FieldType" SG_ 861 IBST_d152_pts2OffsEeReadFail "DTC_VALUES";
BA_ "FieldType" SG_ 861 IBST_d153_pts2OffsEeWriteFail "DTC_VALUES";
BA_ "FieldType" SG_ 861 IBST_d154_rpsOffsXEeReadEmpty "DTC_VALUES";
BA_ "FieldType" SG_ 861 IBST_d155_rpsOffsXEeWriteFail "DTC_VALUES";
BA_ "FieldType" SG_ 861 IBST_d156_rpsOffsYEeReadEmpty "DTC_VALUES";
BA_ "FieldType" SG_ 861 IBST_d157_rpsOffsYEeWriteFail "DTC_VALUES";
BA_ "FieldType" SG_ 861 IBST_d158_rpsSynchEeReadEmpty "DTC_VALUES";
BA_ "FieldType" SG_ 861 IBST_d159_rpsSynchEeWriteFail "DTC_VALUES";
BA_ "FieldType" SG_ 861 IBST_d160_assertionFail "DTC_VALUES";
BA_ "FieldType" SG_ 861 IBST_d161_comsclBrkPrsPduLen "DTC_VALUES";
BA_ "FieldType" SG_ 861 IBST_d162_comsclBrkPrsPduTout "DTC_VALUES";
BA_ "FieldType" SG_ 861 IBST_d163_comsclEspIb1CntErr "DTC_VALUES";
BA_ "FieldType" SG_ 861 IBST_d164_comsclEspIb1CsErr "DTC_VALUES";
BA_ "FieldType" SG_ 861 IBST_d165_comsclEspIb1DlcErr "DTC_VALUES";
BA_ "FieldType" SG_ 861 IBST_d166_comsclEspIb1Tout "DTC_VALUES";
BA_ "FieldType" SG_ 861 IBST_d167_comsclEspIb2CntErr "DTC_VALUES";
BA_ "FieldType" SG_ 861 IBST_d168_comsclEspIb2CsErr "DTC_VALUES";
BA_ "FieldType" SG_ 861 IBST_d169_comsclEspIb2DlcErr "DTC_VALUES";
BA_ "FieldType" SG_ 861 IBST_d170_comsclEspIb2Tout "DTC_VALUES";
BA_ "FieldType" SG_ 861 IBST_d171_comsclEspIb3CntErr "DTC_VALUES";
BA_ "FieldType" SG_ 861 IBST_d172_comsclEspIb3CsErr "DTC_VALUES";
BA_ "FieldType" SG_ 861 IBST_d173_comsclEspIb3DlcErr "DTC_VALUES";
BA_ "FieldType" SG_ 861 IBST_d174_comsclEspIb3Tout "DTC_VALUES";
BA_ "FieldType" SG_ 861 IBST_d175_comsclGtwEsp1CntErr "DTC_VALUES";
BA_ "FieldType" SG_ 861 IBST_d176_comsclGtwEsp1CsErr "DTC_VALUES";
BA_ "FieldType" SG_ 861 IBST_d177_comsclGtwEsp1Corrpt "DTC_VALUES";
BA_ "FieldType" SG_ 861 IBST_d178_comsclGtwEsp1Tout "DTC_VALUES";
BA_ "FieldType" SG_ 861 IBST_d179_dcomSmrtActuNotInit "DTC_VALUES";
BA_ "FieldType" SG_ 861 IBST_d180_rpsLengthAbsolHigh "DTC_VALUES";
BA_ "FieldType" SG_ 861 IBST_d181_rpsLengthAbsolLow "DTC_VALUES";
BA_ "FieldType" SG_ 861 IBST_d182_shutDownEeReadFail "DTC_VALUES";
BA_ "FieldType" SG_ 861 IBST_d183_shutDownEeWriteFail "DTC_VALUES";
BA_ "FieldType" SG_ 861 IBST_d184_maxTrvlAdjstReadErr "DTC_VALUES";
BA_ "FieldType" SG_ 861 IBST_d185_psOffsMcEeReadFail "DTC_VALUES";
BA_ "FieldType" SG_ 861 IBST_d186_psOffsMcEeWriteFail "DTC_VALUES";
BA_ "FieldType" SG_ 861 IBST_d187_ltmSelfProtDeact "DTC_VALUES";
BA_ "FieldType" SG_ 861 IBST_d188_pts1OffsEeReadFail "DTC_VALUES";
BA_ "FieldType" SG_ 861 IBST_d189_diffStrokeRange "DTC_VALUES";
BA_ "FieldType" SG_ 861 IBST_d190_notProgVin "DTC_VALUES";
BA_ "FieldType" SG_ 861 IBST_d191_plausVin "DTC_VALUES";
BA_ "FieldType" SG_ 861 IBST_d192_dlCorCSumVin "DTC_VALUES";
BA_ "FieldType" SG_ 861 IBST_d193_ToutVin "DTC_VALUES";
BA_ "FieldType" SG_ 861 IBST_d194_ecuEnableB6Fail "DTC_VALUES";
BA_ "FieldType" SG_ 861 IBST_d195_ecuIbEnContErr "DTC_VALUES";
BA_ "FieldType" SG_ 861 IBST_d196_sclEspIb1pEstMax "DTC_VALUES";
BA_ "FieldType" SG_ 861 IBST_d197_sclEspIb1VehSpd "DTC_VALUES";
BA_ "FieldType" SG_ 861 IBST_d198_sclEspIb2pLimExt "DTC_VALUES";
BA_ "FieldType" SG_ 861 IBST_d199_sclEspIb2qTarExt "DTC_VALUES";
BA_ "FieldType" SG_ 861 IBST_d200_sclEspIb3pFBlend "DTC_VALUES";
BA_ "FieldType" SG_ 861 IBST_d201_sclEspIb3pMc1 "DTC_VALUES";
BA_ "FieldType" SG_ 861 IBST_d202_sclEspIb3pTarDriver "DTC_VALUES";
BA_ "FieldType" SG_ 861 IBST_d203_netBusOffNet0 "DTC_VALUES";
BA_ "FieldType" SG_ 861 IBST_d204_netErrPassivNet0 "DTC_VALUES";
BA_ "FieldType" SG_ 861 IBST_d205_netBusOffNet1 "DTC_VALUES";
BA_ "FieldType" SG_ 861 IBST_d206_netErrPassivNet1 "DTC_VALUES";
BA_ "FieldType" SG_ 861 IBST_d207_maxStrokeReached "DTC_VALUES";
BA_ "FieldType" SG_ 861 IBST_d208_sysSwClockMismatch "DTC_VALUES";
BA_ "FieldType" SG_ 861 IBST_d209_comsclGtwOdoCorrpt "DTC_VALUES";
BA_ "FieldType" SG_ 861 IBST_d210_comsclGtwStatCorrpt "DTC_VALUES";
BA_ "FieldType" SG_ 861 IBST_d211_comsclEpbStatCorrpt "DTC_VALUES";
BA_ "FieldType" SG_ 861 IBST_d212_comsclGtwOdoTout "DTC_VALUES";
BA_ "FieldType" SG_ 861 IBST_d213_comsclGtwStatTout "DTC_VALUES";
BA_ "FieldType" SG_ 861 IBST_d214_comsclEpbStatTout "DTC_VALUES";
BA_ "FieldType" SG_ 861 IBST_d215_comSclEpbStatCsErr "DTC_VALUES";
BA_ "FieldType" SG_ 861 IBST_d216_comSclEpbStatCntFlt "DTC_VALUES";
BA_ "FieldType" SG_ 861 IBST_d217_comSclDiTrq1Tout "DTC_VALUES";
BA_ "FieldType" SG_ 861 IBST_d218_comSclDiTrq1Corrpt "DTC_VALUES";
BA_ "FieldType" SG_ 861 IBST_d219_comSclDiTrq1CsErr "DTC_VALUES";
BA_ "FieldType" SG_ 861 IBST_d220_comSclDiTrq1CntFlt "DTC_VALUES";
BA_ "GenSigSNA" SG_ 541 IBST_brakeTorqueTarget "8191";
BA_ "GenSigStartValue" SG_ 813 IBST_applicationCrc 4294967295;
BA_ "GenSigStartValue" SG_ 813 IBST_variantCrc 4294967295;
BA_ "LogSignal" SG_ 925 IBST_iBoosterStatus "onChange";
BA_ "FieldType" SG_ 925 IBST_brakeInputStroke "IBST_brakeInputStroke";
BA_ "GenSigSNA" SG_ 925 IBST_brakeInputStroke "1023";
BA_ "GenSigStartValue" SG_ 925 IBST_brakeInputStroke 10;
BA_ "GenSigSendType" SG_ 1629 IBST_udsResponseData 7;
BA_ "FieldType" SG_ 1804 IC_10Hz_state "IC_state";
BA_ "FieldType" SG_ 1804 IC_10Hz_last_state "IC_state";
BA_ "FieldType" SG_ 1420 IC_alertID "IC_alerts";
BA_ "FieldType" SG_ 1420 IC_canErrorType "CAN_error";
BA_ "FieldType" SG_ 812 IC_infoIndex "infoIndex";
BA_ "GenSigCycleTime" SG_ 812 IC_infoIndex 1000;
BA_ "GenSigStartValue" SG_ 812 IC_applicationCrc 4294967295;
BA_ "GenSigSNA" SG_ 812 IC_FPGA_version "255";
BA_ "GenSigStartValue" SG_ 812 IC_FPGA_version 255;
BA_ "GenSigStartValue" SG_ 812 IC_platformTyp 255;
BA_ "LogSignal" SG_ 524 IC_backlightOn "onChange";
BA_ "LogSignal" SG_ 524 IC_tegraAlive "onChange";
BA_ "FieldType" SG_ 524 IC_LEDBrightnessClass "IC_LEDBrightnessRank";
BA_ "GenSigSendType" SG_ 1628 IC_udsResponse 7;
BA_ "GenSigStartValue" SG_ 1436 IC_platformType 255;
BA_ "GenSigStartValue" SG_ 1436 IC_platformMajorVersion 255;
BA_ "GenSigStartValue" SG_ 1436 IC_platformBranchOrigin 255;
BA_ "GenSigStartValue" SG_ 1436 IC_platformMaturity 255;
BA_ "GenSigStartValue" SG_ 1436 IC_componentMajorVersion 255;
BA_ "GenSigStartValue" SG_ 1436 IC_componentBranchOrigin 255;
BA_ "GenSigStartValue" SG_ 1436 IC_componentMaturity 255;
BA_ "GenSigStartValue" SG_ 1436 IC_componentHardwareRevision 255;
BA_ "FlexKomComment" SG_ 757 TxDrvPosn_Disp_Rq_ISM "Shift by wire display request";
BA_ "FlexKomIsMotorola" SG_ 757 TxDrvPosn_Disp_Rq_ISM 1;
BA_ "FlexKomSID" SG_ 757 TxDrvPosn_Disp_Rq_ISM 117440559;
BA_ "FlexKomSigLaenge" SG_ 757 TxDrvPosn_Disp_Rq_ISM 64;
BA_ "FlexKomSigName" SG_ 757 TxDrvPosn_Disp_Rq_ISM "SBW_Disp_Rq_ISM";
BA_ "FlexKomSigStartPos" SG_ 757 TxDrvPosn_Disp_Rq_ISM 7;
BA_ "FlexKomSigStartValue" SG_ 757 TxDrvPosn_Disp_Rq_ISM "FFFF0000000000FFh";
BA_ "GenSigSNA" SG_ 757 TxDrvPosn_Disp_Rq_ISM "255";
BA_ "GenSigSendType" SG_ 757 TxDrvPosn_Disp_Rq_ISM 7;
BA_ "GenSigStartValue" SG_ 757 TxDrvPosn_Disp_Rq_ISM 255;
BA_ "GenSigTimeout_IC" SG_ 757 TxDrvPosn_Disp_Rq_ISM 2100;
BA_ "GenSigTimeout_SCCM" SG_ 757 TxDrvPosn_Disp_Rq_ISM 2100;
BA_ "FlexKomComment" SG_ 757 SBW_Msg_Disp_Rq_ISM "Shift by wire display request";
BA_ "FlexKomIsMotorola" SG_ 757 SBW_Msg_Disp_Rq_ISM 1;
BA_ "FlexKomSID" SG_ 757 SBW_Msg_Disp_Rq_ISM 117440559;
BA_ "FlexKomSigLaenge" SG_ 757 SBW_Msg_Disp_Rq_ISM 64;
BA_ "FlexKomSigName" SG_ 757 SBW_Msg_Disp_Rq_ISM "SBW_Disp_Rq_ISM";
BA_ "FlexKomSigStartPos" SG_ 757 SBW_Msg_Disp_Rq_ISM 7;
BA_ "FlexKomSigStartValue" SG_ 757 SBW_Msg_Disp_Rq_ISM "FFFF0000000000FFh";
BA_ "GenSigSendType" SG_ 757 SBW_Msg_Disp_Rq_ISM 7;
BA_ "GenSigTimeout_IC" SG_ 757 SBW_Msg_Disp_Rq_ISM 2100;
BA_ "FlexKomComment" SG_ 757 SBW_Beep_Rq_ISM "Shift by wire display request";
BA_ "FlexKomIsMotorola" SG_ 757 SBW_Beep_Rq_ISM 1;
BA_ "FlexKomSID" SG_ 757 SBW_Beep_Rq_ISM 117440559;
BA_ "FlexKomSigLaenge" SG_ 757 SBW_Beep_Rq_ISM 64;
BA_ "FlexKomSigName" SG_ 757 SBW_Beep_Rq_ISM "SBW_Disp_Rq_ISM";
BA_ "FlexKomSigStartPos" SG_ 757 SBW_Beep_Rq_ISM 7;
BA_ "FlexKomSigStartValue" SG_ 757 SBW_Beep_Rq_ISM "FFFF0000000000FFh";
BA_ "GenSigSendType" SG_ 757 SBW_Beep_Rq_ISM 7;
BA_ "GenSigTimeout_IC" SG_ 757 SBW_Beep_Rq_ISM 2100;
BA_ "FlexKomComment" SG_ 757 TSL_MtnLk1_Disp_Rq_ISM "Shift by wire display request";
BA_ "FlexKomIsMotorola" SG_ 757 TSL_MtnLk1_Disp_Rq_ISM 1;
BA_ "FlexKomSID" SG_ 757 TSL_MtnLk1_Disp_Rq_ISM 117440559;
BA_ "FlexKomSigLaenge" SG_ 757 TSL_MtnLk1_Disp_Rq_ISM 64;
BA_ "FlexKomSigName" SG_ 757 TSL_MtnLk1_Disp_Rq_ISM "SBW_Disp_Rq_ISM";
BA_ "FlexKomSigStartPos" SG_ 757 TSL_MtnLk1_Disp_Rq_ISM 7;
BA_ "FlexKomSigStartValue" SG_ 757 TSL_MtnLk1_Disp_Rq_ISM "FFFF0000000000FFh";
BA_ "GenSigSendType" SG_ 757 TSL_MtnLk1_Disp_Rq_ISM 7;
BA_ "GenSigTimeout_IC" SG_ 757 TSL_MtnLk1_Disp_Rq_ISM 2100;
BA_ "FlexKomComment" SG_ 757 TSL_MtnLk2_Disp_Rq_ISM "Shift by wire display request";
BA_ "FlexKomIsMotorola" SG_ 757 TSL_MtnLk2_Disp_Rq_ISM 1;
BA_ "FlexKomSID" SG_ 757 TSL_MtnLk2_Disp_Rq_ISM 117440559;
BA_ "FlexKomSigLaenge" SG_ 757 TSL_MtnLk2_Disp_Rq_ISM 64;
BA_ "FlexKomSigName" SG_ 757 TSL_MtnLk2_Disp_Rq_ISM "SBW_Disp_Rq_ISM";
BA_ "FlexKomSigStartPos" SG_ 757 TSL_MtnLk2_Disp_Rq_ISM 7;
BA_ "FlexKomSigStartValue" SG_ 757 TSL_MtnLk2_Disp_Rq_ISM "FFFF0000000000FFh";
BA_ "GenSigSendType" SG_ 757 TSL_MtnLk2_Disp_Rq_ISM 7;
BA_ "GenSigTimeout_IC" SG_ 757 TSL_MtnLk2_Disp_Rq_ISM 2100;
BA_ "FlexKomComment" SG_ 757 TSL_MtnLk3_Disp_Rq_ISM "Shift by wire display request";
BA_ "FlexKomIsMotorola" SG_ 757 TSL_MtnLk3_Disp_Rq_ISM 1;
BA_ "FlexKomSID" SG_ 757 TSL_MtnLk3_Disp_Rq_ISM 117440559;
BA_ "FlexKomSigLaenge" SG_ 757 TSL_MtnLk3_Disp_Rq_ISM 64;
BA_ "FlexKomSigName" SG_ 757 TSL_MtnLk3_Disp_Rq_ISM "SBW_Disp_Rq_ISM";
BA_ "FlexKomSigStartPos" SG_ 757 TSL_MtnLk3_Disp_Rq_ISM 7;
BA_ "FlexKomSigStartValue" SG_ 757 TSL_MtnLk3_Disp_Rq_ISM "FFFF0000000000FFh";
BA_ "GenSigSendType" SG_ 757 TSL_MtnLk3_Disp_Rq_ISM 7;
BA_ "GenSigTimeout_IC" SG_ 757 TSL_MtnLk3_Disp_Rq_ISM 2100;
BA_ "FlexKomComment" SG_ 757 TSL_MtnLk4_Disp_Rq_ISM "Shift by wire display request";
BA_ "FlexKomIsMotorola" SG_ 757 TSL_MtnLk4_Disp_Rq_ISM 1;
BA_ "FlexKomSID" SG_ 757 TSL_MtnLk4_Disp_Rq_ISM 117440559;
BA_ "FlexKomSigLaenge" SG_ 757 TSL_MtnLk4_Disp_Rq_ISM 64;
BA_ "FlexKomSigName" SG_ 757 TSL_MtnLk4_Disp_Rq_ISM "SBW_Disp_Rq_ISM";
BA_ "FlexKomSigStartPos" SG_ 757 TSL_MtnLk4_Disp_Rq_ISM 7;
BA_ "FlexKomSigStartValue" SG_ 757 TSL_MtnLk4_Disp_Rq_ISM "FFFF0000000000FFh";
BA_ "GenSigSendType" SG_ 757 TSL_MtnLk4_Disp_Rq_ISM 7;
BA_ "GenSigTimeout_IC" SG_ 757 TSL_MtnLk4_Disp_Rq_ISM 2100;
BA_ "LogSignal" SG_ 1025 LRR_verticalMisalignment "onChange";
BA_ "LogSignal" SG_ 1025 LRR_horizontMisalignment "onChange";
BA_ "GenSigSNA" SG_ 1025 LRR_lowPowerMode "3";
BA_ "FlexKomComment" SG_ 415 VehSpd_Disp "Displayed vehicle speed (without attenuation)";
BA_ "FlexKomIsMotorola" SG_ 415 VehSpd_Disp 1;
BA_ "FlexKomSID" SG_ 415 VehSpd_Disp 117440844;
BA_ "FlexKomSigLaenge" SG_ 415 VehSpd_Disp 16;
BA_ "FlexKomSigName" SG_ 415 VehSpd_Disp "VehSpd_Disp";
BA_ "FlexKomSigStartPos" SG_ 415 VehSpd_Disp 7;
BA_ "FlexKomSigStartValue" SG_ 415 VehSpd_Disp "0FFFh";
BA_ "GenSigCycleTime" SG_ 415 VehSpd_Disp 1000;
BA_ "GenSigSNA" SG_ 415 VehSpd_Disp "2047";
BA_ "GenSigSendType" SG_ 415 VehSpd_Disp 7;
BA_ "GenSigStartValue" SG_ 415 VehSpd_Disp 2047;
BA_ "GenSigTimeout_DRVU" SG_ 415 VehSpd_Disp 10500;
BA_ "GenSigTimeout_MPC" SG_ 415 VehSpd_Disp 10500;
BA_ "GenSigTimeout_NV" SG_ 415 VehSpd_Disp 6500;
BA_ "GenSigTimeout_ORC" SG_ 415 VehSpd_Disp 10500;
BA_ "GenSigTimeout_PTS" SG_ 415 VehSpd_Disp 10500;
BA_ "GenSigTimeout_SPC" SG_ 415 VehSpd_Disp 10500;
BA_ "GenSigTimeout_TPM" SG_ 415 VehSpd_Disp 15500;
BA_ "GenSigSendType" SG_ 415 SwHeat 7;
BA_ "FlexKomComment" SG_ 415 Vprzr_DryVnTmr_Stat "Vaporizer dry ventilation timer state";
BA_ "FlexKomIsMotorola" SG_ 415 Vprzr_DryVnTmr_Stat 1;
BA_ "FlexKomSID" SG_ 415 Vprzr_DryVnTmr_Stat 117450656;
BA_ "FlexKomSigLaenge" SG_ 415 Vprzr_DryVnTmr_Stat 2;
BA_ "FlexKomSigName" SG_ 415 Vprzr_DryVnTmr_Stat "Vprzr_DryVnTmr_Stat";
BA_ "FlexKomSigStartPos" SG_ 415 Vprzr_DryVnTmr_Stat 5;
BA_ "FlexKomSigStartValue" SG_ 415 Vprzr_DryVnTmr_Stat "00h";
BA_ "GenSigCycleTime" SG_ 415 Vprzr_DryVnTmr_Stat 1000;
BA_ "GenSigSNA" SG_ 415 Vprzr_DryVnTmr_Stat "3";
BA_ "GenSigSendType" SG_ 415 Vprzr_DryVnTmr_Stat 7;
BA_ "FlexKomComment" SG_ 415 AirTemp_Outsd_Disp "Displayed outside air temperature";
BA_ "FlexKomIsMotorola" SG_ 415 AirTemp_Outsd_Disp 1;
BA_ "FlexKomSID" SG_ 415 AirTemp_Outsd_Disp 117440842;
BA_ "FlexKomSigLaenge" SG_ 415 AirTemp_Outsd_Disp 8;
BA_ "FlexKomSigName" SG_ 415 AirTemp_Outsd_Disp "AirTemp_Outsd_Disp";
BA_ "FlexKomSigStartPos" SG_ 415 AirTemp_Outsd_Disp 23;
BA_ "FlexKomSigStartValue" SG_ 415 AirTemp_Outsd_Disp "FFh";
BA_ "GenSigCycleTime" SG_ 415 AirTemp_Outsd_Disp 1000;
BA_ "GenSigSNA" SG_ 415 AirTemp_Outsd_Disp "255";
BA_ "GenSigSendType" SG_ 415 AirTemp_Outsd_Disp 7;
BA_ "GenSigStartValue" SG_ 415 AirTemp_Outsd_Disp 255;
BA_ "GenSigTimeout_MPC" SG_ 415 AirTemp_Outsd_Disp 10500;
BA_ "GenSigTimeout_ORC" SG_ 415 AirTemp_Outsd_Disp 10500;
BA_ "GenSigTimeout_PTS" SG_ 415 AirTemp_Outsd_Disp 10500;
BA_ "GenSigTimeout_SPC" SG_ 415 AirTemp_Outsd_Disp 10500;
BA_ "GenSigTimeout_TPM" SG_ 415 AirTemp_Outsd_Disp 15500;
BA_ "FlexKomComment" SG_ 415 EngShutOffTm "Engine shut-off time";
BA_ "FlexKomIsMotorola" SG_ 415 EngShutOffTm 1;
BA_ "FlexKomSID" SG_ 415 EngShutOffTm 117440846;
BA_ "FlexKomSigLaenge" SG_ 415 EngShutOffTm 16;
BA_ "FlexKomSigName" SG_ 415 EngShutOffTm "EngShutOffTm";
BA_ "FlexKomSigStartPos" SG_ 415 EngShutOffTm 31;
BA_ "FlexKomSigStartValue" SG_ 415 EngShutOffTm "0FFFh";
BA_ "GenSigCycleTime" SG_ 415 EngShutOffTm 1000;
BA_ "GenSigSNA" SG_ 415 EngShutOffTm "4095";
BA_ "GenSigSendType" SG_ 415 EngShutOffTm 7;
BA_ "GenSigStartValue" SG_ 415 EngShutOffTm 4095;
BA_ "GenSigTimeout_ESP_ABR" SG_ 415 EngShutOffTm 15500;
BA_ "FlexKomComment" SG_ 415 HiBm_Enbl "High beam enable";
BA_ "FlexKomIsMotorola" SG_ 415 HiBm_Enbl 1;
BA_ "FlexKomSID" SG_ 415 HiBm_Enbl 117442846;
BA_ "FlexKomSigLaenge" SG_ 415 HiBm_Enbl 2;
BA_ "FlexKomSigName" SG_ 415 HiBm_Enbl "HiBm_Enbl";
BA_ "FlexKomSigStartPos" SG_ 415 HiBm_Enbl 29;
BA_ "FlexKomSigStartValue" SG_ 415 HiBm_Enbl "03h";
BA_ "GenSigCycleTime" SG_ 415 HiBm_Enbl 1000;
BA_ "GenSigSNA" SG_ 415 HiBm_Enbl "3";
BA_ "GenSigSendType" SG_ 415 HiBm_Enbl 7;
BA_ "GenSigStartValue" SG_ 415 HiBm_Enbl 3;
BA_ "FlexKomComment" SG_ 415 PTS_Disp_Stat_IC "PTS display state from IC";
BA_ "FlexKomIsMotorola" SG_ 415 PTS_Disp_Stat_IC 1;
BA_ "FlexKomSID" SG_ 415 PTS_Disp_Stat_IC 117442671;
BA_ "FlexKomSigLaenge" SG_ 415 PTS_Disp_Stat_IC 2;
BA_ "FlexKomSigName" SG_ 415 PTS_Disp_Stat_IC "PTS_Disp_Stat_IC";
BA_ "FlexKomSigStartPos" SG_ 415 PTS_Disp_Stat_IC 31;
BA_ "FlexKomSigStartValue" SG_ 415 PTS_Disp_Stat_IC "03h";
BA_ "GenSigCycleTime" SG_ 415 PTS_Disp_Stat_IC 1000;
BA_ "GenSigSNA" SG_ 415 PTS_Disp_Stat_IC "3";
BA_ "GenSigSendType" SG_ 415 PTS_Disp_Stat_IC 7;
BA_ "GenSigStartValue" SG_ 415 PTS_Disp_Stat_IC 3;
BA_ "GenSigCycleTime" SG_ 415 ODO 100;
BA_ "GenSigCycleTimeActive" SG_ 415 ODO 100;
BA_ "GenSigSNA" SG_ 415 ODO "16777215";
BA_ "GenSigSendType" SG_ 415 ODO 7;
BA_ "GenSigSendType" SG_ 536 MCU_parkBrakeRequest 1;
BA_ "FieldType" SG_ 536 MCU_trailerModeCH "MCU_trailerMode";
BA_ "GenSigSNA" SG_ 536 MCU_fcwSensitivity "3";
BA_ "FieldType" SG_ 536 MCU_latControlEnable "MCU_latControlEnable";
BA_ "GenSigSNA" SG_ 536 MCU_latControlEnable "3";
BA_ "GenSigSNA" SG_ 536 MCU_accOvertakeEnable "3";
BA_ "GenSigSNA" SG_ 536 MCU_ldwEnable "3";
BA_ "GenSigSNA" SG_ 536 MCU_aebEnable "3";
BA_ "GenSigSNA" SG_ 536 MCU_bsdEnable "3";
BA_ "GenSigSNA" SG_ 536 MCU_ahlbEnable "3";
BA_ "GenSigSNA" SG_ 536 MCU_parkSetting "3";
BA_ "GenSigSNA" SG_ 536 MCU_pedalSafetyEnable "3";
BA_ "GenSigSNA" SG_ 536 MCU_frontDefrostReq_das "3";
BA_ "GenSigSNA" SG_ 536 MCU_autoParkRequest "15";
BA_ "GenSigSNA" SG_ 536 MCU_redLightStopSignEnable "3";
BA_ "FieldType" SG_ 536 MCU_enableCreepTorqueCH "MCU_enableCreepTorqueCH";
BA_ "GenSigSNA" SG_ 536 MCU_overPaintedUSS "3";
BA_ "GenSigSNA" SG_ 536 MCU_selfParkTune "15";
BA_ "GenSigSNA" SG_ 536 MCU_towModeEnable "3";
BA_ "GenSigSendType" SG_ 536 MCU_towModeEnable 1;
BA_ "GenSigSNA" SG_ 536 MCU_zeroSpeedConfirmed "3";
BA_ "GenSigSendType" SG_ 536 MCU_zeroSpeedConfirmed 1;
BA_ "GenSigSNA" SG_ 536 MCU_aesEnable "3";
BA_ "GenSigSNA" SG_ 536 MCU_autoLaneChangeEnable "3";
BA_ "GenSigSendType" SG_ 904 MCU_clusterBacklightOn 1;
BA_ "GenSigSNA" SG_ 904 MCU_clusterReadyForDrive "0";
BA_ "GenSigSendType" SG_ 904 MCU_clusterReadyForDrive 1;
BA_ "GenSigSendType" SG_ 904 MCU_clusterBrightnessLevel 1;
BA_ "GenSigSNA" SG_ 952 MCU_setRcpFront "255";
BA_ "GenSigSNA" SG_ 952 MCU_setRcpRear "255";
BA_ "FlexKomComment" SG_ 1028 NM_Mode "Network management state";
BA_ "FlexKomIsMotorola" SG_ 1028 NM_Mode 1;
BA_ "FlexKomSID" SG_ 1028 NM_Mode 117441825;
BA_ "FlexKomSigLaenge" SG_ 1028 NM_Mode 32;
BA_ "FlexKomSigName" SG_ 1028 NM_Mode "NM";
BA_ "FlexKomSigStartPos" SG_ 1028 NM_Mode 7;
BA_ "FlexKomSigStartValue" SG_ 1028 NM_Mode "FFFFFFFFh";
BA_ "GenSigSNA" SG_ 1028 NM_Mode "255";
BA_ "GenSigStartValue" SG_ 1028 NM_Mode 255;
BA_ "FlexKomComment" SG_ 1028 NM_Successor "Network management state";
BA_ "FlexKomIsMotorola" SG_ 1028 NM_Successor 1;
BA_ "FlexKomSID" SG_ 1028 NM_Successor 117441825;
BA_ "FlexKomSigLaenge" SG_ 1028 NM_Successor 32;
BA_ "FlexKomSigName" SG_ 1028 NM_Successor "NM";
BA_ "FlexKomSigStartPos" SG_ 1028 NM_Successor 7;
BA_ "FlexKomSigStartValue" SG_ 1028 NM_Successor "FFFFFFFFh";
BA_ "GenSigSNA" SG_ 1028 NM_Successor "255";
BA_ "GenSigStartValue" SG_ 1028 NM_Successor 255;
BA_ "FlexKomComment" SG_ 1028 NM_Ud_Launch "Network management state";
BA_ "FlexKomIsMotorola" SG_ 1028 NM_Ud_Launch 1;
BA_ "FlexKomSID" SG_ 1028 NM_Ud_Launch 117441825;
BA_ "FlexKomSigLaenge" SG_ 1028 NM_Ud_Launch 32;
BA_ "FlexKomSigName" SG_ 1028 NM_Ud_Launch "NM";
BA_ "FlexKomSigStartPos" SG_ 1028 NM_Ud_Launch 7;
BA_ "FlexKomSigStartValue" SG_ 1028 NM_Ud_Launch "FFFFFFFFh";
BA_ "GenSigSNA" SG_ 1028 NM_Ud_Launch "63";
BA_ "GenSigStartValue" SG_ 1028 NM_Ud_Launch 63;
BA_ "FlexKomComment" SG_ 1028 NM_Sleep_Ack "Network management state";
BA_ "FlexKomIsMotorola" SG_ 1028 NM_Sleep_Ack 1;
BA_ "FlexKomSID" SG_ 1028 NM_Sleep_Ack 117441825;
BA_ "FlexKomSigLaenge" SG_ 1028 NM_Sleep_Ack 32;
BA_ "FlexKomSigName" SG_ 1028 NM_Sleep_Ack "NM";
BA_ "FlexKomSigStartPos" SG_ 1028 NM_Sleep_Ack 7;
BA_ "FlexKomSigStartValue" SG_ 1028 NM_Sleep_Ack "FFFFFFFFh";
BA_ "GenSigStartValue" SG_ 1028 NM_Sleep_Ack 1;
BA_ "FlexKomComment" SG_ 1028 NM_Sleep_Ind "Network management state";
BA_ "FlexKomIsMotorola" SG_ 1028 NM_Sleep_Ind 1;
BA_ "FlexKomSID" SG_ 1028 NM_Sleep_Ind 117441825;
BA_ "FlexKomSigLaenge" SG_ 1028 NM_Sleep_Ind 32;
BA_ "FlexKomSigName" SG_ 1028 NM_Sleep_Ind "NM";
BA_ "FlexKomSigStartPos" SG_ 1028 NM_Sleep_Ind 7;
BA_ "FlexKomSigStartValue" SG_ 1028 NM_Sleep_Ind "FFFFFFFFh";
BA_ "GenSigStartValue" SG_ 1028 NM_Sleep_Ind 1;
BA_ "FlexKomComment" SG_ 1028 NM_Ud_Srv "Network management state";
BA_ "FlexKomIsMotorola" SG_ 1028 NM_Ud_Srv 1;
BA_ "FlexKomSID" SG_ 1028 NM_Ud_Srv 117441825;
BA_ "FlexKomSigLaenge" SG_ 1028 NM_Ud_Srv 32;
BA_ "FlexKomSigName" SG_ 1028 NM_Ud_Srv "NM";
BA_ "FlexKomSigStartPos" SG_ 1028 NM_Ud_Srv 7;
BA_ "FlexKomSigStartValue" SG_ 1028 NM_Ud_Srv "FFFFFFFFh";
BA_ "GenSigSNA" SG_ 1028 NM_Ud_Srv "255";
BA_ "GenSigStartValue" SG_ 1028 NM_Ud_Srv 255;
BA_ "FlexKomComment" SG_ 1028 Nw_Id "Network identification no.";
BA_ "FlexKomIsMotorola" SG_ 1028 Nw_Id 1;
BA_ "FlexKomSID" SG_ 1028 Nw_Id 117442147;
BA_ "FlexKomSigLaenge" SG_ 1028 Nw_Id 8;
BA_ "FlexKomSigName" SG_ 1028 Nw_Id "Nw_Id";
BA_ "FlexKomSigStartPos" SG_ 1028 Nw_Id 63;
BA_ "FlexKomSigStartValue" SG_ 1028 Nw_Id "FFh";
BA_ "GenSigSNA" SG_ 1028 Nw_Id "255";
BA_ "GenSigStartValue" SG_ 1028 Nw_Id 255;
BA_ "FlexKomComment" SG_ 1028 WakeupRsn_SCCM "Userdata wakeup reason (02h)";
BA_ "FlexKomIsMotorola" SG_ 1028 WakeupRsn_SCCM 1;
BA_ "FlexKomSID" SG_ 1028 WakeupRsn_SCCM 117443021;
BA_ "FlexKomSigLaenge" SG_ 1028 WakeupRsn_SCCM 24;
BA_ "FlexKomSigName" SG_ 1028 WakeupRsn_SCCM "Wakeup_SCCM";
BA_ "FlexKomSigStartPos" SG_ 1028 WakeupRsn_SCCM 39;
BA_ "FlexKomSigStartValue" SG_ 1028 WakeupRsn_SCCM "FFFF00h";
BA_ "GenSigSNA" SG_ 1028 WakeupRsn_SCCM "255";
BA_ "GenSigStartValue" SG_ 1028 WakeupRsn_SCCM 255;
BA_ "FlexKomComment" SG_ 1028 Awake_NwSt "Userdata stay awake reason (0Fh)";
BA_ "FlexKomIsMotorola" SG_ 1028 Awake_NwSt 1;
BA_ "FlexKomSID" SG_ 1028 Awake_NwSt 117442958;
BA_ "FlexKomSigLaenge" SG_ 1028 Awake_NwSt 24;
BA_ "FlexKomSigName" SG_ 1028 Awake_NwSt "Awake_CGW";
BA_ "FlexKomSigStartPos" SG_ 1028 Awake_NwSt 39;
BA_ "FlexKomSigStartValue" SG_ 1028 Awake_NwSt "000000h";
BA_ "FlexKomComment" SG_ 1028 Awake_Diag_Actv "Userdata stay awake reason (0Fh)";
BA_ "FlexKomIsMotorola" SG_ 1028 Awake_Diag_Actv 1;
BA_ "FlexKomSID" SG_ 1028 Awake_Diag_Actv 117442958;
BA_ "FlexKomSigLaenge" SG_ 1028 Awake_Diag_Actv 24;
BA_ "FlexKomSigName" SG_ 1028 Awake_Diag_Actv "Awake_CGW";
BA_ "FlexKomSigStartPos" SG_ 1028 Awake_Diag_Actv 39;
BA_ "FlexKomSigStartValue" SG_ 1028 Awake_Diag_Actv "000000h";
BA_ "FlexKomComment" SG_ 1028 Awake_Ignition_On "Userdata stay awake reason (0Fh)";
BA_ "FlexKomIsMotorola" SG_ 1028 Awake_Ignition_On 1;
BA_ "FlexKomSID" SG_ 1028 Awake_Ignition_On 117442990;
BA_ "FlexKomSigLaenge" SG_ 1028 Awake_Ignition_On 24;
BA_ "FlexKomSigName" SG_ 1028 Awake_Ignition_On "Awake_EIS";
BA_ "FlexKomSigStartPos" SG_ 1028 Awake_Ignition_On 39;
BA_ "FlexKomSigStartValue" SG_ 1028 Awake_Ignition_On "000000h";
BA_ "FlexKomComment" SG_ 1028 Awake_Stw_Lvr_Psd "Userdata stay awake reason (0Fh)";
BA_ "FlexKomIsMotorola" SG_ 1028 Awake_Stw_Lvr_Psd 1;
BA_ "FlexKomSID" SG_ 1028 Awake_Stw_Lvr_Psd 117443032;
BA_ "FlexKomSigLaenge" SG_ 1028 Awake_Stw_Lvr_Psd 24;
BA_ "FlexKomSigName" SG_ 1028 Awake_Stw_Lvr_Psd "Awake_SCCM";
BA_ "FlexKomSigStartPos" SG_ 1028 Awake_Stw_Lvr_Psd 39;
BA_ "FlexKomSigStartValue" SG_ 1028 Awake_Stw_Lvr_Psd "000000h";
BA_ "FlexKomComment" SG_ 1028 Awake_TSL_P_Psd "Userdata stay awake reason (0Fh)";
BA_ "FlexKomIsMotorola" SG_ 1028 Awake_TSL_P_Psd 1;
BA_ "FlexKomSID" SG_ 1028 Awake_TSL_P_Psd 117443032;
BA_ "FlexKomSigLaenge" SG_ 1028 Awake_TSL_P_Psd 24;
BA_ "FlexKomSigName" SG_ 1028 Awake_TSL_P_Psd "Awake_SCCM";
BA_ "FlexKomSigStartPos" SG_ 1028 Awake_TSL_P_Psd 39;
BA_ "FlexKomSigStartValue" SG_ 1028 Awake_TSL_P_Psd "000000h";
BA_ "FlexKomComment" SG_ 1028 Awake_StwSw_Actv "Userdata stay awake reason (0Fh)";
BA_ "FlexKomIsMotorola" SG_ 1028 Awake_StwSw_Actv 1;
BA_ "FlexKomSID" SG_ 1028 Awake_StwSw_Actv 117443032;
BA_ "FlexKomSigLaenge" SG_ 1028 Awake_StwSw_Actv 24;
BA_ "FlexKomSigName" SG_ 1028 Awake_StwSw_Actv "Awake_SCCM";
BA_ "FlexKomSigStartPos" SG_ 1028 Awake_StwSw_Actv 39;
BA_ "FlexKomSigStartValue" SG_ 1028 Awake_StwSw_Actv "000000h";
BA_ "FlexKomComment" SG_ 1028 Awake_EEPROM "Userdata stay awake reason (0Fh)";
BA_ "FlexKomIsMotorola" SG_ 1028 Awake_EEPROM 1;
BA_ "FlexKomSID" SG_ 1028 Awake_EEPROM 117443032;
BA_ "FlexKomSigLaenge" SG_ 1028 Awake_EEPROM 24;
BA_ "FlexKomSigName" SG_ 1028 Awake_EEPROM "Awake_SCCM";
BA_ "FlexKomSigStartPos" SG_ 1028 Awake_EEPROM 39;
BA_ "FlexKomSigStartValue" SG_ 1028 Awake_EEPROM "000000h";
BA_ "FlexKomComment" SG_ 1026 P_NM_Mode "Network management state";
BA_ "FlexKomIsMotorola" SG_ 1026 P_NM_Mode 1;
BA_ "FlexKomSID" SG_ 1026 P_NM_Mode 117441825;
BA_ "FlexKomSigLaenge" SG_ 1026 P_NM_Mode 32;
BA_ "FlexKomSigName" SG_ 1026 P_NM_Mode "NM";
BA_ "FlexKomSigStartPos" SG_ 1026 P_NM_Mode 7;
BA_ "FlexKomSigStartValue" SG_ 1026 P_NM_Mode "FFFFFFFFh";
BA_ "GenSigSNA" SG_ 1026 P_NM_Mode "255";
BA_ "GenSigStartValue" SG_ 1026 P_NM_Mode 253;
BA_ "FlexKomComment" SG_ 1026 P_NM_Successor "Network management state";
BA_ "FlexKomIsMotorola" SG_ 1026 P_NM_Successor 1;
BA_ "FlexKomSID" SG_ 1026 P_NM_Successor 117441825;
BA_ "FlexKomSigLaenge" SG_ 1026 P_NM_Successor 32;
BA_ "FlexKomSigName" SG_ 1026 P_NM_Successor "NM";
BA_ "FlexKomSigStartPos" SG_ 1026 P_NM_Successor 7;
BA_ "FlexKomSigStartValue" SG_ 1026 P_NM_Successor "FFFFFFFFh";
BA_ "GenSigSNA" SG_ 1026 P_NM_Successor "255";
BA_ "GenSigStartValue" SG_ 1026 P_NM_Successor 4;
BA_ "FlexKomComment" SG_ 1026 P_NM_Ud_Launch "Network management state";
BA_ "FlexKomIsMotorola" SG_ 1026 P_NM_Ud_Launch 1;
BA_ "FlexKomSID" SG_ 1026 P_NM_Ud_Launch 117441825;
BA_ "FlexKomSigLaenge" SG_ 1026 P_NM_Ud_Launch 32;
BA_ "FlexKomSigName" SG_ 1026 P_NM_Ud_Launch "NM";
BA_ "FlexKomSigStartPos" SG_ 1026 P_NM_Ud_Launch 7;
BA_ "FlexKomSigStartValue" SG_ 1026 P_NM_Ud_Launch "FFFFFFFFh";
BA_ "GenSigSNA" SG_ 1026 P_NM_Ud_Launch "63";
BA_ "GenSigStartValue" SG_ 1026 P_NM_Ud_Launch 4;
BA_ "FlexKomComment" SG_ 1026 P_NM_Sleep_Ack "Network management state";
BA_ "FlexKomIsMotorola" SG_ 1026 P_NM_Sleep_Ack 1;
BA_ "FlexKomSID" SG_ 1026 P_NM_Sleep_Ack 117441825;
BA_ "FlexKomSigLaenge" SG_ 1026 P_NM_Sleep_Ack 32;
BA_ "FlexKomSigName" SG_ 1026 P_NM_Sleep_Ack "NM";
BA_ "FlexKomSigStartPos" SG_ 1026 P_NM_Sleep_Ack 7;
BA_ "FlexKomSigStartValue" SG_ 1026 P_NM_Sleep_Ack "FFFFFFFFh";
BA_ "FlexKomComment" SG_ 1026 P_NM_Sleep_Ind "Network management state";
BA_ "FlexKomIsMotorola" SG_ 1026 P_NM_Sleep_Ind 1;
BA_ "FlexKomSID" SG_ 1026 P_NM_Sleep_Ind 117441825;
BA_ "FlexKomSigLaenge" SG_ 1026 P_NM_Sleep_Ind 32;
BA_ "FlexKomSigName" SG_ 1026 P_NM_Sleep_Ind "NM";
BA_ "FlexKomSigStartPos" SG_ 1026 P_NM_Sleep_Ind 7;
BA_ "FlexKomSigStartValue" SG_ 1026 P_NM_Sleep_Ind "FFFFFFFFh";
BA_ "FlexKomComment" SG_ 1026 P_NM_Ud_Srv "Network management state";
BA_ "FlexKomIsMotorola" SG_ 1026 P_NM_Ud_Srv 1;
BA_ "FlexKomSID" SG_ 1026 P_NM_Ud_Srv 117441825;
BA_ "FlexKomSigLaenge" SG_ 1026 P_NM_Ud_Srv 32;
BA_ "FlexKomSigName" SG_ 1026 P_NM_Ud_Srv "NM";
BA_ "FlexKomSigStartPos" SG_ 1026 P_NM_Ud_Srv 7;
BA_ "FlexKomSigStartValue" SG_ 1026 P_NM_Ud_Srv "FFFFFFFFh";
BA_ "GenSigSNA" SG_ 1026 P_NM_Ud_Srv "255";
BA_ "GenSigStartValue" SG_ 1026 P_NM_Ud_Srv 15;
BA_ "FlexKomComment" SG_ 1026 P_Nw_Id "Network identification no.";
BA_ "FlexKomIsMotorola" SG_ 1026 P_Nw_Id 1;
BA_ "FlexKomSID" SG_ 1026 P_Nw_Id 117442147;
BA_ "FlexKomSigLaenge" SG_ 1026 P_Nw_Id 8;
BA_ "FlexKomSigName" SG_ 1026 P_Nw_Id "Nw_Id";
BA_ "FlexKomSigStartPos" SG_ 1026 P_Nw_Id 63;
BA_ "FlexKomSigStartValue" SG_ 1026 P_Nw_Id "FFh";
BA_ "GenSigSNA" SG_ 1026 P_Nw_Id "255";
BA_ "GenSigStartValue" SG_ 1026 P_Nw_Id 7;
BA_ "FlexKomComment" SG_ 1026 P_WakeupRsn_SCCM "Userdata wakeup reason (02h)";
BA_ "FlexKomIsMotorola" SG_ 1026 P_WakeupRsn_SCCM 1;
BA_ "FlexKomSID" SG_ 1026 P_WakeupRsn_SCCM 117443021;
BA_ "FlexKomSigLaenge" SG_ 1026 P_WakeupRsn_SCCM 24;
BA_ "FlexKomSigName" SG_ 1026 P_WakeupRsn_SCCM "Wakeup_SCCM";
BA_ "FlexKomSigStartPos" SG_ 1026 P_WakeupRsn_SCCM 39;
BA_ "FlexKomSigStartValue" SG_ 1026 P_WakeupRsn_SCCM "FFFF00h";
BA_ "GenSigSNA" SG_ 1026 P_WakeupRsn_SCCM "255";
BA_ "GenSigStartValue" SG_ 1026 P_WakeupRsn_SCCM 255;
BA_ "FlexKomComment" SG_ 1026 P_Awake_NwSt "Userdata stay awake reason (0Fh)";
BA_ "FlexKomIsMotorola" SG_ 1026 P_Awake_NwSt 1;
BA_ "FlexKomSID" SG_ 1026 P_Awake_NwSt 117442958;
BA_ "FlexKomSigLaenge" SG_ 1026 P_Awake_NwSt 24;
BA_ "FlexKomSigName" SG_ 1026 P_Awake_NwSt "Awake_CGW";
BA_ "FlexKomSigStartPos" SG_ 1026 P_Awake_NwSt 39;
BA_ "FlexKomSigStartValue" SG_ 1026 P_Awake_NwSt "000000h";
BA_ "FlexKomComment" SG_ 1026 P_Awake_Diag_Actv "Userdata stay awake reason (0Fh)";
BA_ "FlexKomIsMotorola" SG_ 1026 P_Awake_Diag_Actv 1;
BA_ "FlexKomSID" SG_ 1026 P_Awake_Diag_Actv 117442958;
BA_ "FlexKomSigLaenge" SG_ 1026 P_Awake_Diag_Actv 24;
BA_ "FlexKomSigName" SG_ 1026 P_Awake_Diag_Actv "Awake_CGW";
BA_ "FlexKomSigStartPos" SG_ 1026 P_Awake_Diag_Actv 39;
BA_ "FlexKomSigStartValue" SG_ 1026 P_Awake_Diag_Actv "000000h";
BA_ "FlexKomComment" SG_ 1026 P_Awake_Ignition_On "Userdata stay awake reason (0Fh)";
BA_ "FlexKomIsMotorola" SG_ 1026 P_Awake_Ignition_On 1;
BA_ "FlexKomSID" SG_ 1026 P_Awake_Ignition_On 117442990;
BA_ "FlexKomSigLaenge" SG_ 1026 P_Awake_Ignition_On 24;
BA_ "FlexKomSigName" SG_ 1026 P_Awake_Ignition_On "Awake_EIS";
BA_ "FlexKomSigStartPos" SG_ 1026 P_Awake_Ignition_On 39;
BA_ "FlexKomSigStartValue" SG_ 1026 P_Awake_Ignition_On "000000h";
BA_ "GenSigStartValue" SG_ 1026 P_Awake_Ignition_On 1;
BA_ "FlexKomComment" SG_ 1026 P_Awake_Stw_Lvr_Psd "Userdata stay awake reason (0Fh)";
BA_ "FlexKomIsMotorola" SG_ 1026 P_Awake_Stw_Lvr_Psd 1;
BA_ "FlexKomSID" SG_ 1026 P_Awake_Stw_Lvr_Psd 117443032;
BA_ "FlexKomSigLaenge" SG_ 1026 P_Awake_Stw_Lvr_Psd 24;
BA_ "FlexKomSigName" SG_ 1026 P_Awake_Stw_Lvr_Psd "Awake_SCCM";
BA_ "FlexKomSigStartPos" SG_ 1026 P_Awake_Stw_Lvr_Psd 39;
BA_ "FlexKomSigStartValue" SG_ 1026 P_Awake_Stw_Lvr_Psd "000000h";
BA_ "FlexKomComment" SG_ 1026 P_Awake_TSL_P_Psd "Userdata stay awake reason (0Fh)";
BA_ "FlexKomIsMotorola" SG_ 1026 P_Awake_TSL_P_Psd 1;
BA_ "FlexKomSID" SG_ 1026 P_Awake_TSL_P_Psd 117443032;
BA_ "FlexKomSigLaenge" SG_ 1026 P_Awake_TSL_P_Psd 24;
BA_ "FlexKomSigName" SG_ 1026 P_Awake_TSL_P_Psd "Awake_SCCM";
BA_ "FlexKomSigStartPos" SG_ 1026 P_Awake_TSL_P_Psd 39;
BA_ "FlexKomSigStartValue" SG_ 1026 P_Awake_TSL_P_Psd "000000h";
BA_ "FlexKomComment" SG_ 1026 P_Awake_StwSw_Actv "Userdata stay awake reason (0Fh)";
BA_ "FlexKomIsMotorola" SG_ 1026 P_Awake_StwSw_Actv 1;
BA_ "FlexKomSID" SG_ 1026 P_Awake_StwSw_Actv 117443032;
BA_ "FlexKomSigLaenge" SG_ 1026 P_Awake_StwSw_Actv 24;
BA_ "FlexKomSigName" SG_ 1026 P_Awake_StwSw_Actv "Awake_SCCM";
BA_ "FlexKomSigStartPos" SG_ 1026 P_Awake_StwSw_Actv 39;
BA_ "FlexKomSigStartValue" SG_ 1026 P_Awake_StwSw_Actv "000000h";
BA_ "FlexKomComment" SG_ 1026 P_Awake_EEPROM "Userdata stay awake reason (0Fh)";
BA_ "FlexKomIsMotorola" SG_ 1026 P_Awake_EEPROM 1;
BA_ "FlexKomSID" SG_ 1026 P_Awake_EEPROM 117443032;
BA_ "FlexKomSigLaenge" SG_ 1026 P_Awake_EEPROM 24;
BA_ "FlexKomSigName" SG_ 1026 P_Awake_EEPROM "Awake_SCCM";
BA_ "FlexKomSigStartPos" SG_ 1026 P_Awake_EEPROM 39;
BA_ "FlexKomSigStartValue" SG_ 1026 P_Awake_EEPROM "000000h";
BA_ "LogSignal" SG_ 771 OCS_occupantClassification "onChange";
BA_ "FieldType" SG_ 1485 PARK3_alertID "PARK3_alertID";
BA_ "FieldType" SG_ 1485 PARK3_alertType "PARK3_alertType";
VAL_ 861 IBST_d000_bmsInitTestFail 3 "UNABLE_TO_TEST_DTC" 2 "FAILED_DTC" 1 "PASSED_DTC" 0 "NOT_TESTED_DTC" ;
VAL_ 861 IBST_d001_bmcSingleTransTest 3 "UNABLE_TO_TEST_DTC" 2 "FAILED_DTC" 1 "PASSED_DTC" 0 "NOT_TESTED_DTC" ;
VAL_ 861 IBST_d002_tle5012SsccrcFail 3 "UNABLE_TO_TEST_DTC" 2 "FAILED_DTC" 1 "PASSED_DTC" 0 "NOT_TESTED_DTC" ;
VAL_ 861 IBST_d003_tle5012Config 3 "UNABLE_TO_TEST_DTC" 2 "FAILED_DTC" 1 "PASSED_DTC" 0 "NOT_TESTED_DTC" ;
VAL_ 861 IBST_d004_deadlMonTaskx1Ovr 3 "UNABLE_TO_TEST_DTC" 2 "FAILED_DTC" 1 "PASSED_DTC" 0 "NOT_TESTED_DTC" ;
VAL_ 861 IBST_d005_ecuWdFltCntTstFls 3 "UNABLE_TO_TEST_DTC" 2 "FAILED_DTC" 1 "PASSED_DTC" 0 "NOT_TESTED_DTC" ;
VAL_ 861 IBST_d006_ecuWdScheduleTout 3 "UNABLE_TO_TEST_DTC" 2 "FAILED_DTC" 1 "PASSED_DTC" 0 "NOT_TESTED_DTC" ;
VAL_ 861 IBST_d007_ecuWdStarttestFls 3 "UNABLE_TO_TEST_DTC" 2 "FAILED_DTC" 1 "PASSED_DTC" 0 "NOT_TESTED_DTC" ;
VAL_ 861 IBST_d008_ecuWdStatusContErr 3 "UNABLE_TO_TEST_DTC" 2 "FAILED_DTC" 1 "PASSED_DTC" 0 "NOT_TESTED_DTC" ;
VAL_ 861 IBST_d009_netOvrvolt 3 "UNABLE_TO_TEST_DTC" 2 "FAILED_DTC" 1 "PASSED_DTC" 0 "NOT_TESTED_DTC" ;
VAL_ 861 IBST_d010_micSpiTout 3 "UNABLE_TO_TEST_DTC" 2 "FAILED_DTC" 1 "PASSED_DTC" 0 "NOT_TESTED_DTC" ;
VAL_ 861 IBST_d011_micSpiTransferErr 3 "UNABLE_TO_TEST_DTC" 2 "FAILED_DTC" 1 "PASSED_DTC" 0 "NOT_TESTED_DTC" ;
VAL_ 861 IBST_d012_netUndvolt 3 "UNABLE_TO_TEST_DTC" 2 "FAILED_DTC" 1 "PASSED_DTC" 0 "NOT_TESTED_DTC" ;
VAL_ 861 IBST_d013_xpassToutErr 3 "UNABLE_TO_TEST_DTC" 2 "FAILED_DTC" 1 "PASSED_DTC" 0 "NOT_TESTED_DTC" ;
VAL_ 861 IBST_d014_rpsOffsEeReadEmpty 3 "UNABLE_TO_TEST_DTC" 2 "FAILED_DTC" 1 "PASSED_DTC" 0 "NOT_TESTED_DTC" ;
VAL_ 861 IBST_d015_rtpEnaHigh 3 "UNABLE_TO_TEST_DTC" 2 "FAILED_DTC" 1 "PASSED_DTC" 0 "NOT_TESTED_DTC" ;
VAL_ 861 IBST_d016_xpassEchoCountErr 3 "UNABLE_TO_TEST_DTC" 2 "FAILED_DTC" 1 "PASSED_DTC" 0 "NOT_TESTED_DTC" ;
VAL_ 861 IBST_d017_preDriveChckFail 3 "UNABLE_TO_TEST_DTC" 2 "FAILED_DTC" 1 "PASSED_DTC" 0 "NOT_TESTED_DTC" ;
VAL_ 861 IBST_d018_ucSafetyFlt 3 "UNABLE_TO_TEST_DTC" 2 "FAILED_DTC" 1 "PASSED_DTC" 0 "NOT_TESTED_DTC" ;
VAL_ 861 IBST_d019_unsupportedHw 3 "UNABLE_TO_TEST_DTC" 2 "FAILED_DTC" 1 "PASSED_DTC" 0 "NOT_TESTED_DTC" ;
VAL_ 861 IBST_d020_voltPreRegModeFld 3 "UNABLE_TO_TEST_DTC" 2 "FAILED_DTC" 1 "PASSED_DTC" 0 "NOT_TESTED_DTC" ;
VAL_ 861 IBST_d021_ubbSupplyLine 3 "UNABLE_TO_TEST_DTC" 2 "FAILED_DTC" 1 "PASSED_DTC" 0 "NOT_TESTED_DTC" ;
VAL_ 861 IBST_d022_stmAswSysTout 3 "UNABLE_TO_TEST_DTC" 2 "FAILED_DTC" 1 "PASSED_DTC" 0 "NOT_TESTED_DTC" ;
VAL_ 861 IBST_d023_stackOvrUndFlow 3 "UNABLE_TO_TEST_DTC" 2 "FAILED_DTC" 1 "PASSED_DTC" 0 "NOT_TESTED_DTC" ;
VAL_ 861 IBST_d024_smmOneReqsInit 3 "UNABLE_TO_TEST_DTC" 2 "FAILED_DTC" 1 "PASSED_DTC" 0 "NOT_TESTED_DTC" ;
VAL_ 861 IBST_d025_ptsSupply 3 "UNABLE_TO_TEST_DTC" 2 "FAILED_DTC" 1 "PASSED_DTC" 0 "NOT_TESTED_DTC" ;
VAL_ 861 IBST_d026_ptsSupplyUndvolt 3 "UNABLE_TO_TEST_DTC" 2 "FAILED_DTC" 1 "PASSED_DTC" 0 "NOT_TESTED_DTC" ;
VAL_ 861 IBST_d027_tempB6Plaus 3 "UNABLE_TO_TEST_DTC" 2 "FAILED_DTC" 1 "PASSED_DTC" 0 "NOT_TESTED_DTC" ;
VAL_ 861 IBST_d028_ecuWdErrCntContErr 3 "UNABLE_TO_TEST_DTC" 2 "FAILED_DTC" 1 "PASSED_DTC" 0 "NOT_TESTED_DTC" ;
VAL_ 861 IBST_d029_bmcShortedGateTest 3 "UNABLE_TO_TEST_DTC" 2 "FAILED_DTC" 1 "PASSED_DTC" 0 "NOT_TESTED_DTC" ;
VAL_ 861 IBST_d030_controllerDevTooBig 3 "UNABLE_TO_TEST_DTC" 2 "FAILED_DTC" 1 "PASSED_DTC" 0 "NOT_TESTED_DTC" ;
VAL_ 861 IBST_d031_ibDtrFail 3 "UNABLE_TO_TEST_DTC" 2 "FAILED_DTC" 1 "PASSED_DTC" 0 "NOT_TESTED_DTC" ;
VAL_ 861 IBST_d032_oc6InitTestFail 3 "UNABLE_TO_TEST_DTC" 2 "FAILED_DTC" 1 "PASSED_DTC" 0 "NOT_TESTED_DTC" ;
VAL_ 861 IBST_d033_oc6Monitor 3 "UNABLE_TO_TEST_DTC" 2 "FAILED_DTC" 1 "PASSED_DTC" 0 "NOT_TESTED_DTC" ;
VAL_ 861 IBST_d034_motorOscillationDet 3 "UNABLE_TO_TEST_DTC" 2 "FAILED_DTC" 1 "PASSED_DTC" 0 "NOT_TESTED_DTC" ;
VAL_ 861 IBST_d035_rpsOffsEeReadFail 3 "UNABLE_TO_TEST_DTC" 2 "FAILED_DTC" 1 "PASSED_DTC" 0 "NOT_TESTED_DTC" ;
VAL_ 861 IBST_d036_sysErrHook 3 "UNABLE_TO_TEST_DTC" 2 "FAILED_DTC" 1 "PASSED_DTC" 0 "NOT_TESTED_DTC" ;
VAL_ 861 IBST_d037_calIdlePosNotPlaus 3 "UNABLE_TO_TEST_DTC" 2 "FAILED_DTC" 1 "PASSED_DTC" 0 "NOT_TESTED_DTC" ;
VAL_ 861 IBST_d038_boostSupUndrvolt 3 "UNABLE_TO_TEST_DTC" 2 "FAILED_DTC" 1 "PASSED_DTC" 0 "NOT_TESTED_DTC" ;
VAL_ 861 IBST_d039_calRoutineAbort 3 "UNABLE_TO_TEST_DTC" 2 "FAILED_DTC" 1 "PASSED_DTC" 0 "NOT_TESTED_DTC" ;
VAL_ 861 IBST_d040_bmcGateUndervoltPro 3 "UNABLE_TO_TEST_DTC" 2 "FAILED_DTC" 1 "PASSED_DTC" 0 "NOT_TESTED_DTC" ;
VAL_ 861 IBST_d041_hswInitPhseUndrvolt 3 "UNABLE_TO_TEST_DTC" 2 "FAILED_DTC" 1 "PASSED_DTC" 0 "NOT_TESTED_DTC" ;
VAL_ 861 IBST_d042_ltmWarnLevelReached 3 "UNABLE_TO_TEST_DTC" 2 "FAILED_DTC" 1 "PASSED_DTC" 0 "NOT_TESTED_DTC" ;
VAL_ 861 IBST_d043_rpsVctrLengthRelErr 3 "UNABLE_TO_TEST_DTC" 2 "FAILED_DTC" 1 "PASSED_DTC" 0 "NOT_TESTED_DTC" ;
VAL_ 861 IBST_d044_b6TempDegradeLevel1 3 "UNABLE_TO_TEST_DTC" 2 "FAILED_DTC" 1 "PASSED_DTC" 0 "NOT_TESTED_DTC" ;
VAL_ 861 IBST_d045_B6TempDegradeLevel2 3 "UNABLE_TO_TEST_DTC" 2 "FAILED_DTC" 1 "PASSED_DTC" 0 "NOT_TESTED_DTC" ;
VAL_ 861 IBST_d046_spiAnglOrRawNotUp 3 "UNABLE_TO_TEST_DTC" 2 "FAILED_DTC" 1 "PASSED_DTC" 0 "NOT_TESTED_DTC" ;
VAL_ 861 IBST_d047_dcomIboosterNotInit 3 "UNABLE_TO_TEST_DTC" 2 "FAILED_DTC" 1 "PASSED_DTC" 0 "NOT_TESTED_DTC" ;
VAL_ 861 IBST_d048_unintendMotorReturn 3 "UNABLE_TO_TEST_DTC" 2 "FAILED_DTC" 1 "PASSED_DTC" 0 "NOT_TESTED_DTC" ;
VAL_ 861 IBST_d049_cdmOvrvoltLevel1 3 "UNABLE_TO_TEST_DTC" 2 "FAILED_DTC" 1 "PASSED_DTC" 0 "NOT_TESTED_DTC" ;
VAL_ 861 IBST_d050_cdmUndrvoltLevel2 3 "UNABLE_TO_TEST_DTC" 2 "FAILED_DTC" 1 "PASSED_DTC" 0 "NOT_TESTED_DTC" ;
VAL_ 861 IBST_d051_cdmUndrvoltLevel1 3 "UNABLE_TO_TEST_DTC" 2 "FAILED_DTC" 1 "PASSED_DTC" 0 "NOT_TESTED_DTC" ;
VAL_ 861 IBST_d052_motTrvlRelReadFail 3 "UNABLE_TO_TEST_DTC" 2 "FAILED_DTC" 1 "PASSED_DTC" 0 "NOT_TESTED_DTC" ;
VAL_ 861 IBST_d053_tle5012UnexpReset 3 "UNABLE_TO_TEST_DTC" 2 "FAILED_DTC" 1 "PASSED_DTC" 0 "NOT_TESTED_DTC" ;
VAL_ 861 IBST_d054_bmsGateUndrvolt 3 "UNABLE_TO_TEST_DTC" 2 "FAILED_DTC" 1 "PASSED_DTC" 0 "NOT_TESTED_DTC" ;
VAL_ 861 IBST_d055_kl15HwPlausSw 3 "UNABLE_TO_TEST_DTC" 2 "FAILED_DTC" 1 "PASSED_DTC" 0 "NOT_TESTED_DTC" ;
VAL_ 861 IBST_d056_ibNotShutDownRight 3 "UNABLE_TO_TEST_DTC" 2 "FAILED_DTC" 1 "PASSED_DTC" 0 "NOT_TESTED_DTC" ;
VAL_ 861 IBST_d057_cdmHardUndrvolt 3 "UNABLE_TO_TEST_DTC" 2 "FAILED_DTC" 1 "PASSED_DTC" 0 "NOT_TESTED_DTC" ;
VAL_ 861 IBST_d058_cdmHardOvrvolt 3 "UNABLE_TO_TEST_DTC" 2 "FAILED_DTC" 1 "PASSED_DTC" 0 "NOT_TESTED_DTC" ;
VAL_ 861 IBST_d059_maxTrvlAdjstUpdFail 3 "UNABLE_TO_TEST_DTC" 2 "FAILED_DTC" 1 "PASSED_DTC" 0 "NOT_TESTED_DTC" ;
VAL_ 861 IBST_d060_ltmLimitReached 3 "UNABLE_TO_TEST_DTC" 2 "FAILED_DTC" 1 "PASSED_DTC" 0 "NOT_TESTED_DTC" ;
VAL_ 861 IBST_d061_dcomEcuDefect 3 "UNABLE_TO_TEST_DTC" 2 "FAILED_DTC" 1 "PASSED_DTC" 0 "NOT_TESTED_DTC" ;
VAL_ 861 IBST_d062_inputStroke1RngHigh 3 "UNABLE_TO_TEST_DTC" 2 "FAILED_DTC" 1 "PASSED_DTC" 0 "NOT_TESTED_DTC" ;
VAL_ 861 IBST_d063_inputStroke1RngLow 3 "UNABLE_TO_TEST_DTC" 2 "FAILED_DTC" 1 "PASSED_DTC" 0 "NOT_TESTED_DTC" ;
VAL_ 861 IBST_d064_inputStroke2RngHigh 3 "UNABLE_TO_TEST_DTC" 2 "FAILED_DTC" 1 "PASSED_DTC" 0 "NOT_TESTED_DTC" ;
VAL_ 861 IBST_d065_inputStroke2RngLow 3 "UNABLE_TO_TEST_DTC" 2 "FAILED_DTC" 1 "PASSED_DTC" 0 "NOT_TESTED_DTC" ;
VAL_ 861 IBST_d066_ibSupVoltDivDrift 3 "UNABLE_TO_TEST_DTC" 2 "FAILED_DTC" 1 "PASSED_DTC" 0 "NOT_TESTED_DTC" ;
VAL_ 861 IBST_d067_sOutRodToPressVal 3 "UNABLE_TO_TEST_DTC" 2 "FAILED_DTC" 1 "PASSED_DTC" 0 "NOT_TESTED_DTC" ;
VAL_ 861 IBST_d068_tle5012LifeCnt 3 "UNABLE_TO_TEST_DTC" 2 "FAILED_DTC" 1 "PASSED_DTC" 0 "NOT_TESTED_DTC" ;
VAL_ 861 IBST_d069_cdmExtendedUndrvolt 3 "UNABLE_TO_TEST_DTC" 2 "FAILED_DTC" 1 "PASSED_DTC" 0 "NOT_TESTED_DTC" ;
VAL_ 861 IBST_d070_cdmExtendedOvrvolt 3 "UNABLE_TO_TEST_DTC" 2 "FAILED_DTC" 1 "PASSED_DTC" 0 "NOT_TESTED_DTC" ;
VAL_ 861 IBST_d071_tempB6Ch1LineHigh 3 "UNABLE_TO_TEST_DTC" 2 "FAILED_DTC" 1 "PASSED_DTC" 0 "NOT_TESTED_DTC" ;
VAL_ 861 IBST_d072_tempB6Ch1LineLow 3 "UNABLE_TO_TEST_DTC" 2 "FAILED_DTC" 1 "PASSED_DTC" 0 "NOT_TESTED_DTC" ;
VAL_ 861 IBST_d073_tempB6Ch2LineHigh 3 "UNABLE_TO_TEST_DTC" 2 "FAILED_DTC" 1 "PASSED_DTC" 0 "NOT_TESTED_DTC" ;
VAL_ 861 IBST_d074_tempB6Ch2LineLow 3 "UNABLE_TO_TEST_DTC" 2 "FAILED_DTC" 1 "PASSED_DTC" 0 "NOT_TESTED_DTC" ;
VAL_ 861 IBST_d075_hevSwitchOffDcom 3 "UNABLE_TO_TEST_DTC" 2 "FAILED_DTC" 1 "PASSED_DTC" 0 "NOT_TESTED_DTC" ;
VAL_ 861 IBST_d076_tle5012VoltFail 3 "UNABLE_TO_TEST_DTC" 2 "FAILED_DTC" 1 "PASSED_DTC" 0 "NOT_TESTED_DTC" ;
VAL_ 861 IBST_d077_bcsFltCurrentHigh 3 "UNABLE_TO_TEST_DTC" 2 "FAILED_DTC" 1 "PASSED_DTC" 0 "NOT_TESTED_DTC" ;
VAL_ 861 IBST_d078_bcsFltCurrentLow 3 "UNABLE_TO_TEST_DTC" 2 "FAILED_DTC" 1 "PASSED_DTC" 0 "NOT_TESTED_DTC" ;
VAL_ 861 IBST_d079_ecuSupVoltDivDrift 3 "UNABLE_TO_TEST_DTC" 2 "FAILED_DTC" 1 "PASSED_DTC" 0 "NOT_TESTED_DTC" ;
VAL_ 861 IBST_d080_inputstroke1Grad 3 "UNABLE_TO_TEST_DTC" 2 "FAILED_DTC" 1 "PASSED_DTC" 0 "NOT_TESTED_DTC" ;
VAL_ 861 IBST_d081_pts1Err 3 "UNABLE_TO_TEST_DTC" 2 "FAILED_DTC" 1 "PASSED_DTC" 0 "NOT_TESTED_DTC" ;
VAL_ 861 IBST_d082_pts1LineGnd 3 "UNABLE_TO_TEST_DTC" 2 "FAILED_DTC" 1 "PASSED_DTC" 0 "NOT_TESTED_DTC" ;
VAL_ 861 IBST_d083_pts1LineHigh 3 "UNABLE_TO_TEST_DTC" 2 "FAILED_DTC" 1 "PASSED_DTC" 0 "NOT_TESTED_DTC" ;
VAL_ 861 IBST_d084_inputStroke2Grad 3 "UNABLE_TO_TEST_DTC" 2 "FAILED_DTC" 1 "PASSED_DTC" 0 "NOT_TESTED_DTC" ;
VAL_ 861 IBST_d085_pts2Err 3 "UNABLE_TO_TEST_DTC" 2 "FAILED_DTC" 1 "PASSED_DTC" 0 "NOT_TESTED_DTC" ;
VAL_ 861 IBST_d086_pts2LineGnd 3 "UNABLE_TO_TEST_DTC" 2 "FAILED_DTC" 1 "PASSED_DTC" 0 "NOT_TESTED_DTC" ;
VAL_ 861 IBST_d087_pts2LineHigh 3 "UNABLE_TO_TEST_DTC" 2 "FAILED_DTC" 1 "PASSED_DTC" 0 "NOT_TESTED_DTC" ;
VAL_ 861 IBST_d088_faildevInputStroke 3 "UNABLE_TO_TEST_DTC" 2 "FAILED_DTC" 1 "PASSED_DTC" 0 "NOT_TESTED_DTC" ;
VAL_ 861 IBST_d089_ptsOffsTooHigh 3 "UNABLE_TO_TEST_DTC" 2 "FAILED_DTC" 1 "PASSED_DTC" 0 "NOT_TESTED_DTC" ;
VAL_ 861 IBST_d090_pbistErr 3 "UNABLE_TO_TEST_DTC" 2 "FAILED_DTC" 1 "PASSED_DTC" 0 "NOT_TESTED_DTC" ;
VAL_ 861 IBST_d091_ramInitErr 3 "UNABLE_TO_TEST_DTC" 2 "FAILED_DTC" 1 "PASSED_DTC" 0 "NOT_TESTED_DTC" ;
VAL_ 861 IBST_d092_ramsinlgeFlt 3 "UNABLE_TO_TEST_DTC" 2 "FAILED_DTC" 1 "PASSED_DTC" 0 "NOT_TESTED_DTC" ;
VAL_ 861 IBST_d093_bertFlt 3 "UNABLE_TO_TEST_DTC" 2 "FAILED_DTC" 1 "PASSED_DTC" 0 "NOT_TESTED_DTC" ;
VAL_ 861 IBST_d094_CalDataNotPlaus 3 "UNABLE_TO_TEST_DTC" 2 "FAILED_DTC" 1 "PASSED_DTC" 0 "NOT_TESTED_DTC" ;
VAL_ 861 IBST_d095_canEHwError 3 "UNABLE_TO_TEST_DTC" 2 "FAILED_DTC" 1 "PASSED_DTC" 0 "NOT_TESTED_DTC" ;
VAL_ 861 IBST_d096_canETout 3 "UNABLE_TO_TEST_DTC" 2 "FAILED_DTC" 1 "PASSED_DTC" 0 "NOT_TESTED_DTC" ;
VAL_ 861 IBST_d097_cpuException 3 "UNABLE_TO_TEST_DTC" 2 "FAILED_DTC" 1 "PASSED_DTC" 0 "NOT_TESTED_DTC" ;
VAL_ 861 IBST_d098_ecuBandGap 3 "UNABLE_TO_TEST_DTC" 2 "FAILED_DTC" 1 "PASSED_DTC" 0 "NOT_TESTED_DTC" ;
VAL_ 861 IBST_d099_ecuBmsOnWhileWdTout 3 "UNABLE_TO_TEST_DTC" 2 "FAILED_DTC" 1 "PASSED_DTC" 0 "NOT_TESTED_DTC" ;
VAL_ 861 IBST_d100_ecuErrpinCntTstFls 3 "UNABLE_TO_TEST_DTC" 2 "FAILED_DTC" 1 "PASSED_DTC" 0 "NOT_TESTED_DTC" ;
VAL_ 861 IBST_d101_ecuHetException 3 "UNABLE_TO_TEST_DTC" 2 "FAILED_DTC" 1 "PASSED_DTC" 0 "NOT_TESTED_DTC" ;
VAL_ 861 IBST_d102_ecuHetTuAddErr 3 "UNABLE_TO_TEST_DTC" 2 "FAILED_DTC" 1 "PASSED_DTC" 0 "NOT_TESTED_DTC" ;
VAL_ 861 IBST_d103_ecuHetTuBusErr 3 "UNABLE_TO_TEST_DTC" 2 "FAILED_DTC" 1 "PASSED_DTC" 0 "NOT_TESTED_DTC" ;
VAL_ 861 IBST_d104_ecuHetTuBusyErr 3 "UNABLE_TO_TEST_DTC" 2 "FAILED_DTC" 1 "PASSED_DTC" 0 "NOT_TESTED_DTC" ;
VAL_ 861 IBST_d105_ecuHetTuException 3 "UNABLE_TO_TEST_DTC" 2 "FAILED_DTC" 1 "PASSED_DTC" 0 "NOT_TESTED_DTC" ;
VAL_ 861 IBST_d106_ecuTaskMissing 3 "UNABLE_TO_TEST_DTC" 2 "FAILED_DTC" 1 "PASSED_DTC" 0 "NOT_TESTED_DTC" ;
VAL_ 861 IBST_d107_hetRefError 3 "UNABLE_TO_TEST_DTC" 2 "FAILED_DTC" 1 "PASSED_DTC" 0 "NOT_TESTED_DTC" ;
VAL_ 861 IBST_d108_micInitSpiTstFld 3 "UNABLE_TO_TEST_DTC" 2 "FAILED_DTC" 1 "PASSED_DTC" 0 "NOT_TESTED_DTC" ;
VAL_ 861 IBST_d109_micInitSpiTransfErr 3 "UNABLE_TO_TEST_DTC" 2 "FAILED_DTC" 1 "PASSED_DTC" 0 "NOT_TESTED_DTC" ;
VAL_ 861 IBST_d110_micIntMonGenBitMon 3 "UNABLE_TO_TEST_DTC" 2 "FAILED_DTC" 1 "PASSED_DTC" 0 "NOT_TESTED_DTC" ;
VAL_ 861 IBST_d111_micIntVoltMonFld 3 "UNABLE_TO_TEST_DTC" 2 "FAILED_DTC" 1 "PASSED_DTC" 0 "NOT_TESTED_DTC" ;
VAL_ 861 IBST_d112_motPosTrvlReadEmpty 3 "UNABLE_TO_TEST_DTC" 2 "FAILED_DTC" 1 "PASSED_DTC" 0 "NOT_TESTED_DTC" ;
VAL_ 861 IBST_d113_motAngBoundReadEmpt 3 "UNABLE_TO_TEST_DTC" 2 "FAILED_DTC" 1 "PASSED_DTC" 0 "NOT_TESTED_DTC" ;
VAL_ 861 IBST_d114_motShaftShiftDetect 3 "UNABLE_TO_TEST_DTC" 2 "FAILED_DTC" 1 "PASSED_DTC" 0 "NOT_TESTED_DTC" ;
VAL_ 861 IBST_d115_osErrHook 3 "UNABLE_TO_TEST_DTC" 2 "FAILED_DTC" 1 "PASSED_DTC" 0 "NOT_TESTED_DTC" ;
VAL_ 861 IBST_d116_pdurEInitFail 3 "UNABLE_TO_TEST_DTC" 2 "FAILED_DTC" 1 "PASSED_DTC" 0 "NOT_TESTED_DTC" ;
VAL_ 861 IBST_d117_pdurEPduInstLost 3 "UNABLE_TO_TEST_DTC" 2 "FAILED_DTC" 1 "PASSED_DTC" 0 "NOT_TESTED_DTC" ;
VAL_ 861 IBST_d118_pts1OffsEeReadEmpty 3 "UNABLE_TO_TEST_DTC" 2 "FAILED_DTC" 1 "PASSED_DTC" 0 "NOT_TESTED_DTC" ;
VAL_ 861 IBST_d119_pts2OffsEeReadEmpty 3 "UNABLE_TO_TEST_DTC" 2 "FAILED_DTC" 1 "PASSED_DTC" 0 "NOT_TESTED_DTC" ;
VAL_ 861 IBST_d120_rpsOffsXEeReadFail 3 "UNABLE_TO_TEST_DTC" 2 "FAILED_DTC" 1 "PASSED_DTC" 0 "NOT_TESTED_DTC" ;
VAL_ 861 IBST_d121_rpsOffsYEeReadFail 3 "UNABLE_TO_TEST_DTC" 2 "FAILED_DTC" 1 "PASSED_DTC" 0 "NOT_TESTED_DTC" ;
VAL_ 861 IBST_d122_rpsSynchEeReadFail 3 "UNABLE_TO_TEST_DTC" 2 "FAILED_DTC" 1 "PASSED_DTC" 0 "NOT_TESTED_DTC" ;
VAL_ 861 IBST_d123_rpsAnglRecalcErr 3 "UNABLE_TO_TEST_DTC" 2 "FAILED_DTC" 1 "PASSED_DTC" 0 "NOT_TESTED_DTC" ;
VAL_ 861 IBST_d124_motTrvlRelWriteFail 3 "UNABLE_TO_TEST_DTC" 2 "FAILED_DTC" 1 "PASSED_DTC" 0 "NOT_TESTED_DTC" ;
VAL_ 861 IBST_d125_motTrvlRelReadEmpty 3 "UNABLE_TO_TEST_DTC" 2 "FAILED_DTC" 1 "PASSED_DTC" 0 "NOT_TESTED_DTC" ;
VAL_ 861 IBST_d126_ptsEeReadEmpty 3 "UNABLE_TO_TEST_DTC" 2 "FAILED_DTC" 1 "PASSED_DTC" 0 "NOT_TESTED_DTC" ;
VAL_ 861 IBST_d127_ecuAdcConversionErr 3 "UNABLE_TO_TEST_DTC" 2 "FAILED_DTC" 1 "PASSED_DTC" 0 "NOT_TESTED_DTC" ;
VAL_ 861 IBST_d128_ecuAdcSelftestErr 3 "UNABLE_TO_TEST_DTC" 2 "FAILED_DTC" 1 "PASSED_DTC" 0 "NOT_TESTED_DTC" ;
VAL_ 861 IBST_d129_ccmFlt 3 "UNABLE_TO_TEST_DTC" 2 "FAILED_DTC" 1 "PASSED_DTC" 0 "NOT_TESTED_DTC" ;
VAL_ 861 IBST_d130_ecuRomCheck 3 "UNABLE_TO_TEST_DTC" 2 "FAILED_DTC" 1 "PASSED_DTC" 0 "NOT_TESTED_DTC" ;
VAL_ 861 IBST_d131_esmNmiFlt 3 "UNABLE_TO_TEST_DTC" 2 "FAILED_DTC" 1 "PASSED_DTC" 0 "NOT_TESTED_DTC" ;
VAL_ 861 IBST_d132_esmSafetyFlt 3 "UNABLE_TO_TEST_DTC" 2 "FAILED_DTC" 1 "PASSED_DTC" 0 "NOT_TESTED_DTC" ;
VAL_ 861 IBST_d133_motPosTrvlReadFail 3 "UNABLE_TO_TEST_DTC" 2 "FAILED_DTC" 1 "PASSED_DTC" 0 "NOT_TESTED_DTC" ;
VAL_ 861 IBST_d134_motPosTrvlWriteFail 3 "UNABLE_TO_TEST_DTC" 2 "FAILED_DTC" 1 "PASSED_DTC" 0 "NOT_TESTED_DTC" ;
VAL_ 861 IBST_d135_motAnglBndReadErr 3 "UNABLE_TO_TEST_DTC" 2 "FAILED_DTC" 1 "PASSED_DTC" 0 "NOT_TESTED_DTC" ;
VAL_ 861 IBST_d136_motAnglBndWriteErr 3 "UNABLE_TO_TEST_DTC" 2 "FAILED_DTC" 1 "PASSED_DTC" 0 "NOT_TESTED_DTC" ;
VAL_ 861 IBST_d137_motAnglGradTooLarge 3 "UNABLE_TO_TEST_DTC" 2 "FAILED_DTC" 1 "PASSED_DTC" 0 "NOT_TESTED_DTC" ;
VAL_ 861 IBST_d138_pdmCustomerIdMis 3 "UNABLE_TO_TEST_DTC" 2 "FAILED_DTC" 1 "PASSED_DTC" 0 "NOT_TESTED_DTC" ;
VAL_ 861 IBST_d139_pdmDtFormatMis 3 "UNABLE_TO_TEST_DTC" 2 "FAILED_DTC" 1 "PASSED_DTC" 0 "NOT_TESTED_DTC" ;
VAL_ 861 IBST_d140_pdmOutOfMemory 3 "UNABLE_TO_TEST_DTC" 2 "FAILED_DTC" 1 "PASSED_DTC" 0 "NOT_TESTED_DTC" ;
VAL_ 861 IBST_d141_pdmFieldSizeMis 3 "UNABLE_TO_TEST_DTC" 2 "FAILED_DTC" 1 "PASSED_DTC" 0 "NOT_TESTED_DTC" ;
VAL_ 861 IBST_d142_pdmHwAcsErr 3 "UNABLE_TO_TEST_DTC" 2 "FAILED_DTC" 1 "PASSED_DTC" 0 "NOT_TESTED_DTC" ;
VAL_ 861 IBST_d143_pdmInternalHWErr 3 "UNABLE_TO_TEST_DTC" 2 "FAILED_DTC" 1 "PASSED_DTC" 0 "NOT_TESTED_DTC" ;
VAL_ 861 IBST_d144_ptsCalHysWritFail 3 "UNABLE_TO_TEST_DTC" 2 "FAILED_DTC" 1 "PASSED_DTC" 0 "NOT_TESTED_DTC" ;
VAL_ 861 IBST_d145_ptsCalValuesChkFail 3 "UNABLE_TO_TEST_DTC" 2 "FAILED_DTC" 1 "PASSED_DTC" 0 "NOT_TESTED_DTC" ;
VAL_ 861 IBST_d146_pts1CalEeReadFail 3 "UNABLE_TO_TEST_DTC" 2 "FAILED_DTC" 1 "PASSED_DTC" 0 "NOT_TESTED_DTC" ;
VAL_ 861 IBST_d147_pts1CalEeWriteFail 3 "UNABLE_TO_TEST_DTC" 2 "FAILED_DTC" 1 "PASSED_DTC" 0 "NOT_TESTED_DTC" ;
VAL_ 861 IBST_d148_rpsFailCompErr 3 "UNABLE_TO_TEST_DTC" 2 "FAILED_DTC" 1 "PASSED_DTC" 0 "NOT_TESTED_DTC" ;
VAL_ 861 IBST_d149_pts1OffsEeWriteFail 3 "UNABLE_TO_TEST_DTC" 2 "FAILED_DTC" 1 "PASSED_DTC" 0 "NOT_TESTED_DTC" ;
VAL_ 861 IBST_d150_pts2CalEeReadFail 3 "UNABLE_TO_TEST_DTC" 2 "FAILED_DTC" 1 "PASSED_DTC" 0 "NOT_TESTED_DTC" ;
VAL_ 861 IBST_d151_pts2CalEeWriteFail 3 "UNABLE_TO_TEST_DTC" 2 "FAILED_DTC" 1 "PASSED_DTC" 0 "NOT_TESTED_DTC" ;
VAL_ 861 IBST_d152_pts2OffsEeReadFail 3 "UNABLE_TO_TEST_DTC" 2 "FAILED_DTC" 1 "PASSED_DTC" 0 "NOT_TESTED_DTC" ;
VAL_ 861 IBST_d153_pts2OffsEeWriteFail 3 "UNABLE_TO_TEST_DTC" 2 "FAILED_DTC" 1 "PASSED_DTC" 0 "NOT_TESTED_DTC" ;
VAL_ 861 IBST_d154_rpsOffsXEeReadEmpty 3 "UNABLE_TO_TEST_DTC" 2 "FAILED_DTC" 1 "PASSED_DTC" 0 "NOT_TESTED_DTC" ;
VAL_ 861 IBST_d155_rpsOffsXEeWriteFail 3 "UNABLE_TO_TEST_DTC" 2 "FAILED_DTC" 1 "PASSED_DTC" 0 "NOT_TESTED_DTC" ;
VAL_ 861 IBST_d156_rpsOffsYEeReadEmpty 3 "UNABLE_TO_TEST_DTC" 2 "FAILED_DTC" 1 "PASSED_DTC" 0 "NOT_TESTED_DTC" ;
VAL_ 861 IBST_d157_rpsOffsYEeWriteFail 3 "UNABLE_TO_TEST_DTC" 2 "FAILED_DTC" 1 "PASSED_DTC" 0 "NOT_TESTED_DTC" ;
VAL_ 861 IBST_d158_rpsSynchEeReadEmpty 3 "UNABLE_TO_TEST_DTC" 2 "FAILED_DTC" 1 "PASSED_DTC" 0 "NOT_TESTED_DTC" ;
VAL_ 861 IBST_d159_rpsSynchEeWriteFail 3 "UNABLE_TO_TEST_DTC" 2 "FAILED_DTC" 1 "PASSED_DTC" 0 "NOT_TESTED_DTC" ;
VAL_ 861 IBST_d160_assertionFail 3 "UNABLE_TO_TEST_DTC" 2 "FAILED_DTC" 1 "PASSED_DTC" 0 "NOT_TESTED_DTC" ;
VAL_ 861 IBST_d161_comsclBrkPrsPduLen 3 "UNABLE_TO_TEST_DTC" 2 "FAILED_DTC" 1 "PASSED_DTC" 0 "NOT_TESTED_DTC" ;
VAL_ 861 IBST_d162_comsclBrkPrsPduTout 3 "UNABLE_TO_TEST_DTC" 2 "FAILED_DTC" 1 "PASSED_DTC" 0 "NOT_TESTED_DTC" ;
VAL_ 861 IBST_d163_comsclEspIb1CntErr 3 "UNABLE_TO_TEST_DTC" 2 "FAILED_DTC" 1 "PASSED_DTC" 0 "NOT_TESTED_DTC" ;
VAL_ 861 IBST_d164_comsclEspIb1CsErr 3 "UNABLE_TO_TEST_DTC" 2 "FAILED_DTC" 1 "PASSED_DTC" 0 "NOT_TESTED_DTC" ;
VAL_ 861 IBST_d165_comsclEspIb1DlcErr 3 "UNABLE_TO_TEST_DTC" 2 "FAILED_DTC" 1 "PASSED_DTC" 0 "NOT_TESTED_DTC" ;
VAL_ 861 IBST_d166_comsclEspIb1Tout 3 "UNABLE_TO_TEST_DTC" 2 "FAILED_DTC" 1 "PASSED_DTC" 0 "NOT_TESTED_DTC" ;
VAL_ 861 IBST_d167_comsclEspIb2CntErr 3 "UNABLE_TO_TEST_DTC" 2 "FAILED_DTC" 1 "PASSED_DTC" 0 "NOT_TESTED_DTC" ;
VAL_ 861 IBST_d168_comsclEspIb2CsErr 3 "UNABLE_TO_TEST_DTC" 2 "FAILED_DTC" 1 "PASSED_DTC" 0 "NOT_TESTED_DTC" ;
VAL_ 861 IBST_d169_comsclEspIb2DlcErr 3 "UNABLE_TO_TEST_DTC" 2 "FAILED_DTC" 1 "PASSED_DTC" 0 "NOT_TESTED_DTC" ;
VAL_ 861 IBST_d170_comsclEspIb2Tout 3 "UNABLE_TO_TEST_DTC" 2 "FAILED_DTC" 1 "PASSED_DTC" 0 "NOT_TESTED_DTC" ;
VAL_ 861 IBST_d171_comsclEspIb3CntErr 3 "UNABLE_TO_TEST_DTC" 2 "FAILED_DTC" 1 "PASSED_DTC" 0 "NOT_TESTED_DTC" ;
VAL_ 861 IBST_d172_comsclEspIb3CsErr 3 "UNABLE_TO_TEST_DTC" 2 "FAILED_DTC" 1 "PASSED_DTC" 0 "NOT_TESTED_DTC" ;
VAL_ 861 IBST_d173_comsclEspIb3DlcErr 3 "UNABLE_TO_TEST_DTC" 2 "FAILED_DTC" 1 "PASSED_DTC" 0 "NOT_TESTED_DTC" ;
VAL_ 861 IBST_d174_comsclEspIb3Tout 3 "UNABLE_TO_TEST_DTC" 2 "FAILED_DTC" 1 "PASSED_DTC" 0 "NOT_TESTED_DTC" ;
VAL_ 861 IBST_d175_comsclGtwEsp1CntErr 3 "UNABLE_TO_TEST_DTC" 2 "FAILED_DTC" 1 "PASSED_DTC" 0 "NOT_TESTED_DTC" ;
VAL_ 861 IBST_d176_comsclGtwEsp1CsErr 3 "UNABLE_TO_TEST_DTC" 2 "FAILED_DTC" 1 "PASSED_DTC" 0 "NOT_TESTED_DTC" ;
VAL_ 861 IBST_d177_comsclGtwEsp1Corrpt 3 "UNABLE_TO_TEST_DTC" 2 "FAILED_DTC" 1 "PASSED_DTC" 0 "NOT_TESTED_DTC" ;
VAL_ 861 IBST_d178_comsclGtwEsp1Tout 3 "UNABLE_TO_TEST_DTC" 2 "FAILED_DTC" 1 "PASSED_DTC" 0 "NOT_TESTED_DTC" ;
VAL_ 861 IBST_d179_dcomSmrtActuNotInit 3 "UNABLE_TO_TEST_DTC" 2 "FAILED_DTC" 1 "PASSED_DTC" 0 "NOT_TESTED_DTC" ;
VAL_ 861 IBST_d180_rpsLengthAbsolHigh 3 "UNABLE_TO_TEST_DTC" 2 "FAILED_DTC" 1 "PASSED_DTC" 0 "NOT_TESTED_DTC" ;
VAL_ 861 IBST_d181_rpsLengthAbsolLow 3 "UNABLE_TO_TEST_DTC" 2 "FAILED_DTC" 1 "PASSED_DTC" 0 "NOT_TESTED_DTC" ;
VAL_ 861 IBST_d182_shutDownEeReadFail 3 "UNABLE_TO_TEST_DTC" 2 "FAILED_DTC" 1 "PASSED_DTC" 0 "NOT_TESTED_DTC" ;
VAL_ 861 IBST_d183_shutDownEeWriteFail 3 "UNABLE_TO_TEST_DTC" 2 "FAILED_DTC" 1 "PASSED_DTC" 0 "NOT_TESTED_DTC" ;
VAL_ 861 IBST_d184_maxTrvlAdjstReadErr 3 "UNABLE_TO_TEST_DTC" 2 "FAILED_DTC" 1 "PASSED_DTC" 0 "NOT_TESTED_DTC" ;
VAL_ 861 IBST_d185_psOffsMcEeReadFail 3 "UNABLE_TO_TEST_DTC" 2 "FAILED_DTC" 1 "PASSED_DTC" 0 "NOT_TESTED_DTC" ;
VAL_ 861 IBST_d186_psOffsMcEeWriteFail 3 "UNABLE_TO_TEST_DTC" 2 "FAILED_DTC" 1 "PASSED_DTC" 0 "NOT_TESTED_DTC" ;
VAL_ 861 IBST_d187_ltmSelfProtDeact 3 "UNABLE_TO_TEST_DTC" 2 "FAILED_DTC" 1 "PASSED_DTC" 0 "NOT_TESTED_DTC" ;
VAL_ 861 IBST_d188_pts1OffsEeReadFail 3 "UNABLE_TO_TEST_DTC" 2 "FAILED_DTC" 1 "PASSED_DTC" 0 "NOT_TESTED_DTC" ;
VAL_ 861 IBST_d189_diffStrokeRange 3 "UNABLE_TO_TEST_DTC" 2 "FAILED_DTC" 1 "PASSED_DTC" 0 "NOT_TESTED_DTC" ;
VAL_ 861 IBST_d190_notProgVin 3 "UNABLE_TO_TEST_DTC" 2 "FAILED_DTC" 1 "PASSED_DTC" 0 "NOT_TESTED_DTC" ;
VAL_ 861 IBST_d191_plausVin 3 "UNABLE_TO_TEST_DTC" 2 "FAILED_DTC" 1 "PASSED_DTC" 0 "NOT_TESTED_DTC" ;
VAL_ 861 IBST_d192_dlCorCSumVin 3 "UNABLE_TO_TEST_DTC" 2 "FAILED_DTC" 1 "PASSED_DTC" 0 "NOT_TESTED_DTC" ;
VAL_ 861 IBST_d193_ToutVin 3 "UNABLE_TO_TEST_DTC" 2 "FAILED_DTC" 1 "PASSED_DTC" 0 "NOT_TESTED_DTC" ;
VAL_ 861 IBST_d194_ecuEnableB6Fail 3 "UNABLE_TO_TEST_DTC" 2 "FAILED_DTC" 1 "PASSED_DTC" 0 "NOT_TESTED_DTC" ;
VAL_ 861 IBST_d195_ecuIbEnContErr 3 "UNABLE_TO_TEST_DTC" 2 "FAILED_DTC" 1 "PASSED_DTC" 0 "NOT_TESTED_DTC" ;
VAL_ 861 IBST_d196_sclEspIb1pEstMax 3 "UNABLE_TO_TEST_DTC" 2 "FAILED_DTC" 1 "PASSED_DTC" 0 "NOT_TESTED_DTC" ;
VAL_ 861 IBST_d197_sclEspIb1VehSpd 3 "UNABLE_TO_TEST_DTC" 2 "FAILED_DTC" 1 "PASSED_DTC" 0 "NOT_TESTED_DTC" ;
VAL_ 861 IBST_d198_sclEspIb2pLimExt 3 "UNABLE_TO_TEST_DTC" 2 "FAILED_DTC" 1 "PASSED_DTC" 0 "NOT_TESTED_DTC" ;
VAL_ 861 IBST_d199_sclEspIb2qTarExt 3 "UNABLE_TO_TEST_DTC" 2 "FAILED_DTC" 1 "PASSED_DTC" 0 "NOT_TESTED_DTC" ;
VAL_ 861 IBST_d200_sclEspIb3pFBlend 3 "UNABLE_TO_TEST_DTC" 2 "FAILED_DTC" 1 "PASSED_DTC" 0 "NOT_TESTED_DTC" ;
VAL_ 861 IBST_d201_sclEspIb3pMc1 3 "UNABLE_TO_TEST_DTC" 2 "FAILED_DTC" 1 "PASSED_DTC" 0 "NOT_TESTED_DTC" ;
VAL_ 861 IBST_d202_sclEspIb3pTarDriver 3 "UNABLE_TO_TEST_DTC" 2 "FAILED_DTC" 1 "PASSED_DTC" 0 "NOT_TESTED_DTC" ;
VAL_ 861 IBST_d203_netBusOffNet0 3 "UNABLE_TO_TEST_DTC" 2 "FAILED_DTC" 1 "PASSED_DTC" 0 "NOT_TESTED_DTC" ;
VAL_ 861 IBST_d204_netErrPassivNet0 3 "UNABLE_TO_TEST_DTC" 2 "FAILED_DTC" 1 "PASSED_DTC" 0 "NOT_TESTED_DTC" ;
VAL_ 861 IBST_d205_netBusOffNet1 3 "UNABLE_TO_TEST_DTC" 2 "FAILED_DTC" 1 "PASSED_DTC" 0 "NOT_TESTED_DTC" ;
VAL_ 861 IBST_d206_netErrPassivNet1 3 "UNABLE_TO_TEST_DTC" 2 "FAILED_DTC" 1 "PASSED_DTC" 0 "NOT_TESTED_DTC" ;
VAL_ 861 IBST_d207_maxStrokeReached 3 "UNABLE_TO_TEST_DTC" 2 "FAILED_DTC" 1 "PASSED_DTC" 0 "NOT_TESTED_DTC" ;
VAL_ 861 IBST_d208_sysSwClockMismatch 3 "UNABLE_TO_TEST_DTC" 2 "FAILED_DTC" 1 "PASSED_DTC" 0 "NOT_TESTED_DTC" ;
VAL_ 861 IBST_d209_comsclGtwOdoCorrpt 3 "UNABLE_TO_TEST_DTC" 2 "FAILED_DTC" 1 "PASSED_DTC" 0 "NOT_TESTED_DTC" ;
VAL_ 861 IBST_d210_comsclGtwStatCorrpt 3 "UNABLE_TO_TEST_DTC" 2 "FAILED_DTC" 1 "PASSED_DTC" 0 "NOT_TESTED_DTC" ;
VAL_ 861 IBST_d211_comsclEpbStatCorrpt 3 "UNABLE_TO_TEST_DTC" 2 "FAILED_DTC" 1 "PASSED_DTC" 0 "NOT_TESTED_DTC" ;
VAL_ 861 IBST_d212_comsclGtwOdoTout 3 "UNABLE_TO_TEST_DTC" 2 "FAILED_DTC" 1 "PASSED_DTC" 0 "NOT_TESTED_DTC" ;
VAL_ 861 IBST_d213_comsclGtwStatTout 3 "UNABLE_TO_TEST_DTC" 2 "FAILED_DTC" 1 "PASSED_DTC" 0 "NOT_TESTED_DTC" ;
VAL_ 861 IBST_d214_comsclEpbStatTout 3 "UNABLE_TO_TEST_DTC" 2 "FAILED_DTC" 1 "PASSED_DTC" 0 "NOT_TESTED_DTC" ;
VAL_ 861 IBST_d215_comSclEpbStatCsErr 3 "UNABLE_TO_TEST_DTC" 2 "FAILED_DTC" 1 "PASSED_DTC" 0 "NOT_TESTED_DTC" ;
VAL_ 861 IBST_d216_comSclEpbStatCntFlt 3 "UNABLE_TO_TEST_DTC" 2 "FAILED_DTC" 1 "PASSED_DTC" 0 "NOT_TESTED_DTC" ;
VAL_ 861 IBST_d217_comSclDiTrq1Tout 3 "UNABLE_TO_TEST_DTC" 2 "FAILED_DTC" 1 "PASSED_DTC" 0 "NOT_TESTED_DTC" ;
VAL_ 861 IBST_d218_comSclDiTrq1Corrpt 3 "UNABLE_TO_TEST_DTC" 2 "FAILED_DTC" 1 "PASSED_DTC" 0 "NOT_TESTED_DTC" ;
VAL_ 861 IBST_d219_comSclDiTrq1CsErr 3 "UNABLE_TO_TEST_DTC" 2 "FAILED_DTC" 1 "PASSED_DTC" 0 "NOT_TESTED_DTC" ;
VAL_ 861 IBST_d220_comSclDiTrq1CntFlt 3 "UNABLE_TO_TEST_DTC" 2 "FAILED_DTC" 1 "PASSED_DTC" 0 "NOT_TESTED_DTC" ;
VAL_ 541 IBST_ebrMode 5 "FULL_SYSTEM" 4 "FAILED_OPERATIONAL" 3 "FAILED_DEGRADED" 2 "EMERGENCY_MODE" 1 "UNABLE_TO_EXECUTE" 0 "FAULTED" ;
VAL_ 541 IBST_ebrSystemMode 5 "FULL_SYSTEM" 4 "FAILED_OPERATIONAL" 3 "FAILED_DEGRADED" 2 "EMERGENCY_MODE" 1 "UNABLE_TO_EXECUTE" 0 "FAULTED" ;
VAL_ 541 IBST_brakeTorqueTarget 8191 "SNA" ;
VAL_ 541 IBST_ebrSource 1 "DAS_EBR" 0 "DI_EBR" ;
VAL_ 541 IBST_ebrState 2 "EBR_RELEASING_FOR_SKID" 1 "ACTIVE" 0 "INACTIVE" ;
VAL_ 813 IBST_infoIndex 255 "INFO_END" 22 "INFO_VARIANT_CRC" 20 "INFO_UDS_PROTOCOL_BOOTCRC" 19 "INFO_VERSION_DEPRECATED" 18 "INFO_BOOTLOADER_GITHASH" 17 "INFO_APP_GITHASH" 16 "INFO_SUBCOMPONENT" 15 "INFO_BOOTLOADER_CRC" 14 "INFO_BOOTLOADER_SVN" 13 "INFO_APP_CRC" 11 "INFO_PCBAID_ASSYID_USAGEID" 10 "INFO_BUILD_HWID_COMPONENTID" 9 "INFO_DEPRECATED_9" 8 "INFO_DEPRECATED_8" 7 "INFO_DEPRECATED_7" 6 "INFO_DEPRECATED_6" 5 "INFO_DEPRECATED_5" 4 "INFO_DEPRECATED_4" 3 "INFO_DEPRECATED_3" 2 "INFO_DEPRECATED_2" 1 "INFO_DEPRECATED_1" 0 "INFO_DEPRECATED_0" ;
VAL_ 925 IBST_iBoosterStatus 7 "IBOOSTER_READY" 6 "IBOOSTER_POST_RUN_REDUCED" 5 "IBOOSTER_REDUCED" 4 "IBOOSTER_STANDALONE" 3 "IBOOSTER_MAX_STROKE" 2 "IBOOSTER_DIAGNOSIS" 1 "IBOOSTER_FAILURE" 0 "IBOOSTER_NOT_INITIALIZED_OR_SUP" ;
VAL_ 925 IBST_brakeInputStroke 1023 "INPUT_STROKE_SNA" 1022 "INPUT_STROKE_NOT_VALID" ;
VAL_ 1804 IC_10Hz_state 3 "IC_STATE_SOFTWARE_FAULT" 2 "IC_STATE_IDLE" 1 "IC_STATE_CLEAR_TEGRA_RESET" 0 "IC_STATE_WAIT_FOR_TEGRA_PWRGOOD" ;
VAL_ 1804 IC_10Hz_last_state 3 "IC_STATE_SOFTWARE_FAULT" 2 "IC_STATE_IDLE" 1 "IC_STATE_CLEAR_TEGRA_RESET" 0 "IC_STATE_WAIT_FOR_TEGRA_PWRGOOD" ;
VAL_ 1420 IC_alertID 16 "IC_a016_unused" 15 "IC_a015_unused" 14 "IC_a014_unused" 13 "IC_a013_OVERTEMP_OFF" 12 "IC_a012_CAN_TX_ERRCNT" 11 "IC_a011_CAN_RX_ERRCNT" 10 "IC_a010_SPI_READ" 9 "IC_a009_SPI_OPEN" 8 "IC_a008_MEMORY_ERROR" 7 "IC_a007_WATCHDOG_RESET" 6 "IC_a006_FPGA_ERROR" 5 "IC_a005_FIRMWARE" 4 "IC_a004_CAN_OVERRUN" 3 "IC_a003_CAN_ERR" 2 "IC_a002_CAN_TX" 1 "IC_a001_CAN_RX" 0 "IC_DO_NOT_USE" ;
VAL_ 1420 IC_alertType 3 "ALERT_DTC" 2 "ALERT_FAULT" 1 "ALERT_USER" 0 "ALERT_WARNING" ;
VAL_ 1420 IC_canErrorType 9 "CAN_ERROR_TWO_SLAVES" 8 "CAN_ERROR_TWO_MASTERS" 7 "CAN_ERROR_RESET_CMD" 6 "CAN_ERROR_OVERRUN" 5 "CAN_ERROR_TX" 4 "CAN_ERROR_RX" 3 "CAN_ERROR_NODEBUG" 2 "CAN_ERROR_DATA" 1 "CAN_ERROR_CHECKSUM" 0 "CAN_ERROR_LENGTH" ;
VAL_ 812 IC_infoIndex 255 "INFO_END" 20 "INFO_UDS_PROTOCOL_BOOTCRC" 19 "INFO_VERSION_DEPRECATED" 18 "INFO_BOOTLOADER_GITHASH" 17 "INFO_APP_GITHASH" 16 "INFO_SUBCOMPONENT" 15 "INFO_BOOTLOADER_CRC" 14 "INFO_BOOTLOADER_SVN" 13 "INFO_APP_CRC" 11 "INFO_PCBAID_ASSYID_USAGEID" 10 "INFO_BUILD_HWID_COMPONENTID" 9 "INFO_DEPRECATED_9" 8 "INFO_DEPRECATED_8" 7 "INFO_DEPRECATED_7" 6 "INFO_DEPRECATED_6" 5 "INFO_DEPRECATED_5" 4 "INFO_DEPRECATED_4" 3 "INFO_DEPRECATED_3" 2 "INFO_DEPRECATED_2" 1 "INFO_DEPRECATED_1" 0 "INFO_DEPRECATED_0" ;
VAL_ 812 IC_FPGA_version 255 "SNA" 254 "LOCAL_BUILD" ;
VAL_ 524 IC_LEDBrightnessClass 3 "LED_RANK_PA9" 2 "LED_RANK_PA8" 1 "LED_RANK_PA7" 0 "UNKNOWN" ;
VAL_ 1436 IC_componentHardwareRevision 252 "CONFIGURABLE_HWID_PLACEHOLDER" ;
VAL_ 757 TxDrvPosn_Disp_Rq_ISM 255 "SNA" 82 "R" 80 "P" 78 "N" 70 "F" 68 "D" 65 "A" 55 "D7" 54 "D6" 53 "D5" 52 "D4" 51 "D3" 50 "D2" 49 "D1" 32 "BLANK" 7 "M7" 6 "M6" 5 "M5" 4 "M4" 3 "M3" 2 "M2" 1 "M1" ;
VAL_ 757 SBW_Msg_Disp_Rq_ISM 7 "NDEF7" 6 "M6" 5 "M5" 4 "M4" 3 "M3" 2 "M2" 1 "M1" 0 "IDLE" ;
VAL_ 757 TSL_MtnLk1_Disp_Rq_ISM 12 "ARR_UP_DN_HLGT" 11 "ARR_LT_HLGT" 10 "ARR_DN_HLGT" 9 "ARR_UP_HLGT" 4 "ARR_UP_DN" 3 "ARR_LT" 2 "ARR_DN" 1 "ARR_UP" 0 "IDLE" ;
VAL_ 757 TSL_MtnLk2_Disp_Rq_ISM 12 "ARR_UP_DN_HLGT" 11 "ARR_LT_HLGT" 10 "ARR_DN_HLGT" 9 "ARR_UP_HLGT" 4 "ARR_UP_DN" 3 "ARR_LT" 2 "ARR_DN" 1 "ARR_UP" 0 "IDLE" ;
VAL_ 757 TSL_MtnLk3_Disp_Rq_ISM 12 "ARR_UP_DN_HLGT" 11 "ARR_LT_HLGT" 10 "ARR_DN_HLGT" 9 "ARR_UP_HLGT" 4 "ARR_UP_DN" 3 "ARR_LT" 2 "ARR_DN" 1 "ARR_UP" 0 "IDLE" ;
VAL_ 757 TSL_MtnLk4_Disp_Rq_ISM 12 "ARR_UP_DN_HLGT" 11 "ARR_LT_HLGT" 10 "ARR_DN_HLGT" 9 "ARR_UP_HLGT" 4 "ARR_UP_DN" 3 "ARR_LT" 2 "ARR_DN" 1 "ARR_UP" 0 "IDLE" ;
VAL_ 1025 LRR_lowPowerMode 3 "SNA" 2 "NORMAL_POWER" 1 "COMMANDED_LOW_POWER" 0 "DEFAULT_LOW_POWER" ;
VAL_ 415 VehSpd_Disp 2047 "SNA" ;
VAL_ 415 Vprzr_DryVnTmr_Stat 3 "SNA" 2 "EXPIRED" 1 "ACTV" 0 "INACTV" ;
VAL_ 415 AirTemp_Outsd_Disp 255 "SNA" ;
VAL_ 415 EngShutOffTm 4095 "SNA" ;
VAL_ 415 HiBm_Enbl 3 "SNA" 2 "NDEF2" 1 "ENBL" 0 "DSABL" ;
VAL_ 415 PTS_Disp_Stat_IC 3 "SNA" 2 "FATAL" 1 "TIMEOUT" 0 "OK" ;
VAL_ 415 ODO 16777215 "SNA" 16777214 "Init" ;
VAL_ 536 MCU_parkBrakeRequest 1 "PRESSED" 0 "IDLE" ;
VAL_ 536 MCU_trailerModeCH 1 "TRAILER_MODE_ON" 0 "TRAILER_MODE_OFF" ;
VAL_ 536 MCU_fcwSensitivity 3 "SNA" 2 "AEB_SENSITIVITY_LATE" 1 "AEB_SENSITIVITY_AVERAGE" 0 "AEB_SENSITIVITY_EARLY" ;
VAL_ 536 MCU_fcwEnable 1 "FCW_ON" 0 "FCW_OFF" ;
VAL_ 536 MCU_latControlEnable 3 "LATERAL_CONTROL_SNA" 2 "LATERAL_CONTROL_UNAVAILABLE" 1 "LATERAL_CONTROL_ON" 0 "LATERAL_CONTROL_OFF" ;
VAL_ 536 MCU_accOvertakeEnable 3 "SNA" 1 "ACC_OVERTAKE_ON" 0 "ACC_OVERTAKE_OFF" ;
VAL_ 536 MCU_ldwEnable 3 "SNA" 1 "LDW_TRIGGERS_HAPTIC" 0 "NO_HAPTIC" ;
VAL_ 536 MCU_aebEnable 3 "SNA" 1 "AEB_ON" 0 "AEB_OFF" ;
VAL_ 536 MCU_bsdEnable 3 "SNA" 1 "BSD_ON" 0 "BSD_OFF" ;
VAL_ 536 MCU_ahlbEnable 3 "SNA" 1 "AHLB_ON" 0 "AHLB_OFF" ;
VAL_ 536 MCU_parkSetting 3 "SNA" 2 "UNUSED" 1 "PARK_ASSIST_ON" 0 "PARK_ASSIST_OFF" ;
VAL_ 536 MCU_pedalSafetyEnable 3 "SNA" 1 "PEDAL_SAFETY_ON" 0 "PEDAL_SAFETY_OFF" ;
VAL_ 536 MCU_frontDefrostReq_das 3 "SNA" 1 "ON" 0 "OFF" ;
VAL_ 536 MCU_autoParkRequest 15 "SNA" 11 "RESUME" 10 "PAUSE" 9 "SEARCH" 8 "COMPLETE" 7 "ABORT" 6 "PARALLEL_PULL_OUT_TO_RIGHT" 5 "PARALLEL_PULL_OUT_TO_LEFT" 4 "PARK_RIGHT_CROSS" 3 "PARK_RIGHT_PARALLEL" 2 "PARK_LEFT_CROSS" 1 "PARK_LEFT_PARALLEL" 0 "NONE" ;
VAL_ 536 MCU_redLightStopSignEnable 3 "SNA" 1 "RLSSW_ON" 0 "RLSSW_OFF" ;
VAL_ 536 MCU_enableCreepTorqueCH 1 "CREEP_MODE_ON" 0 "CREEP_MODE_OFF" ;
VAL_ 536 MCU_overPaintedUSS 3 "SNA" 2 "UNUSED" 1 "OVER_PAINTED" 0 "NOMINAL" ;
VAL_ 536 MCU_selfParkTune 15 "SNA" ;
VAL_ 536 MCU_towModeEnable 3 "SNA" 2 "DISABLE" 1 "ENABLE" 0 "IDLE" ;
VAL_ 536 MCU_zeroSpeedConfirmed 3 "SNA" 2 "UNUSED" 1 "CONFIRMED" 0 "CANCELED" ;
VAL_ 536 MCU_aesEnable 3 "SNA" 1 "AES_ON" 0 "AES_OFF" ;
VAL_ 536 MCU_autoLaneChangeEnable 3 "SNA" 1 "ON" 0 "OFF" ;
VAL_ 904 MCU_clusterReadyForDrive 1 "YES" 0 "NO_SNA" ;
VAL_ 2043 MCU_debugTasTarget 2 "REARAXLE" 1 "FRONTAXLE" 0 "FLAGS" ;
VAL_ 952 MCU_setRcpFront 255 "SNA" ;
VAL_ 952 MCU_setRcpRear 255 "SNA" ;
VAL_ 1028 NM_Mode 255 "SNA" 254 "ALIVE" 253 "RING" 252 "LHOM" ;
VAL_ 1028 NM_Successor 255 "SNA" ;
VAL_ 1028 NM_Ud_Launch 63 "SNA" 4 "BROADCAST" ;
VAL_ 1028 NM_Ud_Srv 255 "SNA" 15 "AWAKE_BC" 5 "SBC_STAT_BC" 2 "WAKEUP_SA" 1 "DATA_OK_BC" ;
VAL_ 1028 Nw_Id 255 "SNA" 50 "CHASSIS2" 49 "CHASSIS1" 42 "HYBRID" 16 "MULTIPURPOSE" 15 "IMPACT" 14 "HEADUNIT" 11 "DYNAMICS" 9 "PT_SENSOR" 8 "POWERTRAIN" 7 "CHASSIS" 6 "BODY" 5 "DIAGNOSTICS" 4 "BACKBONE" ;
VAL_ 1028 WakeupRsn_SCCM 255 "SNA" 73 "STW_SW" 72 "TX_LVR_P" 71 "STW_LVR" 0 "NETWORK" ;
VAL_ 1026 P_NM_Mode 255 "SNA" 254 "ALIVE" 253 "RING" 252 "LHOM" ;
VAL_ 1026 P_NM_Successor 255 "SNA" ;
VAL_ 1026 P_NM_Ud_Launch 63 "SNA" 4 "BROADCAST" ;
VAL_ 1026 P_NM_Ud_Srv 255 "SNA" 15 "AWAKE_BC" 5 "SBC_STAT_BC" 2 "WAKEUP_SA" 1 "DATA_OK_BC" ;
VAL_ 1026 P_Nw_Id 255 "SNA" 50 "CHASSIS2" 49 "CHASSIS1" 42 "HYBRID" 16 "MULTIPURPOSE" 15 "IMPACT" 14 "HEADUNIT" 11 "DYNAMICS" 9 "PT_SENSOR" 8 "POWERTRAIN" 7 "CHASSIS" 6 "BODY" 5 "DIAGNOSTICS" 4 "BACKBONE" ;
VAL_ 1026 P_WakeupRsn_SCCM 255 "SNA" 73 "STW_SW" 72 "TX_LVR_P" 71 "STW_LVR" 0 "NETWORK" ;
VAL_ 771 OCS_occupantClassification 7 "FAULTED" 6 "INVALID2" 5 "INVALID1" 4 "OCCUPIED_ALLOW_LARGE" 3 "OCCUPIED_ALLOW_SMALL" 2 "OCCUPIED INHIBIT" 1 "EMPTY" 0 "UNKNOWN" ;
VAL_ 771 OCS_calibrationID 2 "MODEL_X" 1 "MODEL_S" ;
VAL_ 1485 PARK3_alertID 8215 "PARK3_u023_s12_crossTalk" 8214 "PARK3_u022_s11_crossTalk" 8213 "PARK3_u021_s10_crossTalk" 8212 "PARK3_u020_s9_crossTalk" 8211 "PARK3_u019_s8_crossTalk" 8210 "PARK3_u018_s7_crossTalk" 8209 "PARK3_u017_s6_crossTalk" 8208 "PARK3_u016_s5_crossTalk" 8207 "PARK3_u015_s4_crossTalk" 8206 "PARK3_u014_s3_crossTalk" 8205 "PARK3_u013_s2_crossTalk" 8204 "PARK3_u012_s1_crossTalk" 8203 "PARK3_u011_s12_blocked" 8202 "PARK3_u010_s11_blocked" 8201 "PARK3_u009_s10_blocked" 8200 "PARK3_u008_s9_blocked" 8199 "PARK3_u007_s8_blocked" 8198 "PARK3_u006_s7_blocked" 8197 "PARK3_u005_s6_blocked" 8196 "PARK3_u004_s5_blocked" 8195 "PARK3_u003_s4_blocked" 8194 "PARK3_u002_s3_blocked" 8193 "PARK3_u001_s2_blocked" 8192 "PARK3_u000_s1_blocked" 60 "PARK3_w060_nvmFault" 59 "PARK3_w059_sccmErr" 58 "PARK3_w058_mcuErr" 57 "PARK3_w057_gtwErr" 56 "PARK3_w056_espErr" 55 "PARK3_w055_epbErr" 54 "PARK3_w054_epasErr" 53 "PARK3_w053_diErr" 52 "PARK3_w052_dasErr" 51 "PARK3_w051_sccmMia" 50 "PARK3_w050_mcuMia" 49 "PARK3_w049_gtwMia" 48 "PARK3_w048_espMia" 47 "PARK3_w047_epbMia" 46 "PARK3_w046_epasMia" 45 "PARK3_w045_diMia" 44 "PARK3_w044_dasMia" 43 "PARK3_w043_hwWatchDog" 42 "PARK3_w042_CAN2busOff" 41 "PARK3_w041_calibrationMissing" 40 "PARK3_w040_crcFailure" 39 "PARK3_w039_ecuFault" 38 "PARK3_w038_sensorVoltage" 37 "PARK3_w037_ecuOverVoltage" 36 "PARK3_w036_ecuUnderVoltage" 35 "PARK3_w035_s12_linCommError" 34 "PARK3_w034_s12_internalFail" 33 "PARK3_w033_s12_overTemp" 32 "PARK3_w032_s11_linCommError" 31 "PARK3_w031_s11_internalFail" 30 "PARK3_w030_s11_overTemp" 29 "PARK3_w029_s10_linCommError" 28 "PARK3_w028_s10_internalFail" 27 "PARK3_w027_s10_overTemp" 26 "PARK3_w026_s9_linCommError" 25 "PARK3_w025_s9_internalFail" 24 "PARK3_w024_s9_overTemp" 23 "PARK3_w023_s8_linCommError" 22 "PARK3_w022_s8_internalFail" 21 "PARK3_w021_s8_overTemp" 20 "PARK3_w020_s7_linCommError" 19 "PARK3_w019_s7_internalFail" 18 "PARK3_w018_s7_overTemp" 17 "PARK3_w017_s6_linCommError" 16 "PARK3_w016_s6_internalFail" 15 "PARK3_w015_s6_overTemp" 14 "PARK3_w014_s5_linCommError" 13 "PARK3_w013_s5_internalFail" 12 "PARK3_w012_s5_overTemp" 11 "PARK3_w011_s4_linCommError" 10 "PARK3_w010_s4_internalFail" 9 "PARK3_w009_s4_overTemp" 8 "PARK3_w008_s3_linCommError" 7 "PARK3_w007_s3_internalFail" 6 "PARK3_w006_s3_overTemp" 5 "PARK3_w005_s2_linCommError" 4 "PARK3_w004_s2_internalFail" 3 "PARK3_w003_s2_overTemp" 2 "PARK3_w002_s1_linCommError" 1 "PARK3_w001_s1_internalFail" 0 "PARK3_w000_s1_overTemp" ;
VAL_ 1485 PARK3_alertType 1 "PARK3_ALERT_USER" 0 "PARK3_WARNING" ;
VAL_ 1485 PARK3_sw052_dasErrorType 5 "OVERRUN" 4 "INVALID_DATA" 3 "SEQUENCE" 2 "CHECKSUM" 1 "LENGTH" 0 "NONE" ;
VAL_ 1485 PARK3_sw053_diErrorType 5 "OVERRUN" 4 "INVALID_DATA" 3 "SEQUENCE" 2 "CHECKSUM" 1 "LENGTH" 0 "NONE" ;
VAL_ 1485 PARK3_sw054_epasErrorExp 2046 "EPAS_steeringRackForce" 2045 "EPAS_steeringFault" 2043 "EPAS_steeringReduced" 2039 "EPAS_currentTuneMode" 2031 "EPAS_torsionBarTorque" 2015 "EPAS_eacErrorCode" 1983 "EPAS_internalSAS" 1919 "EPAS_handsOnLevel" 1791 "EPAS_sysStatusCounter" 1535 "EPAS_eacStatus" 1023 "EPAS_sysStatusChecksum" ;
VAL_ 1485 PARK3_sw054_epasErrorType 5 "OVERRUN" 4 "INVALID_DATA" 3 "SEQUENCE" 2 "CHECKSUM" 1 "LENGTH" 0 "NONE" ;
VAL_ 1485 PARK3_sw055_epbErrorType 5 "OVERRUN" 4 "INVALID_DATA" 3 "SEQUENCE" 2 "CHECKSUM" 1 "LENGTH" 0 "NONE" ;
VAL_ 1485 PARK3_sw056_espErrorType 5 "OVERRUN" 4 "INVALID_DATA" 3 "SEQUENCE" 2 "CHECKSUM" 1 "LENGTH" 0 "NONE" ;
VAL_ 1485 PARK3_sw057_gtwErrorType 5 "OVERRUN" 4 "INVALID_DATA" 3 "SEQUENCE" 2 "CHECKSUM" 1 "LENGTH" 0 "NONE" ;
VAL_ 1485 PARK3_sw058_mcuErrorType 5 "OVERRUN" 4 "INVALID_DATA" 3 "SEQUENCE" 2 "CHECKSUM" 1 "LENGTH" 0 "NONE" ;
VAL_ 1485 PARK3_sw059_sccmErrorType 5 "OVERRUN" 4 "INVALID_DATA" 3 "SEQUENCE" 2 "CHECKSUM" 1 "LENGTH" 0 "NONE" ;
VAL_ 1486 PARK_alertID 64 "PARK_w064_flashDebug" 63 "PARK_w063_S12_sensorState" 62 "PARK_w062_S11_sensorState" 61 "PARK_w061_S10_sensorState" 60 "PARK_w060_S9_sensorState" 59 "PARK_w059_S8_sensorState" 58 "PARK_w058_S7_sensorState" 57 "PARK_w057_S6_sensorState" 56 "PARK_w056_S5_sensorState" 55 "PARK_w055_S4_sensorState" 54 "PARK_w054_S3_sensorState" 53 "PARK_w053_S2_sensorState" 52 "PARK_w052_S1_sensorState" 51 "PARK_w051_sccmErr" 50 "PARK_w050_espErr" 49 "PARK_w049_epbErr" 48 "PARK_w048_epasErr" 47 "PARK_w047_dasErr" 46 "PARK_w046_sccmMIA" 45 "PARK_w045_espMIA" 44 "PARK_w044_epbMIA" 43 "PARK_w043_epasMIA" 42 "PARK_w042_dasMIA" 41 "PARK_w041_ECUSupplyHigh" 40 "PARK_w040_ECUSupplyLow" 39 "PARK_w039_hardwareError" 38 "PARK_w038_sensorSupplyHigh" 37 "PARK_w037_sensorSupplyLow" 36 "PARK_w036_S12_ringTooLong" 35 "PARK_w035_S12_shortBattery" 34 "PARK_w034_S12_shortGround" 33 "PARK_w033_S11_ringTooLong" 32 "PARK_w032_S11_shortBattery" 31 "PARK_w031_S11_shortGround" 30 "PARK_w030_S10_ringTooLong" 29 "PARK_w029_S10_shortBattery" 28 "PARK_w028_S10_shortGround" 27 "PARK_w027_S9_ringTooLong" 26 "PARK_w026_S9_shortBattery" 25 "PARK_w025_S9_shortGround" 24 "PARK_w024_S8_ringTooLong" 23 "PARK_w023_S8_shortBattery" 22 "PARK_w022_S8_shortGround" 21 "PARK_w021_S7_ringTooLong" 20 "PARK_w020_S7_shortBattery" 19 "PARK_w019_S7_shortGround" 18 "PARK_w018_S6_ringTooLong" 17 "PARK_w017_S6_shortBattery" 16 "PARK_w016_S6_shortGround" 15 "PARK_w015_S5_ringTooLong" 14 "PARK_w014_S5_shortBattery" 13 "PARK_w013_S5_shortGround" 12 "PARK_w012_S4_ringTooLong" 11 "PARK_w011_S4_shortBattery" 10 "PARK_w010_S4_shortGround" 9 "PARK_w009_S3_ringTooLong" 8 "PARK_w008_S3_shortBattery" 7 "PARK_w007_S3_shortGround" 6 "PARK_w006_S2_ringTooLong" 5 "PARK_w005_S2_shortBattery" 4 "PARK_w004_S2_shortGround" 3 "PARK_w003_S1_ringTooLong" 2 "PARK_w002_S1_shortBattery" 1 "PARK_w001_S1_shortGround" ;
VAL_ 1486 PARK_sw000_S1_ussDisturbance 1 "DISTURBANCE_PRESENT" 0 "DISTURBANCE_NOT_PRESENT" ;
VAL_ 1486 PARK_sw000_S2_ussDisturbance 1 "DISTURBANCE_PRESENT" 0 "DISTURBANCE_NOT_PRESENT" ;
VAL_ 1486 PARK_sw000_S3_ussDisturbance 1 "DISTURBANCE_PRESENT" 0 "DISTURBANCE_NOT_PRESENT" ;
VAL_ 1486 PARK_sw000_S4_ussDisturbance 1 "DISTURBANCE_PRESENT" 0 "DISTURBANCE_NOT_PRESENT" ;
VAL_ 1486 PARK_sw000_S5_ussDisturbance 1 "DISTURBANCE_PRESENT" 0 "DISTURBANCE_NOT_PRESENT" ;
VAL_ 1486 PARK_sw000_S6_ussDisturbance 1 "DISTURBANCE_PRESENT" 0 "DISTURBANCE_NOT_PRESENT" ;
VAL_ 1486 PARK_sw000_S7_ussDisturbance 1 "DISTURBANCE_PRESENT" 0 "DISTURBANCE_NOT_PRESENT" ;
VAL_ 1486 PARK_sw000_S8_ussDisturbance 1 "DISTURBANCE_PRESENT" 0 "DISTURBANCE_NOT_PRESENT" ;
VAL_ 1486 PARK_sw000_S9_ussDisturbance 1 "DISTURBANCE_PRESENT" 0 "DISTURBANCE_NOT_PRESENT" ;
VAL_ 1486 PARK_sw000_S10_ussDisturbance 1 "DISTURBANCE_PRESENT" 0 "DISTURBANCE_NOT_PRESENT" ;
VAL_ 1486 PARK_sw000_S11_ussDisturbance 1 "DISTURBANCE_PRESENT" 0 "DISTURBANCE_NOT_PRESENT" ;
VAL_ 1486 PARK_sw000_S12_ussDisturbance 1 "DISTURBANCE_PRESENT" 0 "DISTURBANCE_NOT_PRESENT" ;
VAL_ 1486 PARK_sw000_ussDisturbPasDegMode 5 "PASDEGMODE_MAX" 4 "PASDEGMODE_INTERNALFAULT_ERROR" 3 "PASDEGMODE_SYSTEMDISABLED_ERROR" 2 "PASDEGMODE_ERROR" 1 "PASDEGMODE_DISTURBANCE" 0 "PASDEGMODE_NONE" ;
VAL_ 1486 PARK_sw000_ussDisturbPsxDegMode 5 "PSXDEGMODE_MAX" 4 "PSXSENSORDEGMODE_DISTURBANCE" 3 "PSXDEGMODE_ERROR" 2 "PSXSENSORDEGMODE_ERROR" 1 "PSXCANDEGMODE_ERROR" 0 "PSXDEGMODE_NONE" ;
VAL_ 1486 PARK_sw000_ussDisturbSvaDegMode 3 "SVADEGMODE_MAX" 2 "SVADEGMODE_FULL_ERROR" 1 "SVADEGMODE_PARTIAL_ERROR" 0 "SVADEGMODE_NONE" ;
VAL_ 1486 PARK_sw001_ambTemp 255 "UNKNOWN" ;
VAL_ 1486 PARK_sw001_voltage 255 "UNKNOWN" ;
VAL_ 1486 PARK_sw001_subCode 254 "MID_ADC_E_TOUT_N" 253 "MID_ADC_E_INIT_FAILURE_N" 252 "MID_CAN_E_TIMEOUT_N" 251 "MID_CANIF_E_FULL_TX_BUFFER_N" 250 "MID_CANIF_E_INVALID_DLC_N" 249 "MID_CANIF_E_INVALID_TXPDUID_N" 248 "MID_CANIF_E_STOPPED_N" 247 "MID_CANNM_E_CANIF_TRANSMIT_ERROR_N" 246 "MID_CANNM_E_INIT_FAILED_N" 245 "MID_CANNM_E_NETWORK_TIMEOUT_N" 244 "MID_CANSM_E_BUSOFF_NETWORK_N" 243 "MID_CANTP_E_COM_DIAMANT_N" 242 "MID_ECU_E_EEP_DATAFLASH_LAYOUT_N" 241 "MID_ECU_E_RAM_N" 240 "MID_ECU_E_ROM_N" 239 "MID_FEE_E_LAYOUT_FAILED_N" 238 "MID_NVM_E_CONFIG_FAILED_N" 237 "MID_CAN_DASInvalidData_N" 236 "MID_CAN_C_BUSOFF_N" 235 "MID_NVM_E_INTEGRITY_FAILED_N" 234 "MID_NVM_E_REQ_FAILED_N" 233 "MID_PA_E_ASIC_COM_FAILURE_N" 232 "MID_PA_E_ASIC_HW_FAILURE_N" 231 "MID_PA_E_ENGINE_START_INVALID_N" 230 "MID_PA_E_EPS_STATUS_INVALID_N" 229 "MID_PA_E_GEAR_INVALID_N" 228 "MID_PA_E_LONG_ACC_INVALID_N" 227 "MID_PA_E_OUTSIDE_TEMP_INVALID_N" 226 "MID_CAN_EPASInvalidData_N" 225 "MID_PA_E_SPEED_INVALID_N" 224 "MID_PA_E_SVA_BLOCKED_USS_FL_N" 223 "MID_PA_E_SVA_BLOCKED_USS_FR_N" 222 "MID_PA_E_SVA_BLOCKED_USS_RL_N" 221 "MID_PA_E_SVA_BLOCKED_USS_RR_N" 220 "MID_PA_E_SWA_INVALID_N" 219 "MID_PA_E_SWCPA_APT_MONITOR_FAILURE_N" 218 "MID_PA_E_SWCPA_INHIBIT_HSS_PWRLOCK_N" 217 "MID_PA_E_SWCPA_INIT_FAILURE_N" 216 "MID_PA_E_SWCPA_PARFAILURE_N" 215 "MID_CAN_EPBInvalidData_N" 214 "MID_PA_E_UBAT_HIGH_N" 213 "MID_PA_E_UBAT_LOW_N" 212 "MID_PA_E_USENS_OVERTEMPERATURE_N" 211 "MID_PA_E_USENS_OVERVOLTAGE_N" 210 "MID_PA_E_USENS_SHORT_2_GND_N" 209 "MID_PA_E_USENS_SHORT_2_UBAT_N" 208 "MID_PA_E_USENS_UNDERVOLTAGE_N" 207 "MID_PA_E_USS_01_NO_COM_N" 206 "MID_PA_E_USS_01_OPEN_N" 205 "MID_PA_E_USS_01_RING_TOO_SHORT_N" 204 "MID_PA_E_USS_01_RINGING_TOO_LONG_N" 203 "MID_PA_E_USS_01_SHORT_2_GND_N" 202 "MID_PA_E_USS_01_SHORT_2_USENS_N" 201 "MID_PA_E_USS_01_STATE_COM_VERIFIED_N" 200 "MID_PA_E_USS_01_STATE_OFFSET_N" 199 "MID_PA_E_USS_01_STATE_PROG_N" 198 "MID_PA_E_USS_01_STATE_TYPE_N" 197 "MID_PA_E_USS_02_NO_COM_N" 196 "MID_PA_E_USS_02_OPEN_N" 195 "MID_PA_E_USS_02_RING_TOO_SHORT_N" 194 "MID_PA_E_USS_02_RINGING_TOO_LONG_N" 193 "MID_PA_E_USS_02_SHORT_2_GND_N" 192 "MID_PA_E_USS_02_SHORT_2_USENS_N" 191 "MID_PA_E_USS_02_STATE_COM_VERIFIED_N" 190 "MID_PA_E_USS_02_STATE_OFFSET_N" 189 "MID_PA_E_USS_02_STATE_PROG_N" 188 "MID_PA_E_USS_02_STATE_TYPE_N" 187 "MID_PA_E_USS_03_NO_COM_N" 186 "MID_PA_E_USS_03_OPEN_N" 185 "MID_PA_E_USS_03_RING_TOO_SHORT_N" 184 "MID_PA_E_USS_03_RINGING_TOO_LONG_N" 183 "MID_PA_E_USS_03_SHORT_2_GND_N" 182 "MID_PA_E_USS_03_SHORT_2_USENS_N" 181 "MID_PA_E_USS_03_STATE_COM_VERIFIED_N" 180 "MID_PA_E_USS_03_STATE_OFFSET_N" 179 "MID_PA_E_USS_03_STATE_PROG_N" 178 "MID_PA_E_USS_03_STATE_TYPE_N" 177 "MID_PA_E_USS_04_NO_COM_N" 176 "MID_PA_E_USS_04_OPEN_N" 175 "MID_PA_E_USS_04_RING_TOO_SHORT_N" 174 "MID_PA_E_USS_04_RINGING_TOO_LONG_N" 173 "MID_PA_E_USS_04_SHORT_2_GND_N" 172 "MID_PA_E_USS_04_SHORT_2_USENS_N" 171 "MID_PA_E_USS_04_STATE_COM_VERIFIED_N" 170 "MID_PA_E_USS_04_STATE_OFFSET_N" 169 "MID_PA_E_USS_04_STATE_PROG_N" 168 "MID_PA_E_USS_04_STATE_TYPE_N" 167 "MID_PA_E_USS_05_NO_COM_N" 166 "MID_PA_E_USS_05_OPEN_N" 165 "MID_PA_E_USS_05_RING_TOO_SHORT_N" 164 "MID_PA_E_USS_05_RINGING_TOO_LONG_N" 163 "MID_PA_E_USS_05_SHORT_2_GND_N" 162 "MID_PA_E_USS_05_SHORT_2_USENS_N" 161 "MID_PA_E_USS_05_STATE_COM_VERIFIED_N" 160 "MID_PA_E_USS_05_STATE_OFFSET_N" 159 "MID_PA_E_USS_05_STATE_PROG_N" 158 "MID_PA_E_USS_05_STATE_TYPE_N" 157 "MID_PA_E_USS_06_NO_COM_N" 156 "MID_PA_E_USS_06_OPEN_N" 155 "MID_PA_E_USS_06_RING_TOO_SHORT_N" 154 "MID_PA_E_USS_06_RINGING_TOO_LONG_N" 153 "MID_PA_E_USS_06_SHORT_2_GND_N" 152 "MID_PA_E_USS_06_SHORT_2_USENS_N" 151 "MID_PA_E_USS_06_STATE_COM_VERIFIED_N" 150 "MID_PA_E_USS_06_STATE_OFFSET_N" 149 "MID_PA_E_USS_06_STATE_PROG_N" 148 "MID_PA_E_USS_06_STATE_TYPE_N" 147 "MID_CAN_ESPInvalidData_N" 146 "MID_CAN_GTWInvalidData_N" 145 "MID_CAN_SCCMInvalidData_N" 144 "MID_CAN_DASLossOfCommunication_N" 143 "MID_CAN_EPASLossOfCommunication_N" 142 "MID_CAN_EPBLossOfCommunication_N" 141 "MID_CAN_ESPLossOfCommunication_N" 140 "MID_CAN_GTWLossOfCommunication_N" 139 "MID_CAN_SCCMLossOfCommunication_N" 138 "MID_PA_E_USS_08_NO_COM_N" 137 "MID_PA_E_USS_08_OPEN_N" 136 "MID_PA_E_USS_08_RING_TOO_SHORT_N" 135 "MID_PA_E_USS_08_RINGING_TOO_LONG_N" 134 "MID_PA_E_USS_08_SHORT_2_GND_N" 133 "MID_PA_E_USS_08_SHORT_2_USENS_N" 132 "MID_PA_E_USS_08_STATE_COM_VERIFIED_N" 131 "MID_PA_E_USS_08_STATE_OFFSET_N" 130 "MID_PA_E_USS_08_STATE_PROG_N" 129 "MID_PA_E_USS_08_STATE_TYPE_N" 128 "MID_PA_E_USS_09_NO_COM_N" 127 "MID_PA_E_USS_09_OPEN_N" 126 "MID_PA_E_USS_09_RING_TOO_SHORT_N" 125 "MID_PA_E_USS_09_RINGING_TOO_LONG_N" 124 "MID_PA_E_USS_09_SHORT_2_GND_N" 123 "MID_PA_E_USS_09_SHORT_2_USENS_N" 122 "MID_PA_E_USS_09_STATE_COM_VERIFIED_N" 121 "MID_PA_E_USS_09_STATE_OFFSET_N" 120 "MID_PA_E_USS_09_STATE_PROG_N" 119 "MID_PA_E_USS_09_STATE_TYPE_N" 118 "MID_PA_E_USS_10_NO_COM_N" 117 "MID_PA_E_USS_10_OPEN_N" 116 "MID_PA_E_USS_10_RING_TOO_SHORT_N" 115 "MID_PA_E_USS_10_RINGING_TOO_LONG_N" 114 "MID_PA_E_USS_10_SHORT_2_GND_N" 113 "MID_PA_E_USS_10_SHORT_2_USENS_N" 112 "MID_PA_E_USS_10_STATE_COM_VERIFIED_N" 111 "MID_PA_E_USS_10_STATE_OFFSET_N" 110 "MID_PA_E_USS_10_STATE_PROG_N" 109 "MID_PA_E_USS_10_STATE_TYPE_N" 108 "MID_PA_E_USS_11_NO_COM_N" 107 "MID_PA_E_USS_11_OPEN_N" 106 "MID_PA_E_USS_11_RING_TOO_SHORT_N" 105 "MID_PA_E_USS_11_RINGING_TOO_LONG_N" 104 "MID_PA_E_USS_11_SHORT_2_GND_N" 103 "MID_PA_E_USS_11_SHORT_2_USENS_N" 102 "MID_PA_E_USS_11_STATE_COM_VERIFIED_N" 101 "MID_PA_E_USS_11_STATE_OFFSET_N" 100 "MID_PA_E_USS_11_STATE_PROG_N" 99 "MID_PA_E_USS_11_STATE_TYPE_N" 98 "MID_PA_E_USS_12_NO_COM_N" 97 "MID_PA_E_USS_12_OPEN_N" 96 "MID_PA_E_USS_12_RING_TOO_SHORT_N" 95 "MID_PA_E_USS_12_RINGING_TOO_LONG_N" 94 "MID_PA_E_USS_12_SHORT_2_GND_N" 93 "MID_PA_E_USS_12_SHORT_2_USENS_N" 92 "MID_PA_E_USS_12_STATE_COM_VERIFIED_N" 91 "MID_PA_E_USS_12_STATE_OFFSET_N" 90 "MID_PA_E_USS_12_STATE_PROG_N" 89 "MID_PA_E_USS_12_STATE_TYPE_N" 88 "MID_PA_E_USS_13_NO_COM_N" 87 "MID_PA_E_USS_13_OPEN_N" 86 "MID_PA_E_USS_13_RING_TOO_SHORT_N" 85 "MID_PA_E_USS_13_RINGING_TOO_LONG_N" 84 "MID_PA_E_USS_13_SHORT_2_GND_N" 83 "MID_PA_E_USS_13_SHORT_2_USENS_N" 82 "MID_PA_E_USS_13_STATE_COM_VERIFIED_N" 81 "MID_PA_E_USS_13_STATE_OFFSET_N" 80 "MID_PA_E_USS_13_STATE_PROG_N" 79 "MID_PA_E_USS_13_STATE_TYPE_N" 78 "MID_PA_E_SVA_BLOCKED_USS_ML_N" 77 "MID_PA_E_SVA_BLOCKED_USS_MR_N" 76 "MID_PA_E_WHEEL_DIR_FL_INVALID_N" 75 "MID_PA_E_WHEEL_DIR_FR_INVALID_N" 74 "MID_PA_E_WHEEL_DIR_RL_INVALID_N" 73 "MID_PA_E_WHEEL_DIR_RR_INVALID_N" 72 "MID_PA_E_WHEEL_ROTATION_FL_INVALID_N" 71 "MID_PA_E_WHEEL_ROTATION_FR_INVALID_N" 70 "MID_PA_E_WHEEL_ROTATION_RL_INVALID_N" 69 "MID_PA_E_WHEEL_ROTATION_RR_INVALID_N" 68 "MID_PA_E_WICFL_INVALID_N" 67 "MID_PA_E_WICFR_INVALID_N" 66 "MID_PA_E_WICRL_INVALID_N" 65 "MID_PA_E_WICRR_INVALID_N" 64 "MID_PA_E_YAW_RATE_INVALID_N" 63 "MID_PDUR_E_INIT_FAILED_N" 62 "MID_PDUR_E_PDU_INSTANCE_LOST_N" 61 "MID_COMM_E_NET_START_IND_CHANNEL_0_N" 60 "MID_SPI_E_DMA_TRANSFER_N" 59 "MID_SPI_E_RECEIVE_OVERFLOW_N" 58 "MID_SPI_E_TRANSFER_TIMEOUT_N" 57 "MID_PA_E_VEHDYNINTERVENTION_TIMEOUT_N" 56 "MID_TRAILER_HITCH_PRES_INVALID_N" 55 "MID_PA_E_CL15_STATE_INVALID_N" 54 "MID_PA_E_YAW_RATE_SIGN_INVALID_N" 53 "MID_PA_E_ESP_WIC_FRONT_TIMEOUT_N" 52 "MID_PA_E_SEQ_CALL_FAILURE_N" 51 "MID_PA_E_HMI_FUNCACTIVATION_TIMEOUT_N" 50 "MID_PA_E_LOWBEAM_INVALID_N" 49 "MID_PA_E_ENGINESTART_TIMEOUT_N" 48 "MID_ADC_E_VREF_N" 47 "MID_PA_E_ESP_YAW_TIMEOUT_N" 46 "MID_PA_E_TCM_PRG_TIMEOUT_N" 45 "MID_WDG_E_MODE_SWITCH_FAILED_N" 44 "MID_WDG_E_DISABLE_REJECTED_N" 43 "MID_PA_E_ESP_WHEELDIR_TIMEOUT_N" 42 "MID_PA_E_SWCPA_E_INIT_FAILURE_N" 41 "MID_PA_E_DIR_INDICATOR_INVALID_N" 40 "MID_PA_E_ESP_WIC_TIMEOUT_N" 39 "MID_PA_E_EPS_SWA_TIMEOUT_N" 38 "MID_PA_E_INSTRCLUSTER4_TIMEOUT_N" 37 "MID_PA_E_INSTRCLUSTER5_TIMEOUT_N" 36 "MID_PA_E_INSTRCLUSTER3_TIMEOUT_N" 35 "MID_PA_E_INSTRCLUSTER2_TIMEOUT_N" 34 "MID_PA_E_ASIC_WTD_RESET_N" 33 "MID_PA_E_INSTRCLUSTER1_TIMEOUT_N" 32 "MID_PA_E_ASIC_LOW_VOLT_RESET_N" 31 "MID_PA_E_POWERMODE_TIMEOUT_N" 30 "MID_PA_E_ESP_PS_TIMEOUT_N" 29 "MID_PA_E_ESP_WIC_REAR_TIMEOUT_N" 28 "MID_PA_E_TRAILER_ATTACH_INVALID_N" 27 "MID_PA_E_EXTERNAL_EPS_FAILURE_N" 26 "MID_PA_E_PSX_ACTIVATION_INVALID_N" 25 "MID_PA_E_ESP_WHEELVELO_TIMEOUT_N" 24 "MID_PA_E_ESP_LONGACC_TIMEOUT_N" 23 "MID_PA_E_VEH_DYN_INTERVENTION_INVALID_N" 22 "MID_ZPA_E_PS_MODE_INVALID_N" 21 "MID_ZPA_E_EPS_ERROR_INVALID_N" 20 "MID_ZPA_E1_ESP_PSState_INVALID_N" 19 "MID_ZPA_E2_BdaUss01BlindnessDetect_N" 18 "MID_ZPA_E2_BdaUss02BlindnessDetect_N" 17 "MID_ZPA_E2_BdaUss03BlindnessDetect_N" 16 "MID_ZPA_E2_BdaUss10BlindnessDetect_N" 15 "MID_ZPA_E2_BdaUss05BlindnessDetect_N" 14 "MID_ZPA_E2_BdaUss11BlindnessDetect_N" 13 "MID_ZPA_E2_BdaUss07BlindnessDetect_N" 12 "MID_ZPA_E2_BdaUss12BlindnessDetect_N" 11 "MID_ZPA_E2_BdaUss06BlindnessDetect_N" 10 "MID_ZPA_E2_BdaUss08BlindnessDetect_N" 9 "MID_ZPA_E2_BdaUss13BlindnessDetect_N" 8 "MID_ZPA_E2_BdaUss09BlindnessDetect_N" 7 "MID_ZPA_E2_BdaUss04BlindnessDetect_N" 6 "MID_ZPA_E2_BdaUss14BlindnessDetect_N" 5 "MID_FLS_E_READ_FAILED_N" 4 "MID_FLS_E_COMPARE_FAILED_N" 3 "MID_FLS_E_ERASE_FAILED_N" 2 "MID_FLS_E_WRITE_FAILED_N" 1 "MID_NO_FAULT_N" 0 "MID_INVALID" ;
VAL_ 1486 PARK_sw002_ambTemp 255 "UNKNOWN" ;
VAL_ 1486 PARK_sw002_voltage 255 "UNKNOWN" ;
VAL_ 1486 PARK_sw002_subCode 254 "MID_ADC_E_TOUT_N" 253 "MID_ADC_E_INIT_FAILURE_N" 252 "MID_CAN_E_TIMEOUT_N" 251 "MID_CANIF_E_FULL_TX_BUFFER_N" 250 "MID_CANIF_E_INVALID_DLC_N" 249 "MID_CANIF_E_INVALID_TXPDUID_N" 248 "MID_CANIF_E_STOPPED_N" 247 "MID_CANNM_E_CANIF_TRANSMIT_ERROR_N" 246 "MID_CANNM_E_INIT_FAILED_N" 245 "MID_CANNM_E_NETWORK_TIMEOUT_N" 244 "MID_CANSM_E_BUSOFF_NETWORK_N" 243 "MID_CANTP_E_COM_DIAMANT_N" 242 "MID_ECU_E_EEP_DATAFLASH_LAYOUT_N" 241 "MID_ECU_E_RAM_N" 240 "MID_ECU_E_ROM_N" 239 "MID_FEE_E_LAYOUT_FAILED_N" 238 "MID_NVM_E_CONFIG_FAILED_N" 237 "MID_CAN_DASInvalidData_N" 236 "MID_CAN_C_BUSOFF_N" 235 "MID_NVM_E_INTEGRITY_FAILED_N" 234 "MID_NVM_E_REQ_FAILED_N" 233 "MID_PA_E_ASIC_COM_FAILURE_N" 232 "MID_PA_E_ASIC_HW_FAILURE_N" 231 "MID_PA_E_ENGINE_START_INVALID_N" 230 "MID_PA_E_EPS_STATUS_INVALID_N" 229 "MID_PA_E_GEAR_INVALID_N" 228 "MID_PA_E_LONG_ACC_INVALID_N" 227 "MID_PA_E_OUTSIDE_TEMP_INVALID_N" 226 "MID_CAN_EPASInvalidData_N" 225 "MID_PA_E_SPEED_INVALID_N" 224 "MID_PA_E_SVA_BLOCKED_USS_FL_N" 223 "MID_PA_E_SVA_BLOCKED_USS_FR_N" 222 "MID_PA_E_SVA_BLOCKED_USS_RL_N" 221 "MID_PA_E_SVA_BLOCKED_USS_RR_N" 220 "MID_PA_E_SWA_INVALID_N" 219 "MID_PA_E_SWCPA_APT_MONITOR_FAILURE_N" 218 "MID_PA_E_SWCPA_INHIBIT_HSS_PWRLOCK_N" 217 "MID_PA_E_SWCPA_INIT_FAILURE_N" 216 "MID_PA_E_SWCPA_PARFAILURE_N" 215 "MID_CAN_EPBInvalidData_N" 214 "MID_PA_E_UBAT_HIGH_N" 213 "MID_PA_E_UBAT_LOW_N" 212 "MID_PA_E_USENS_OVERTEMPERATURE_N" 211 "MID_PA_E_USENS_OVERVOLTAGE_N" 210 "MID_PA_E_USENS_SHORT_2_GND_N" 209 "MID_PA_E_USENS_SHORT_2_UBAT_N" 208 "MID_PA_E_USENS_UNDERVOLTAGE_N" 207 "MID_PA_E_USS_01_NO_COM_N" 206 "MID_PA_E_USS_01_OPEN_N" 205 "MID_PA_E_USS_01_RING_TOO_SHORT_N" 204 "MID_PA_E_USS_01_RINGING_TOO_LONG_N" 203 "MID_PA_E_USS_01_SHORT_2_GND_N" 202 "MID_PA_E_USS_01_SHORT_2_USENS_N" 201 "MID_PA_E_USS_01_STATE_COM_VERIFIED_N" 200 "MID_PA_E_USS_01_STATE_OFFSET_N" 199 "MID_PA_E_USS_01_STATE_PROG_N" 198 "MID_PA_E_USS_01_STATE_TYPE_N" 197 "MID_PA_E_USS_02_NO_COM_N" 196 "MID_PA_E_USS_02_OPEN_N" 195 "MID_PA_E_USS_02_RING_TOO_SHORT_N" 194 "MID_PA_E_USS_02_RINGING_TOO_LONG_N" 193 "MID_PA_E_USS_02_SHORT_2_GND_N" 192 "MID_PA_E_USS_02_SHORT_2_USENS_N" 191 "MID_PA_E_USS_02_STATE_COM_VERIFIED_N" 190 "MID_PA_E_USS_02_STATE_OFFSET_N" 189 "MID_PA_E_USS_02_STATE_PROG_N" 188 "MID_PA_E_USS_02_STATE_TYPE_N" 187 "MID_PA_E_USS_03_NO_COM_N" 186 "MID_PA_E_USS_03_OPEN_N" 185 "MID_PA_E_USS_03_RING_TOO_SHORT_N" 184 "MID_PA_E_USS_03_RINGING_TOO_LONG_N" 183 "MID_PA_E_USS_03_SHORT_2_GND_N" 182 "MID_PA_E_USS_03_SHORT_2_USENS_N" 181 "MID_PA_E_USS_03_STATE_COM_VERIFIED_N" 180 "MID_PA_E_USS_03_STATE_OFFSET_N" 179 "MID_PA_E_USS_03_STATE_PROG_N" 178 "MID_PA_E_USS_03_STATE_TYPE_N" 177 "MID_PA_E_USS_04_NO_COM_N" 176 "MID_PA_E_USS_04_OPEN_N" 175 "MID_PA_E_USS_04_RING_TOO_SHORT_N" 174 "MID_PA_E_USS_04_RINGING_TOO_LONG_N" 173 "MID_PA_E_USS_04_SHORT_2_GND_N" 172 "MID_PA_E_USS_04_SHORT_2_USENS_N" 171 "MID_PA_E_USS_04_STATE_COM_VERIFIED_N" 170 "MID_PA_E_USS_04_STATE_OFFSET_N" 169 "MID_PA_E_USS_04_STATE_PROG_N" 168 "MID_PA_E_USS_04_STATE_TYPE_N" 167 "MID_PA_E_USS_05_NO_COM_N" 166 "MID_PA_E_USS_05_OPEN_N" 165 "MID_PA_E_USS_05_RING_TOO_SHORT_N" 164 "MID_PA_E_USS_05_RINGING_TOO_LONG_N" 163 "MID_PA_E_USS_05_SHORT_2_GND_N" 162 "MID_PA_E_USS_05_SHORT_2_USENS_N" 161 "MID_PA_E_USS_05_STATE_COM_VERIFIED_N" 160 "MID_PA_E_USS_05_STATE_OFFSET_N" 159 "MID_PA_E_USS_05_STATE_PROG_N" 158 "MID_PA_E_USS_05_STATE_TYPE_N" 157 "MID_PA_E_USS_06_NO_COM_N" 156 "MID_PA_E_USS_06_OPEN_N" 155 "MID_PA_E_USS_06_RING_TOO_SHORT_N" 154 "MID_PA_E_USS_06_RINGING_TOO_LONG_N" 153 "MID_PA_E_USS_06_SHORT_2_GND_N" 152 "MID_PA_E_USS_06_SHORT_2_USENS_N" 151 "MID_PA_E_USS_06_STATE_COM_VERIFIED_N" 150 "MID_PA_E_USS_06_STATE_OFFSET_N" 149 "MID_PA_E_USS_06_STATE_PROG_N" 148 "MID_PA_E_USS_06_STATE_TYPE_N" 147 "MID_CAN_ESPInvalidData_N" 146 "MID_CAN_GTWInvalidData_N" 145 "MID_CAN_SCCMInvalidData_N" 144 "MID_CAN_DASLossOfCommunication_N" 143 "MID_CAN_EPASLossOfCommunication_N" 142 "MID_CAN_EPBLossOfCommunication_N" 141 "MID_CAN_ESPLossOfCommunication_N" 140 "MID_CAN_GTWLossOfCommunication_N" 139 "MID_CAN_SCCMLossOfCommunication_N" 138 "MID_PA_E_USS_08_NO_COM_N" 137 "MID_PA_E_USS_08_OPEN_N" 136 "MID_PA_E_USS_08_RING_TOO_SHORT_N" 135 "MID_PA_E_USS_08_RINGING_TOO_LONG_N" 134 "MID_PA_E_USS_08_SHORT_2_GND_N" 133 "MID_PA_E_USS_08_SHORT_2_USENS_N" 132 "MID_PA_E_USS_08_STATE_COM_VERIFIED_N" 131 "MID_PA_E_USS_08_STATE_OFFSET_N" 130 "MID_PA_E_USS_08_STATE_PROG_N" 129 "MID_PA_E_USS_08_STATE_TYPE_N" 128 "MID_PA_E_USS_09_NO_COM_N" 127 "MID_PA_E_USS_09_OPEN_N" 126 "MID_PA_E_USS_09_RING_TOO_SHORT_N" 125 "MID_PA_E_USS_09_RINGING_TOO_LONG_N" 124 "MID_PA_E_USS_09_SHORT_2_GND_N" 123 "MID_PA_E_USS_09_SHORT_2_USENS_N" 122 "MID_PA_E_USS_09_STATE_COM_VERIFIED_N" 121 "MID_PA_E_USS_09_STATE_OFFSET_N" 120 "MID_PA_E_USS_09_STATE_PROG_N" 119 "MID_PA_E_USS_09_STATE_TYPE_N" 118 "MID_PA_E_USS_10_NO_COM_N" 117 "MID_PA_E_USS_10_OPEN_N" 116 "MID_PA_E_USS_10_RING_TOO_SHORT_N" 115 "MID_PA_E_USS_10_RINGING_TOO_LONG_N" 114 "MID_PA_E_USS_10_SHORT_2_GND_N" 113 "MID_PA_E_USS_10_SHORT_2_USENS_N" 112 "MID_PA_E_USS_10_STATE_COM_VERIFIED_N" 111 "MID_PA_E_USS_10_STATE_OFFSET_N" 110 "MID_PA_E_USS_10_STATE_PROG_N" 109 "MID_PA_E_USS_10_STATE_TYPE_N" 108 "MID_PA_E_USS_11_NO_COM_N" 107 "MID_PA_E_USS_11_OPEN_N" 106 "MID_PA_E_USS_11_RING_TOO_SHORT_N" 105 "MID_PA_E_USS_11_RINGING_TOO_LONG_N" 104 "MID_PA_E_USS_11_SHORT_2_GND_N" 103 "MID_PA_E_USS_11_SHORT_2_USENS_N" 102 "MID_PA_E_USS_11_STATE_COM_VERIFIED_N" 101 "MID_PA_E_USS_11_STATE_OFFSET_N" 100 "MID_PA_E_USS_11_STATE_PROG_N" 99 "MID_PA_E_USS_11_STATE_TYPE_N" 98 "MID_PA_E_USS_12_NO_COM_N" 97 "MID_PA_E_USS_12_OPEN_N" 96 "MID_PA_E_USS_12_RING_TOO_SHORT_N" 95 "MID_PA_E_USS_12_RINGING_TOO_LONG_N" 94 "MID_PA_E_USS_12_SHORT_2_GND_N" 93 "MID_PA_E_USS_12_SHORT_2_USENS_N" 92 "MID_PA_E_USS_12_STATE_COM_VERIFIED_N" 91 "MID_PA_E_USS_12_STATE_OFFSET_N" 90 "MID_PA_E_USS_12_STATE_PROG_N" 89 "MID_PA_E_USS_12_STATE_TYPE_N" 88 "MID_PA_E_USS_13_NO_COM_N" 87 "MID_PA_E_USS_13_OPEN_N" 86 "MID_PA_E_USS_13_RING_TOO_SHORT_N" 85 "MID_PA_E_USS_13_RINGING_TOO_LONG_N" 84 "MID_PA_E_USS_13_SHORT_2_GND_N" 83 "MID_PA_E_USS_13_SHORT_2_USENS_N" 82 "MID_PA_E_USS_13_STATE_COM_VERIFIED_N" 81 "MID_PA_E_USS_13_STATE_OFFSET_N" 80 "MID_PA_E_USS_13_STATE_PROG_N" 79 "MID_PA_E_USS_13_STATE_TYPE_N" 78 "MID_PA_E_SVA_BLOCKED_USS_ML_N" 77 "MID_PA_E_SVA_BLOCKED_USS_MR_N" 76 "MID_PA_E_WHEEL_DIR_FL_INVALID_N" 75 "MID_PA_E_WHEEL_DIR_FR_INVALID_N" 74 "MID_PA_E_WHEEL_DIR_RL_INVALID_N" 73 "MID_PA_E_WHEEL_DIR_RR_INVALID_N" 72 "MID_PA_E_WHEEL_ROTATION_FL_INVALID_N" 71 "MID_PA_E_WHEEL_ROTATION_FR_INVALID_N" 70 "MID_PA_E_WHEEL_ROTATION_RL_INVALID_N" 69 "MID_PA_E_WHEEL_ROTATION_RR_INVALID_N" 68 "MID_PA_E_WICFL_INVALID_N" 67 "MID_PA_E_WICFR_INVALID_N" 66 "MID_PA_E_WICRL_INVALID_N" 65 "MID_PA_E_WICRR_INVALID_N" 64 "MID_PA_E_YAW_RATE_INVALID_N" 63 "MID_PDUR_E_INIT_FAILED_N" 62 "MID_PDUR_E_PDU_INSTANCE_LOST_N" 61 "MID_COMM_E_NET_START_IND_CHANNEL_0_N" 60 "MID_SPI_E_DMA_TRANSFER_N" 59 "MID_SPI_E_RECEIVE_OVERFLOW_N" 58 "MID_SPI_E_TRANSFER_TIMEOUT_N" 57 "MID_PA_E_VEHDYNINTERVENTION_TIMEOUT_N" 56 "MID_TRAILER_HITCH_PRES_INVALID_N" 55 "MID_PA_E_CL15_STATE_INVALID_N" 54 "MID_PA_E_YAW_RATE_SIGN_INVALID_N" 53 "MID_PA_E_ESP_WIC_FRONT_TIMEOUT_N" 52 "MID_PA_E_SEQ_CALL_FAILURE_N" 51 "MID_PA_E_HMI_FUNCACTIVATION_TIMEOUT_N" 50 "MID_PA_E_LOWBEAM_INVALID_N" 49 "MID_PA_E_ENGINESTART_TIMEOUT_N" 48 "MID_ADC_E_VREF_N" 47 "MID_PA_E_ESP_YAW_TIMEOUT_N" 46 "MID_PA_E_TCM_PRG_TIMEOUT_N" 45 "MID_WDG_E_MODE_SWITCH_FAILED_N" 44 "MID_WDG_E_DISABLE_REJECTED_N" 43 "MID_PA_E_ESP_WHEELDIR_TIMEOUT_N" 42 "MID_PA_E_SWCPA_E_INIT_FAILURE_N" 41 "MID_PA_E_DIR_INDICATOR_INVALID_N" 40 "MID_PA_E_ESP_WIC_TIMEOUT_N" 39 "MID_PA_E_EPS_SWA_TIMEOUT_N" 38 "MID_PA_E_INSTRCLUSTER4_TIMEOUT_N" 37 "MID_PA_E_INSTRCLUSTER5_TIMEOUT_N" 36 "MID_PA_E_INSTRCLUSTER3_TIMEOUT_N" 35 "MID_PA_E_INSTRCLUSTER2_TIMEOUT_N" 34 "MID_PA_E_ASIC_WTD_RESET_N" 33 "MID_PA_E_INSTRCLUSTER1_TIMEOUT_N" 32 "MID_PA_E_ASIC_LOW_VOLT_RESET_N" 31 "MID_PA_E_POWERMODE_TIMEOUT_N" 30 "MID_PA_E_ESP_PS_TIMEOUT_N" 29 "MID_PA_E_ESP_WIC_REAR_TIMEOUT_N" 28 "MID_PA_E_TRAILER_ATTACH_INVALID_N" 27 "MID_PA_E_EXTERNAL_EPS_FAILURE_N" 26 "MID_PA_E_PSX_ACTIVATION_INVALID_N" 25 "MID_PA_E_ESP_WHEELVELO_TIMEOUT_N" 24 "MID_PA_E_ESP_LONGACC_TIMEOUT_N" 23 "MID_PA_E_VEH_DYN_INTERVENTION_INVALID_N" 22 "MID_ZPA_E_PS_MODE_INVALID_N" 21 "MID_ZPA_E_EPS_ERROR_INVALID_N" 20 "MID_ZPA_E1_ESP_PSState_INVALID_N" 19 "MID_ZPA_E2_BdaUss01BlindnessDetect_N" 18 "MID_ZPA_E2_BdaUss02BlindnessDetect_N" 17 "MID_ZPA_E2_BdaUss03BlindnessDetect_N" 16 "MID_ZPA_E2_BdaUss10BlindnessDetect_N" 15 "MID_ZPA_E2_BdaUss05BlindnessDetect_N" 14 "MID_ZPA_E2_BdaUss11BlindnessDetect_N" 13 "MID_ZPA_E2_BdaUss07BlindnessDetect_N" 12 "MID_ZPA_E2_BdaUss12BlindnessDetect_N" 11 "MID_ZPA_E2_BdaUss06BlindnessDetect_N" 10 "MID_ZPA_E2_BdaUss08BlindnessDetect_N" 9 "MID_ZPA_E2_BdaUss13BlindnessDetect_N" 8 "MID_ZPA_E2_BdaUss09BlindnessDetect_N" 7 "MID_ZPA_E2_BdaUss04BlindnessDetect_N" 6 "MID_ZPA_E2_BdaUss14BlindnessDetect_N" 5 "MID_FLS_E_READ_FAILED_N" 4 "MID_FLS_E_COMPARE_FAILED_N" 3 "MID_FLS_E_ERASE_FAILED_N" 2 "MID_FLS_E_WRITE_FAILED_N" 1 "MID_NO_FAULT_N" 0 "MID_INVALID" ;
VAL_ 1486 PARK_sw003_ambTemp 255 "UNKNOWN" ;
VAL_ 1486 PARK_sw003_voltage 255 "UNKNOWN" ;
SIG_GROUP_ 1420 IC_alertDataW0 1 : IC_canAddress IC_canErrorType IC_canRxErrorCount IC_canTxErrorCount;
SIG_GROUP_ 1420 IC_alertDataW1 1 : IC_canErrorWord1;
SIG_GROUP_ 1420 IC_alertDataW2 1 : IC_canErrorWord2;
SIG_GROUP_ 1420 IC_alertIDWord 1 : IC_alertID IC_alertType;
SIG_GROUP_ 908 IC_faultMatrix 1 : IC_f001_unused IC_f002_unused IC_f003_unused IC_f004_unused IC_f005_unused IC_f006_unused IC_f007_unused IC_f008_unused IC_f009_unused IC_f010_unused IC_f011_unused IC_f012_unused IC_f013_unused IC_f014_unused IC_f015_unused IC_f016_unused;
SIG_GROUP_ 796 IC_warningMatrix 1 : IC_w001_CAN_RX IC_w002_CAN_TX IC_w003_CAN_ERR IC_w004_CAN_OVERRUN IC_w005_FIRMWARE IC_w006_FPGA_ERROR IC_w007_WATCHDOG_RESET IC_w008_MEMORY_ERROR IC_w009_SPI_OPEN IC_w010_SPI_READ IC_w011_CAN_RX_ERRCNT IC_w012_CAN_TX_ERRCNT IC_w013_OVERTEMP_OFF IC_w014_unused IC_w015_unused IC_w016_unused;
SIG_GROUP_ 757 SBW_Disp_Rq_ISM 1 : SBW_Beep_Rq_ISM SBW_Msg_Disp_Rq_ISM TSL_MtnLk1_Disp_Rq_ISM TSL_MtnLk2_Disp_Rq_ISM TSL_MtnLk3_Disp_Rq_ISM TSL_MtnLk4_Disp_Rq_ISM TxDrvPosn_Disp_Rq_ISM;
